VERSION ""

NS_ :

BS_:

BU_: DSAU vHS_M SHVU_RR DPSS AMP ICC RLPSM APSM RWPC RRHV RRPSM CGW_CCU APSS ATS RLHV FPM RDC PSM ASAU

BO_ 1141 Ast_SHVU_01_200ms: 8 APSM
 SG_ Ast_SHVU_SeatOptSta : 0|3@1+ (1,0) [0|0] ""  CGW_CCU
 SG_ Ast_SHVU_HtSwHiIndSta : 12|2@1+ (1,0) [0|0] ""  CGW_CCU
 SG_ Ast_SHVU_HtSwMidIndSta : 14|2@1+ (1,0) [0|0] ""  CGW_CCU
 SG_ Ast_SHVU_HtSwLowIndSta : 16|2@1+ (1,0) [0|0] ""  CGW_CCU
 SG_ Ast_SHVU_VntSwHiIndSta : 18|2@1+ (1,0) [0|0] ""  CGW_CCU
 SG_ Ast_SHVU_VntSwMidIndSta : 20|2@1+ (1,0) [0|0] ""  CGW_CCU
 SG_ Ast_SHVU_VntSwLowIndSta : 22|2@1+ (1,0) [0|0] ""  CGW_CCU
 SG_ Ast_SHVU_HtBlcUSMSta : 26|4@1+ (1,0) [0|0] ""  CGW_CCU
 SG_ Ast_SHVU_SeatHtOperSta : 3|4@1+ (1,0) [0|0] ""  CGW_CCU
 SG_ Ast_SHVU_SeatOptSta_RHD : 32|3@1+ (1,0) [0|0] ""  CGW_CCU
 SG_ Ast_SHVU_SeatHtOperSta_RHD : 35|4@1+ (1,0) [0|0] ""  CGW_CCU
 SG_ Ast_SHVU_HtSwHiIndSta_RHD : 44|2@1+ (1,0) [0|0] ""  CGW_CCU
 SG_ Ast_SHVU_HtSwMidIndSta_RHD : 46|2@1+ (1,0) [0|0] ""  CGW_CCU
 SG_ Ast_SHVU_HtSwLowIndSta_RHD : 48|2@1+ (1,0) [0|0] ""  CGW_CCU
 SG_ Ast_SHVU_VntSwHiIndSta_RHD : 50|2@1+ (1,0) [0|0] ""  CGW_CCU
 SG_ Ast_SHVU_VntSwMidIndSta_RHD : 52|2@1+ (1,0) [0|0] ""  CGW_CCU
 SG_ Ast_SHVU_VntSwLowIndSta_RHD : 54|2@1+ (1,0) [0|0] ""  CGW_CCU

BO_ 543 ATS_02_200ms: 8 ATS
 SG_ ATS_AstStSldFwdBtn : 16|2@1+ (1,0) [0|0] ""  APSM
 SG_ ATS_AstStSldBwdBtn : 18|2@1+ (1,0) [0|0] ""  APSM
 SG_ ATS_AstStRclFwdBtn : 20|2@1+ (1,0) [0|0] ""  APSM
 SG_ ATS_AstStRclBwdBtn : 22|2@1+ (1,0) [0|0] ""  APSM
 SG_ ATS_AstStHgtUpBtn : 28|2@1+ (1,0) [0|0] ""  APSM
 SG_ ATS_AstStHgtDnBtn : 30|2@1+ (1,0) [0|0] ""  APSM
 SG_ ATS_AstStHRestUpBtn : 40|2@1+ (1,0) [0|0] ""  APSM
 SG_ ATS_AstStHRestDnBtn : 42|2@1+ (1,0) [0|0] ""  APSM
 SG_ ATS_AstStHRestFwdBtn : 44|2@1+ (1,0) [0|0] ""  APSM
 SG_ ATS_AstStHRestBwdBtn : 46|2@1+ (1,0) [0|0] ""  APSM
 SG_ ATS_AstStHRestFldBtn : 48|2@1+ (1,0) [0|0] ""  APSM
 SG_ ATS_AstStHRestUnFldBtn : 50|2@1+ (1,0) [0|0] ""  APSM
 SG_ ATS_AstStRseFwdBtn : 52|2@1+ (1,0) [0|0] ""  APSM
 SG_ ATS_AstStRseBwdBtn : 54|2@1+ (1,0) [0|0] ""  APSM
 SG_ ATS_AstStFRestFldBtn : 56|2@1+ (1,0) [0|0] ""  APSM
 SG_ ATS_AstStFRestUnFldBtn : 58|2@1+ (1,0) [0|0] ""  APSM
 SG_ ATS_AstTltUpBtn : 60|2@1+ (1,0) [0|0] ""  APSM
 SG_ ATS_AstTltDnBtn : 62|2@1+ (1,0) [0|0] ""  APSM

BO_ 2315421185 HU_FPM_PE_00_1: 8 CGW_CCU
 SG_ AVN_ReadyToSendData : 0|2@1+ (1,0) [0|0] ""  FPM
 SG_ AVN_ISKLearnState : 2|3@1+ (1,0) [0|0] ""  FPM

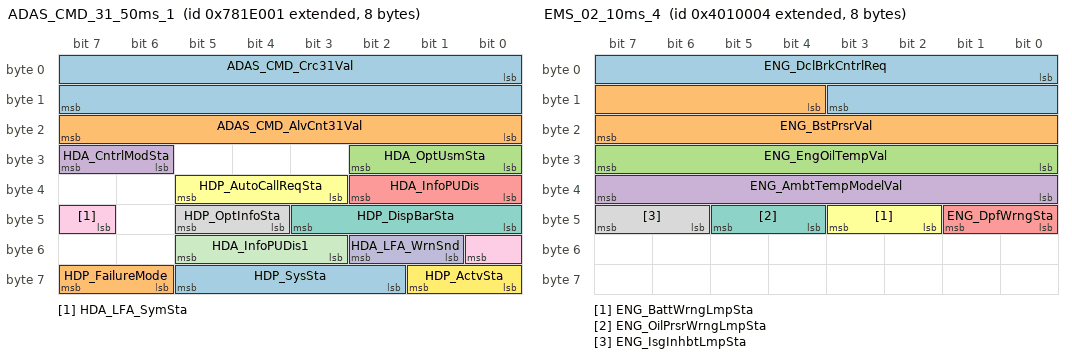
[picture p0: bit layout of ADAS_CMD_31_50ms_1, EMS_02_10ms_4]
BO_ 2273435649 ADAS_CMD_31_50ms_1: 8 CGW_CCU
 SG_ ADAS_CMD_Crc31Val : 0|16@1+ (1,0) [0|0] ""  Vector__XXX
 SG_ ADAS_CMD_AlvCnt31Val : 16|8@1+ (1,0) [0|0] ""  Vector__XXX
 SG_ HDA_OptUsmSta : 24|3@1+ (1,0) [0|0] ""  Vector__XXX
 SG_ HDA_CntrlModSta : 30|2@1+ (1,0) [0|0] ""  Vector__XXX
 SG_ HDA_InfoPUDis : 32|3@1+ (1,0) [0|0] ""  AMP
 SG_ HDP_AutoCallReqSta : 35|3@1+ (1,0) [0|0] ""  Vector__XXX
 SG_ HDP_DispBarSta : 40|4@1+ (1,0) [0|0] ""  Vector__XXX
 SG_ HDP_OptInfoSta : 44|2@1+ (1,0) [0|0] ""  Vector__XXX
 SG_ HDA_LFA_SymSta : 47|2@1+ (1,0) [0|0] ""  Vector__XXX
 SG_ HDA_LFA_WrnSnd : 49|2@1+ (1,0) [0|0] ""  Vector__XXX
 SG_ HDA_InfoPUDis1 : 51|3@1+ (1,0) [0|0] ""  AMP
 SG_ HDP_ActvSta : 56|2@1+ (1,0) [0|0] ""  Vector__XXX
 SG_ HDP_SysSta : 58|4@1+ (1,0) [0|0] ""  Vector__XXX
 SG_ HDP_FailureMode : 62|2@1+ (1,0) [0|0] ""  Vector__XXX

BO_ 2214658052 EMS_02_10ms_4: 8 CGW_CCU
 SG_ ENG_DclBrkCntrlReq : 0|12@1+ (0.001,-4.094) [0|0] "m/s^2"  Vector__XXX
 SG_ ENG_BstPrsrVal : 12|12@1+ (1.322,0) [0|0] "hPa"  Vector__XXX
 SG_ ENG_EngOilTempVal : 24|8@1+ (0.75,-40) [0|0] "℃"  Vector__XXX
 SG_ ENG_AmbtTempModelVal : 32|8@1+ (0.5,-41) [0|0] "℃"  Vector__XXX
 SG_ ENG_DpfWrngSta : 40|2@1+ (1,0) [0|0] ""  Vector__XXX
 SG_ ENG_BattWrngLmpSta : 42|2@1+ (1,0) [0|0] ""  Vector__XXX
 SG_ ENG_OilPrsrWrngLmpSta : 44|2@1+ (1,0) [0|0] ""  Vector__XXX
 SG_ ENG_IsgInhbtLmpSta : 46|2@1+ (1,0) [0|0] ""  Vector__XXX

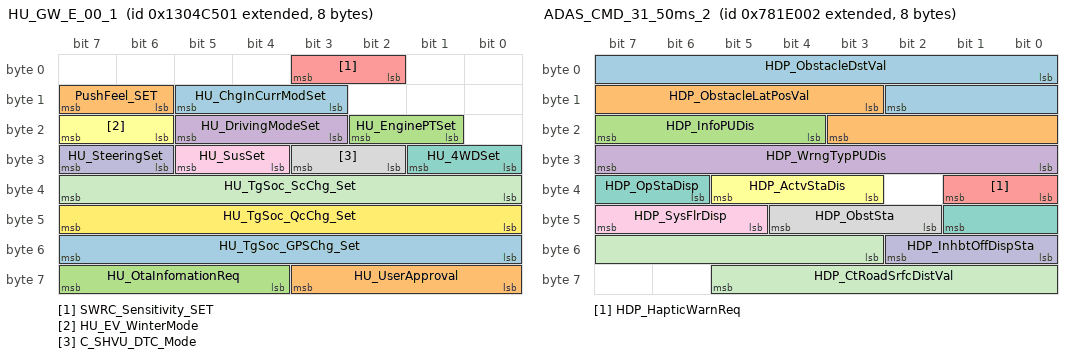
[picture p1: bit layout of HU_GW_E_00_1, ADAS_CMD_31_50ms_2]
BO_ 2466563329 HU_GW_E_00_1: 8 CGW_CCU
 SG_ HU_ChgInCurrModSet : 11|3@1+ (1,0) [0|0] ""  Vector__XXX
 SG_ PushFeel_SET : 14|2@1+ (1,0) [0|0] ""  Vector__XXX
 SG_ HU_EnginePTSet : 17|2@1+ (1,0) [0|0] ""  Vector__XXX
 SG_ HU_DrivingModeSet : 19|3@1+ (1,0) [0|0] ""  Vector__XXX
 SG_ SWRC_Sensitivity_SET : 2|2@1+ (1,0) [0|0] ""  Vector__XXX
 SG_ HU_EV_WinterMode : 22|2@1+ (1,0) [0|0] ""  Vector__XXX
 SG_ HU_4WDSet : 24|2@1+ (1,0) [0|0] ""  Vector__XXX
 SG_ C_SHVU_DTC_Mode : 26|2@1+ (1,0) [0|0] ""  SHVU_RR,ATS
 SG_ HU_SusSet : 28|2@1+ (1,0) [0|0] ""  Vector__XXX
 SG_ HU_SteeringSet : 30|2@1+ (1,0) [0|0] ""  Vector__XXX
 SG_ HU_TgSoc_ScChg_Set : 32|8@1+ (0.5,0) [0|100] "%"  Vector__XXX
 SG_ HU_TgSoc_QcChg_Set : 40|8@1+ (0.5,0) [0|100] "%"  Vector__XXX
 SG_ HU_TgSoc_GPSChg_Set : 48|8@1+ (0.5,0) [0|100] "%"  Vector__XXX
 SG_ HU_UserApproval : 56|4@1+ (1,0) [0|0] ""  Vector__XXX
 SG_ HU_OtaInfomationReq : 60|4@1+ (1,0) [0|0] ""  Vector__XXX

BO_ 2273435650 ADAS_CMD_31_50ms_2: 8 CGW_CCU
 SG_ HDP_ObstacleDstVal : 0|11@1+ (0.1,0) [0|0] "m"  Vector__XXX
 SG_ HDP_ObstacleLatPosVal : 11|9@1+ (0.1,-20) [0|0] "m"  Vector__XXX
 SG_ HDP_InfoPUDis : 20|4@1+ (1,0) [0|0] ""  Vector__XXX
 SG_ HDP_WrngTypPUDis : 24|8@1+ (1,0) [0|0] ""  Vector__XXX
 SG_ HDP_HapticWarnReq : 32|2@1+ (1,0) [0|0] ""  DSAU
 SG_ HDP_ActvStaDis : 35|3@1+ (1,0) [0|0] ""  Vector__XXX
 SG_ HDP_OpStaDisp : 38|4@1+ (1,0) [0|0] ""  Vector__XXX
 SG_ HDP_ObstSta : 42|3@1+ (1,0) [0|0] ""  Vector__XXX
 SG_ HDP_SysFlrDisp : 45|3@1+ (1,0) [0|0] ""  Vector__XXX
 SG_ HDP_InhbtOffDispSta : 48|3@1+ (1,0) [0|0] ""  Vector__XXX
 SG_ HDP_CtRoadSrfcDistVal : 51|11@1+ (1,0) [0|0] ""  Vector__XXX

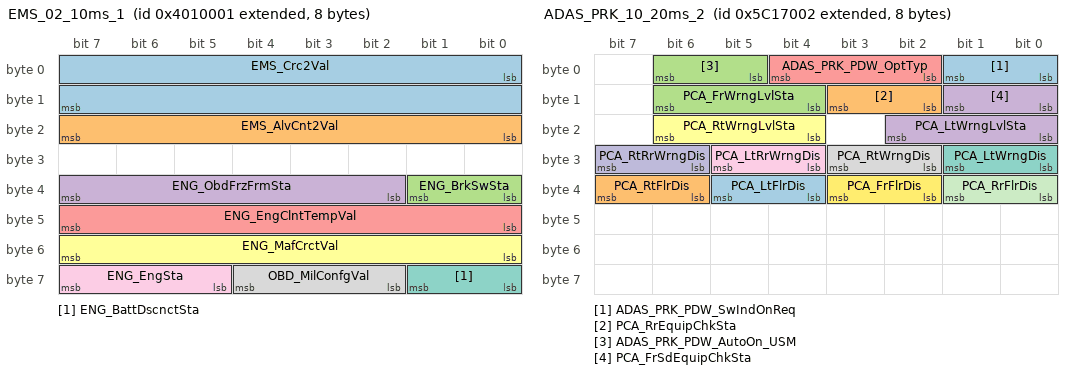
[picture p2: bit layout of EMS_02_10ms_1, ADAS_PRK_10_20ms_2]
BO_ 2214658049 EMS_02_10ms_1: 8 CGW_CCU
 SG_ EMS_Crc2Val : 0|16@1+ (1,0) [0|0] ""  Vector__XXX
 SG_ EMS_AlvCnt2Val : 16|8@1+ (1,0) [0|0] ""  Vector__XXX
 SG_ ENG_BrkSwSta : 32|2@1+ (1,0) [0|0] ""  ICC
 SG_ ENG_ObdFrzFrmSta : 34|6@1+ (1,0) [0|0] ""  Vector__XXX
 SG_ ENG_EngClntTempVal : 40|8@1+ (0.75,-48) [0|0] "℃"  Vector__XXX
 SG_ ENG_MafCrctVal : 48|8@1+ (0.00781,0) [0|0] ""  Vector__XXX
 SG_ ENG_BattDscnctSta : 56|2@1+ (1,0) [0|0] ""  Vector__XXX
 SG_ OBD_MilConfgVal : 58|3@1+ (1,0) [0|0] ""  Vector__XXX
 SG_ ENG_EngSta : 61|3@1+ (1,0) [0|0] ""  RWPC,PSM,APSM,RLPSM,RRPSM,RLHV,RRHV,SHVU_RR,RDC,DPSS

BO_ 2244046850 ADAS_PRK_10_20ms_2: 8 CGW_CCU
 SG_ ADAS_PRK_PDW_SwIndOnReq : 0|2@1+ (1,0) [0|0] ""  Vector__XXX
 SG_ PCA_RrEquipChkSta : 10|2@1+ (1,0) [0|0] ""  Vector__XXX
 SG_ PCA_FrWrngLvlSta : 12|3@1+ (1,0) [0|0] ""  Vector__XXX
 SG_ PCA_LtWrngLvlSta : 16|3@1+ (1,0) [0|0] ""  Vector__XXX
 SG_ ADAS_PRK_PDW_OptTyp : 2|3@1+ (1,0) [0|0] ""  Vector__XXX
 SG_ PCA_RtWrngLvlSta : 20|3@1+ (1,0) [0|0] ""  Vector__XXX
 SG_ PCA_LtWrngDis : 24|2@1+ (1,0) [0|0] ""  Vector__XXX
 SG_ PCA_RtWrngDis : 26|2@1+ (1,0) [0|0] ""  Vector__XXX
 SG_ PCA_LtRrWrngDis : 28|2@1+ (1,0) [0|0] ""  Vector__XXX
 SG_ PCA_RtRrWrngDis : 30|2@1+ (1,0) [0|0] ""  Vector__XXX
 SG_ PCA_RrFlrDis : 32|2@1+ (1,0) [0|0] ""  Vector__XXX
 SG_ PCA_FrFlrDis : 34|2@1+ (1,0) [0|0] ""  Vector__XXX
 SG_ PCA_LtFlrDis : 36|2@1+ (1,0) [0|0] ""  Vector__XXX
 SG_ PCA_RtFlrDis : 38|2@1+ (1,0) [0|0] ""  Vector__XXX
 SG_ ADAS_PRK_PDW_AutoOn_USM : 5|2@1+ (1,0) [0|0] ""  Vector__XXX
 SG_ PCA_FrSdEquipChkSta : 8|2@1+ (1,0) [0|0] ""  Vector__XXX

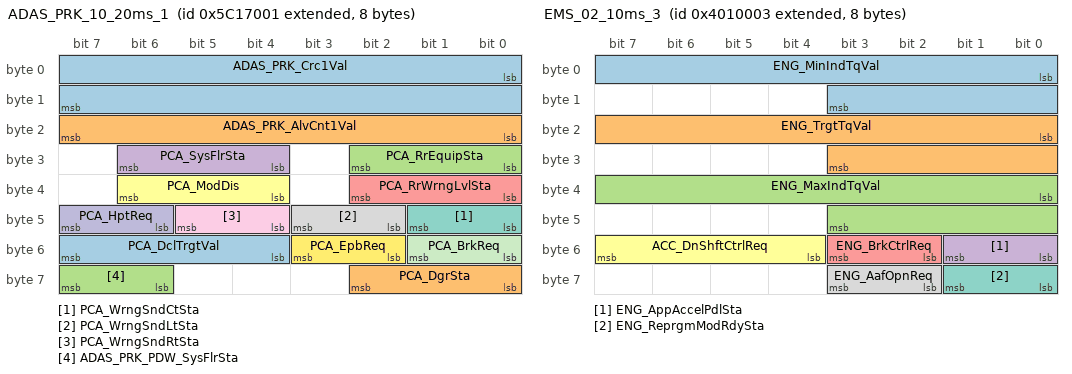
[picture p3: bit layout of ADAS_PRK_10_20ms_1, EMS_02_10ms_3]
BO_ 2244046849 ADAS_PRK_10_20ms_1: 8 CGW_CCU
 SG_ ADAS_PRK_Crc1Val : 0|16@1+ (1,0) [0|0] ""  Vector__XXX
 SG_ ADAS_PRK_AlvCnt1Val : 16|8@1+ (1,0) [0|0] ""  Vector__XXX
 SG_ PCA_RrEquipSta : 24|3@1+ (1,0) [0|0] ""  Vector__XXX
 SG_ PCA_SysFlrSta : 28|3@1+ (1,0) [0|0] ""  Vector__XXX
 SG_ PCA_RrWrngLvlSta : 32|3@1+ (1,0) [0|0] ""  Vector__XXX
 SG_ PCA_ModDis : 36|3@1+ (1,0) [0|0] ""  Vector__XXX
 SG_ PCA_WrngSndCtSta : 40|2@1+ (1,0) [0|0] ""  AMP
 SG_ PCA_WrngSndLtSta : 42|2@1+ (1,0) [0|0] ""  AMP
 SG_ PCA_WrngSndRtSta : 44|2@1+ (1,0) [0|0] ""  AMP
 SG_ PCA_HptReq : 46|2@1+ (1,0) [0|0] ""  Vector__XXX
 SG_ PCA_BrkReq : 48|2@1+ (1,0) [0|0] ""  Vector__XXX
 SG_ PCA_EpbReq : 50|2@1+ (1,0) [0|0] ""  Vector__XXX
 SG_ PCA_DclTrgtVal : 52|4@1+ (0.04,0) [0|0] "g"  Vector__XXX
 SG_ PCA_DgrSta : 56|3@1+ (1,0) [0|0] ""  Vector__XXX
 SG_ ADAS_PRK_PDW_SysFlrSta : 62|2@1+ (1,0) [0|0] ""  Vector__XXX

BO_ 2214658051 EMS_02_10ms_3: 8 CGW_CCU
 SG_ ENG_MinIndTqVal : 0|12@1- (1,0) [0|0] "Nm"  AMP
 SG_ ENG_TrgtTqVal : 16|12@1- (1,0) [0|0] "Nm"  Vector__XXX
 SG_ ENG_MaxIndTqVal : 32|12@1- (1,0) [0|0] "Nm"  AMP
 SG_ ENG_AppAccelPdlSta : 48|2@1+ (1,0) [0|0] ""  Vector__XXX
 SG_ ENG_BrkCtrlReq : 50|2@1+ (1,0) [0|0] ""  Vector__XXX
 SG_ ACC_DnShftCtrlReq : 52|4@1+ (1,0) [0|0] ""  Vector__XXX
 SG_ ENG_ReprgmModRdySta : 56|2@1+ (1,0) [0|0] ""  Vector__XXX
 SG_ ENG_AafOpnReq : 58|2@1+ (1,0) [0|0] ""  Vector__XXX

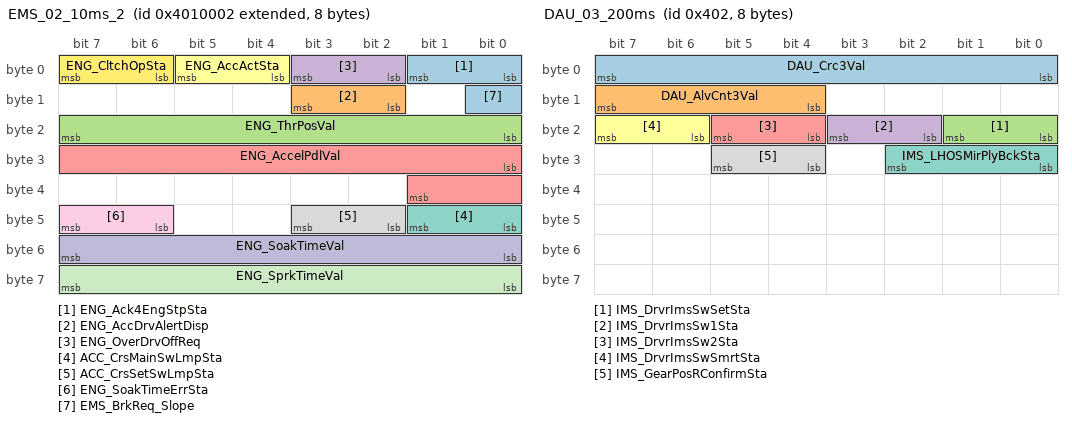
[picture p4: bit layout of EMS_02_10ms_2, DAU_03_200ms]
BO_ 2214658050 EMS_02_10ms_2: 8 CGW_CCU
 SG_ ENG_Ack4EngStpSta : 0|2@1+ (1,0) [0|0] ""  Vector__XXX
 SG_ ENG_AccDrvAlertDisp : 10|2@1+ (1,0) [0|0] ""  Vector__XXX
 SG_ ENG_ThrPosVal : 16|8@1+ (0.4694836,-15.0234742) [0|0] "%"  Vector__XXX
 SG_ ENG_OverDrvOffReq : 2|2@1+ (1,0) [0|0] ""  Vector__XXX
 SG_ ENG_AccelPdlVal : 24|10@1+ (0.09784,0) [0|0] "%"  AMP,ICC
 SG_ ENG_AccActSta : 4|2@1+ (1,0) [0|0] ""  Vector__XXX
 SG_ ACC_CrsMainSwLmpSta : 40|2@1+ (1,0) [0|0] ""  Vector__XXX
 SG_ ACC_CrsSetSwLmpSta : 42|2@1+ (1,0) [0|0] ""  Vector__XXX
 SG_ ENG_SoakTimeErrSta : 46|2@1+ (1,0) [0|0] ""  Vector__XXX
 SG_ ENG_SoakTimeVal : 48|8@1+ (1,0) [0|0] "Min"  Vector__XXX
 SG_ ENG_SprkTimeVal : 56|8@1+ (0.375,-35.625) [0|0] "˚"  Vector__XXX
 SG_ ENG_CltchOpSta : 6|2@1+ (1,0) [0|0] ""  Vector__XXX
 SG_ EMS_BrkReq_Slope : 8|1@1+ (1,0) [0|0] ""  Vector__XXX

BO_ 1026 DAU_03_200ms: 8 CGW_CCU
 SG_ DAU_Crc3Val : 0|8@1+ (1,0) [0|0] ""  PSM
 SG_ DAU_AlvCnt3Val : 12|4@1+ (1,0) [0|0] ""  PSM
 SG_ IMS_DrvrImsSwSetSta : 16|2@1+ (1,0) [0|0] ""  DPSS
 SG_ IMS_DrvrImsSw1Sta : 18|2@1+ (1,0) [0|0] ""  PSM
 SG_ IMS_DrvrImsSw2Sta : 20|2@1+ (1,0) [0|0] ""  PSM
 SG_ IMS_DrvrImsSwSmrtSta : 22|2@1+ (1,0) [0|0] ""  PSM
 SG_ IMS_LHOSMirPlyBckSta : 24|3@1+ (1,0) [0|0] ""  Vector__XXX
 SG_ IMS_GearPosRConfirmSta : 28|2@1+ (1,0) [0|0] ""  Vector__XXX

BO_ 1027 DAU_04_200ms: 8 CGW_CCU
 SG_ DAU_Crc4Val : 0|8@1+ (1,0) [0|0] ""  Vector__XXX
 SG_ DAU_AlvCnt4Val : 12|4@1+ (1,0) [0|0] ""  Vector__XXX
 SG_ Window_AsstPwrWdwAutoSwSta : 16|2@1+ (1,0) [0|0] ""  Vector__XXX
 SG_ Window_AsstPwrWdwUpSwSta : 18|2@1+ (1,0) [0|0] ""  Vector__XXX
 SG_ Window_AsstPwrWdwDnSwSta : 20|2@1+ (1,0) [0|0] ""  Vector__XXX
 SG_ Window_RrCrtSwSta : 22|2@1+ (1,0) [0|0] ""  Vector__XXX
 SG_ Window_RrLftPwrWdwAutoSwSta : 24|2@1+ (1,0) [0|0] ""  RDC
 SG_ Window_RrLftPwrWdwUpSwSta : 26|2@1+ (1,0) [0|0] ""  RDC
 SG_ Window_RrLftPwrWdwDnSwSta : 28|2@1+ (1,0) [0|0] ""  RDC
 SG_ Window_RrRtPwrWdwAutoSwSta : 32|2@1+ (1,0) [0|0] ""  RDC
 SG_ Window_RrRtPwrWdwUpSwSta : 34|2@1+ (1,0) [0|0] ""  RDC
 SG_ Window_RrRtPwrWdwDnSwSta : 36|2@1+ (1,0) [0|0] ""  RDC
 SG_ Window_PwrWdwMaintainSta : 40|2@1+ (1,0) [0|0] ""  RDC
 SG_ Window_PwrWdwMvInhbtSta : 42|2@1+ (1,0) [0|0] ""  RDC,ATS
 SG_ Window_WdwSafetyOpt : 44|3@1+ (1,0) [0|0] ""  Vector__XXX
 SG_ Window_DrvPwrWdwAutoSwSta : 48|2@1+ (1,0) [0|0] ""  Vector__XXX
 SG_ Window_DrvPwrWdwUpSwSta : 50|2@1+ (1,0) [0|0] ""  Vector__XXX
 SG_ Window_DrvPwrWdwDnSwSta : 52|2@1+ (1,0) [0|0] ""  Vector__XXX

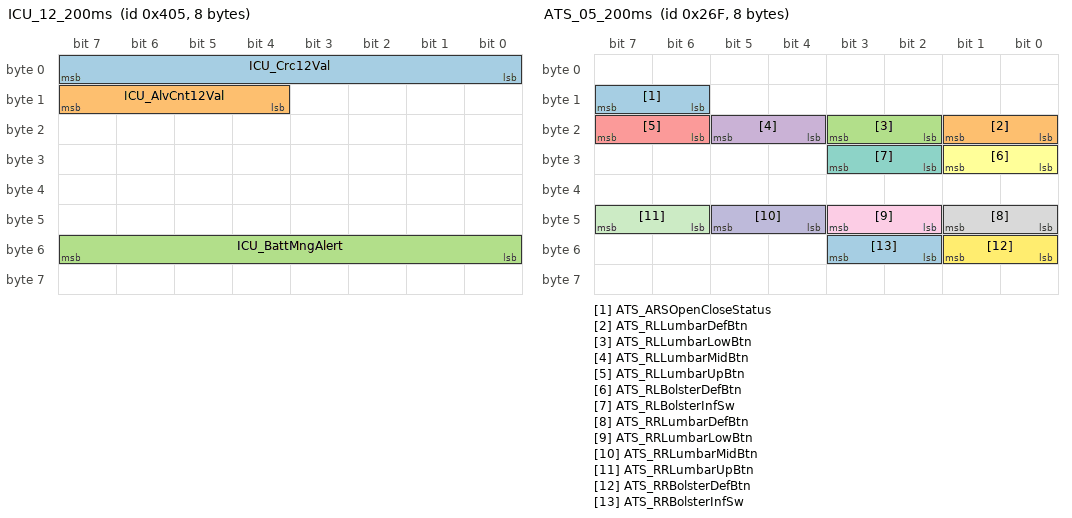
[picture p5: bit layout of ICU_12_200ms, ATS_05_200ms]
BO_ 1029 ICU_12_200ms: 8 CGW_CCU
 SG_ ICU_Crc12Val : 0|8@1+ (1,0) [0|0] ""  vHS_M
 SG_ ICU_AlvCnt12Val : 12|4@1+ (1,0) [0|0] ""  Vector__XXX
 SG_ ICU_BattMngAlert : 48|8@1+ (1,0) [0|0] ""  Vector__XXX

BO_ 623 ATS_05_200ms: 8 ATS
 SG_ ATS_ARSOpenCloseStatus : 14|2@1+ (1,0) [0|0] ""  RLPSM
 SG_ ATS_RLLumbarDefBtn : 16|2@1+ (1,0) [0|0] ""  RLPSM
 SG_ ATS_RLLumbarLowBtn : 18|2@1+ (1,0) [0|0] ""  RLPSM
 SG_ ATS_RLLumbarMidBtn : 20|2@1+ (1,0) [0|0] ""  RLPSM
 SG_ ATS_RLLumbarUpBtn : 22|2@1+ (1,0) [0|0] ""  RLPSM
 SG_ ATS_RLBolsterDefBtn : 24|2@1+ (1,0) [0|0] ""  RLPSM
 SG_ ATS_RLBolsterInfSw : 26|2@1+ (1,0) [0|0] ""  RLPSM
 SG_ ATS_RRLumbarDefBtn : 40|2@1+ (1,0) [0|0] ""  RLPSM
 SG_ ATS_RRLumbarLowBtn : 42|2@1+ (1,0) [0|0] ""  RLPSM
 SG_ ATS_RRLumbarMidBtn : 44|2@1+ (1,0) [0|0] ""  RLPSM
 SG_ ATS_RRLumbarUpBtn : 46|2@1+ (1,0) [0|0] ""  RLPSM
 SG_ ATS_RRBolsterDefBtn : 48|2@1+ (1,0) [0|0] ""  RLPSM
 SG_ ATS_RRBolsterInfSw : 50|2@1+ (1,0) [0|0] ""  RLPSM

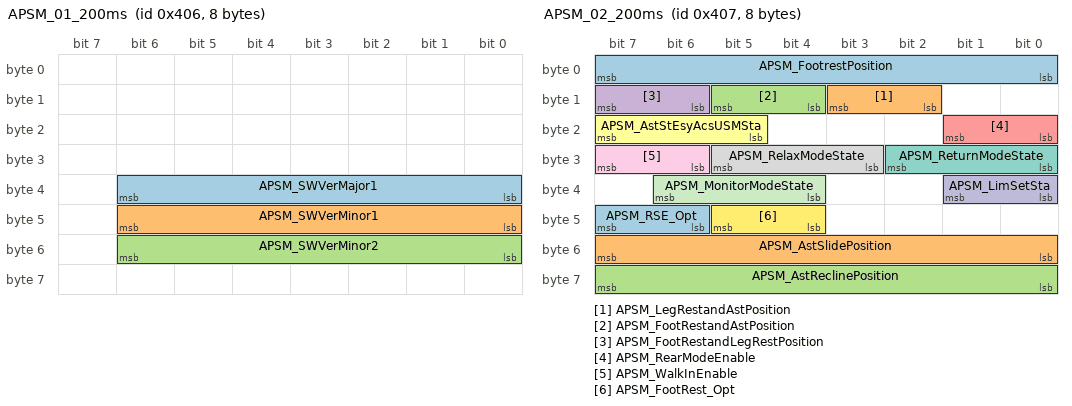
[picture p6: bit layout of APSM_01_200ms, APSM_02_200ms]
BO_ 1030 APSM_01_200ms: 8 APSM
 SG_ APSM_SWVerMajor1 : 32|7@1+ (1,0) [0|0] ""  CGW_CCU
 SG_ APSM_SWVerMinor1 : 40|7@1+ (1,0) [0|0] ""  CGW_CCU
 SG_ APSM_SWVerMinor2 : 48|7@1+ (1,0) [0|0] ""  CGW_CCU

BO_ 1031 APSM_02_200ms: 8 APSM
 SG_ APSM_FootrestPosition : 0|8@1+ (1,0) [0|0] ""  ASAU,ATS,RRPSM,CGW_CCU
 SG_ APSM_LegRestandAstPosition : 10|2@1+ (1,0) [0|0] ""  ATS,RRPSM,CGW_CCU
 SG_ APSM_FootRestandAstPosition : 12|2@1+ (1,0) [0|0] ""  ATS,RRPSM,CGW_CCU
 SG_ APSM_FootRestandLegRestPosition : 14|2@1+ (1,0) [0|0] ""  ATS,RRPSM,CGW_CCU
 SG_ APSM_RearModeEnable : 16|2@1+ (1,0) [0|0] ""  RRPSM
 SG_ APSM_AstStEsyAcsUSMSta : 21|3@1+ (1,0) [0|0] ""  CGW_CCU
 SG_ APSM_ReturnModeState : 24|3@1+ (1,0) [0|0] ""  RRPSM
 SG_ APSM_RelaxModeState : 27|3@1+ (1,0) [0|0] ""  RRPSM
 SG_ APSM_WalkInEnable : 30|2@1+ (1,0) [0|0] ""  RRPSM
 SG_ APSM_LimSetSta : 32|2@1+ (1,0) [0|0] ""  ATS,RRPSM
 SG_ APSM_MonitorModeState : 36|3@1+ (1,0) [0|0] ""  RRPSM
 SG_ APSM_FootRest_Opt : 44|2@1+ (1,0) [0|0] ""  ATS,CGW_CCU
 SG_ APSM_RSE_Opt : 46|2@1+ (1,0) [0|0] ""  ATS,CGW_CCU
 SG_ APSM_AstSlidePosition : 48|8@1+ (1,0) [0|0] ""  RRPSM,CGW_CCU
 SG_ APSM_AstReclinePosition : 56|8@1+ (1,0) [0|0] ""  RRPSM,CGW_CCU

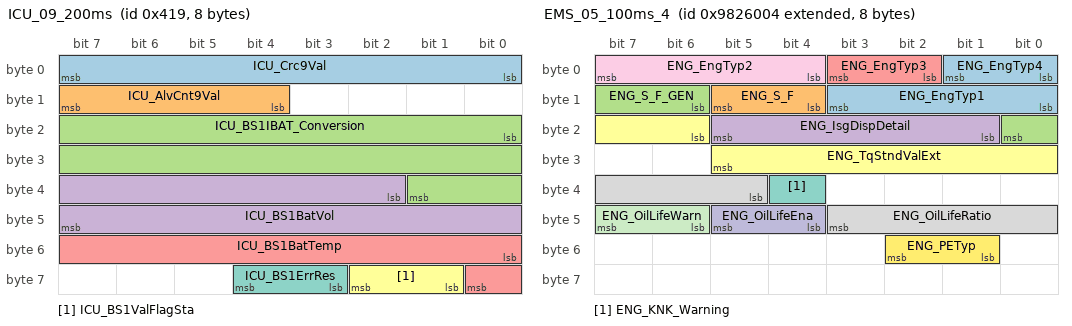
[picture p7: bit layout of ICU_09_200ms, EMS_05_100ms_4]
BO_ 1049 ICU_09_200ms: 8 CGW_CCU
 SG_ ICU_Crc9Val : 0|8@1+ (1,0) [0|0] ""  vHS_M
 SG_ ICU_AlvCnt9Val : 12|4@1+ (1,0) [0|0] ""  Vector__XXX
 SG_ ICU_BS1IBAT_Conversion : 16|18@1+ (10,-1200000) [0|0] "mA"  Vector__XXX
 SG_ ICU_BS1BatVol : 34|14@1+ (0.001,6) [0|0] ""  Vector__XXX
 SG_ ICU_BS1BatTemp : 48|9@1+ (0.5,-40) [0|0] ""  Vector__XXX
 SG_ ICU_BS1ValFlagSta : 57|2@1+ (1,0) [0|0] ""  Vector__XXX
 SG_ ICU_BS1ErrRes : 59|2@1+ (1,0) [0|0] ""  Vector__XXX

BO_ 2315419649 HU_FPM_E_00_1: 8 CGW_CCU
 SG_ AVN_Random : 16|48@1+ (1,0) [0|0] ""  FPM

BO_ 2307022852 EMS_05_100ms_4: 8 CGW_CCU
 SG_ ENG_EngTyp4 : 0|2@1+ (1,0) [0|0] ""  Vector__XXX
 SG_ ENG_S_F : 12|2@1+ (1,0) [0|0] ""  Vector__XXX
 SG_ ENG_S_F_GEN : 14|3@1+ (1,0) [0|0] ""  Vector__XXX
 SG_ ENG_IsgDispDetail : 17|5@1+ (1,0) [0|0] ""  Vector__XXX
 SG_ ENG_EngTyp3 : 2|2@1+ (1,0) [0|0] ""  Vector__XXX
 SG_ ENG_TqStndValExt : 22|8@1+ (10,0) [0|0] ""  AMP
 SG_ ENG_KNK_Warning : 36|1@1+ (1,0) [0|0] ""  Vector__XXX
 SG_ ENG_OilLifeRatio : 37|7@1+ (1,0) [0|0] "%"  Vector__XXX
 SG_ ENG_EngTyp2 : 4|4@1+ (1,0) [0|0] ""  AMP
 SG_ ENG_OilLifeEna : 44|2@1+ (1,0) [0|0] ""  Vector__XXX
 SG_ ENG_OilLifeWarn : 46|2@1+ (1,0) [0|0] ""  Vector__XXX
 SG_ ENG_PETyp : 49|2@1+ (1,0) [0|0] ""  Vector__XXX
 SG_ ENG_EngTyp1 : 8|4@1+ (1,0) [0|0] ""  AMP

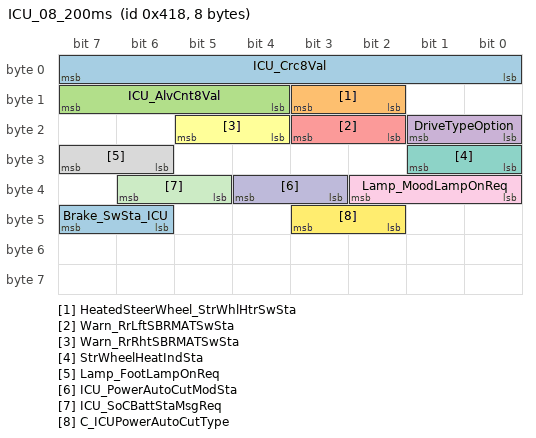
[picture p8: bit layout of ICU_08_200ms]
BO_ 1048 ICU_08_200ms: 8 CGW_CCU
 SG_ ICU_Crc8Val : 0|8@1+ (1,0) [0|0] ""  vHS_M
 SG_ HeatedSteerWheel_StrWhlHtrSwSta : 10|2@1+ (1,0) [0|0] ""  Vector__XXX
 SG_ ICU_AlvCnt8Val : 12|4@1+ (1,0) [0|0] ""  Vector__XXX
 SG_ DriveTypeOption : 16|2@1+ (1,0) [0|0] ""  PSM,RLPSM,RRPSM,SHVU_RR,ATS
 SG_ Warn_RrLftSBRMATSwSta : 18|2@1+ (1,0) [0|0] ""  Vector__XXX
 SG_ Warn_RrRhtSBRMATSwSta : 20|2@1+ (1,0) [0|0] ""  Vector__XXX
 SG_ StrWheelHeatIndSta : 24|2@1+ (1,0) [0|0] ""  Vector__XXX
 SG_ Lamp_FootLampOnReq : 30|2@1+ (1,0) [0|0] ""  Vector__XXX
 SG_ Lamp_MoodLampOnReq : 32|3@1+ (1,0) [0|0] ""  Vector__XXX
 SG_ ICU_PowerAutoCutModSta : 35|2@1+ (1,0) [0|0] ""  Vector__XXX
 SG_ ICU_SoCBattStaMsgReq : 37|2@1+ (1,0) [0|0] ""  Vector__XXX
 SG_ C_ICUPowerAutoCutType : 42|2@1+ (1,0) [0|0] ""  Vector__XXX
 SG_ Brake_SwSta_ICU : 46|2@1+ (1,0) [0|0] ""  Vector__XXX

CM_ BO_ 2273435649 "[P] Periodic";
CM_ SG_ 2273435649 ADAS_CMD_Crc31Val "ADAS_CMD_CyclicRedundancyCheck31Value";
CM_ SG_ 2273435649 ADAS_CMD_AlvCnt31Val "ADAS_CMD_AliveCounter31Value";
CM_ SG_ 2273435649 HDA_OptUsmSta "HDA_OptionUSMStatus ##2G##LDW_LKA - HDA11 - CF_HDA_Opt_USM";
CM_ SG_ 2273435649 HDA_CntrlModSta "HDA_ControlModeStatus ##2G##LDW_LKA - HDA11 - CF_HDA_Mode";
CM_ SG_ 2273435649 HDA_InfoPUDis "HDA_InformationPopUpDisplay ##2G##LDW_LKA - HDA11 - CF_HDA_InfoDisplay";
CM_ SG_ 2273435649 HDP_AutoCallReqSta "HDP Auto Call Request State";
CM_ SG_ 2273435649 HDP_DispBarSta "HDP Display Bar State";
CM_ SG_ 2273435649 HDP_OptInfoSta "HDP Option Infomation State";
CM_ SG_ 2273435649 HDA_LFA_SymSta "HDA_LFA_SymbolStatus ##2G##LDW_LKA - HDA11 - CF_HDA_LFA_SymbolState";
CM_ SG_ 2273435649 HDA_LFA_WrnSnd "HDA/LFA Additional Warning Sound";
CM_ SG_ 2273435649 HDA_InfoPUDis1 "HDA_InfomationPopupDisplay";
CM_ SG_ 2273435649 HDP_ActvSta "HDP_ControlActiveStatus";
CM_ SG_ 2273435649 HDP_SysSta "HDP_SystemStatus";
CM_ BO_ 2273435650 "[P] Periodic";
CM_ SG_ 2273435650 HDP_ObstacleDstVal "HDP_InPathObstacleDistance";
CM_ SG_ 2273435650 HDP_ObstacleLatPosVal "HDP_InPathObstaclePositionValue";
CM_ SG_ 2273435650 HDP_InfoPUDis "HDP_InformationPopupDisplay (main pop-up)";
CM_ SG_ 2273435650 HDP_WrngTypPUDis "HDP_WarningTypePopupDisplay (mini pop-up)";
CM_ SG_ 2273435650 HDP_HapticWarnReq "Request for HDP haptic warning";
CM_ SG_ 2273435650 HDP_ActvStaDis "HDP_Active/Deactive Status Display";
CM_ SG_ 2273435650 HDP_OpStaDisp "HDP Operation State Display";
CM_ SG_ 2273435650 HDP_ObstSta "HDP Obstacle State";
CM_ SG_ 2273435650 HDP_SysFlrDisp "HDP System Failure Display";
CM_ SG_ 2273435650 HDP_InhbtOffDispSta "HDP Inhibit Off Display State";
CM_ SG_ 2273435650 HDP_CtRoadSrfcDistVal "HDP Center Road Surface Distance Value";
CM_ BO_ 2244046849 "[P] Periodic";
CM_ SG_ 2244046849 ADAS_PRK_Crc1Val "ADAS_PRK_CyclicRedundancyCheck1Value";
CM_ SG_ 2244046849 ADAS_PRK_AlvCnt1Val "ADAs_PRK_AliveCounter1Value";
CM_ SG_ 2244046849 PCA_RrEquipSta "PCA_RearEquipmentStatus";
CM_ SG_ 2244046849 PCA_SysFlrSta "PCA_SystemFailureStatus";
CM_ SG_ 2244046849 PCA_RrWrngLvlSta "PCA_RearWarningLevelStatus";
CM_ SG_ 2244046849 PCA_ModDis "PCA_ ModeDisplay";
CM_ SG_ 2244046849 PCA_WrngSndCtSta "PCA_WarningSoundCenterStatus";
CM_ SG_ 2244046849 PCA_WrngSndLtSta "PCA_WarningSoundLeftStatus";
CM_ SG_ 2244046849 PCA_WrngSndRtSta "PCA_WarningSoundRightStatus";
CM_ SG_ 2244046849 PCA_HptReq "PCA_HapticRequest";
CM_ SG_ 2244046849 PCA_BrkReq "PCA_BrakeRequest";
CM_ SG_ 2244046849 PCA_EpbReq "PCA_EPBRequest";
CM_ SG_ 2244046849 PCA_DclTrgtVal "PCA_DecelerationTargetValue";
CM_ SG_ 2244046849 PCA_DgrSta "PCA_DegreeStatus";
CM_ SG_ 2244046849 ADAS_PRK_PDW_SysFlrSta "PDW System Failure State";
CM_ BO_ 2244046850 "[P] Periodic";
CM_ SG_ 2244046850 PCA_RrEquipChkSta "PCA RearEquipmentCheckStatus";
CM_ SG_ 2244046850 PCA_FrWrngLvlSta "PCA_FrontWarningLevelStatus";
CM_ SG_ 2244046850 PCA_LtWrngLvlSta "PCA_LeftWarningLevelStatus";
CM_ SG_ 2244046850 ADAS_PRK_PDW_OptTyp "Option information for None, PDW-R, PDW-FR, PDW-FSR";
CM_ SG_ 2244046850 PCA_RtWrngLvlSta "PCA_RightWarningLevelStatus";
CM_ SG_ 2244046850 PCA_LtWrngDis "PCA_LeftWarningDisplay";
CM_ SG_ 2244046850 PCA_RtWrngDis "PCA_RightWarningDisplay";
CM_ SG_ 2244046850 PCA_LtRrWrngDis "PCA_LeftRearWarningDisplay";
CM_ SG_ 2244046850 PCA_RtRrWrngDis "PCA_RightRearWarningDisplay";
CM_ SG_ 2244046850 PCA_RrFlrDis "PCA_RearFailureDisplay";
CM_ SG_ 2244046850 PCA_FrFlrDis "PCA_FrontFailureDisplay";
CM_ SG_ 2244046850 PCA_LtFlrDis "PCA_LeftFailureDisplay";
CM_ SG_ 2244046850 PCA_RtFlrDis "PCA_RightFailureDisplay";
CM_ SG_ 2244046850 PCA_FrSdEquipChkSta "PCA_FrontSideEquipmentCheckStatus";
CM_ BO_ 1030 "[PE] Periodic and On Event";
CM_ SG_ 1030 APSM_SWVerMajor1 "First Word(ASCII) in APSM S/W Ver";
CM_ SG_ 1030 APSM_SWVerMinor1 "Second Word(ASCII) in APSM S/W Ver";
CM_ SG_ 1030 APSM_SWVerMinor2 "Third Word(ASCII) in APSM S/W Ver";
CM_ BO_ 1031 "[PE] Periodic and On Event";
CM_ SG_ 1031 APSM_AstStEsyAcsUSMSta "USM_MovingValue";
CM_ SG_ 1031 APSM_LimSetSta "APSM limit setting state";
CM_ SG_ 1031 APSM_FootRest_Opt "Foot Rest OPTION";
CM_ SG_ 1031 APSM_RSE_Opt "RSE OPTION";
CM_ BO_ 543 "[PE] Periodic and On Event";
CM_ SG_ 543 ATS_AstStSldFwdBtn "Assist Power Seat Slide Forward Rear Walk In Button";
CM_ SG_ 543 ATS_AstStSldBwdBtn "Assist Power Seat Slide Backward Rear Walk In Button";
CM_ SG_ 543 ATS_AstStRclFwdBtn "Assist Power Seat Recline Forward Rear Walk In Button";
CM_ SG_ 543 ATS_AstStRclBwdBtn "Assist Power Seat Recline Backward Rear Walk In Button";
CM_ SG_ 543 ATS_AstStHgtUpBtn "Assist Power Seat Height Up Walk In Button";
CM_ SG_ 543 ATS_AstStHgtDnBtn "Assist Power Seat Height Dn Walk In Button";
CM_ SG_ 543 ATS_AstStHRestUpBtn "Assist Power Seat Head Rest Up Walk In Button";
CM_ SG_ 543 ATS_AstStHRestDnBtn "Assist Power Seat  Head Rest Dn Walk In Button";
CM_ SG_ 543 ATS_AstStHRestFwdBtn "Assist Power Seat Head Rest Forward  Walk In Button";
CM_ SG_ 543 ATS_AstStHRestBwdBtn "Assist Power Seat Head Rest Backward  Walk In Button";
CM_ SG_ 543 ATS_AstStHRestFldBtn "Assist Power Seat Head Rest Folding  Walk In Button";
CM_ SG_ 543 ATS_AstStHRestUnFldBtn "Assist Power Seat Head Rest Unfolding  Walk In Button";
CM_ SG_ 543 ATS_AstStRseFwdBtn "Assist Power Seat RSE Forward  Walk In Button";
CM_ SG_ 543 ATS_AstStRseBwdBtn "Assist Power Seat RSE Backward Walk In Button";
CM_ SG_ 543 ATS_AstStFRestFldBtn "Assist Power Seat Foot Rest Folding Walk In Button";
CM_ SG_ 543 ATS_AstStFRestUnFldBtn "Assist Power Seat Foot Rest Unfolding Walk In Button";
CM_ SG_ 543 ATS_AstTltUpBtn "Assist Power Seat  Tilt Up Walk In Button";
CM_ SG_ 543 ATS_AstTltDnBtn "Assist Power Seat Tilt Down  Walk In Button";
CM_ BO_ 623 "[PE] Periodic and On Event";
CM_ SG_ 623 ATS_ARSOpenCloseStatus "Armrest Open / Close Status";
CM_ SG_ 623 ATS_RLLumbarDefBtn "Rear Left Lumbar Deflation Touch Button";
CM_ SG_ 623 ATS_RLLumbarLowBtn "Rear Left Lumbar Low Touch Button";
CM_ SG_ 623 ATS_RLLumbarMidBtn "Rear Left Lumbar Middle Touch Button";
CM_ SG_ 623 ATS_RLLumbarUpBtn "Rear Left Lumbar Up Touch Button";
CM_ SG_ 623 ATS_RLBolsterDefBtn "Rear Left Bolster Deflation Touch Button";
CM_ SG_ 623 ATS_RLBolsterInfSw "Rear Left Bolster Inflation Touch Button";
CM_ SG_ 623 ATS_RRLumbarDefBtn "Rear Right Lumbar Deflation Touch Button";
CM_ SG_ 623 ATS_RRLumbarLowBtn "Rear Right Lumbar Low Touch Button";
CM_ SG_ 623 ATS_RRLumbarMidBtn "Rear Right Lumbar Middle Touch Button";
CM_ SG_ 623 ATS_RRLumbarUpBtn "Rear Right Lumbar Up Touch Button";
CM_ SG_ 623 ATS_RRBolsterDefBtn "Rear Right Bolster Deflation Touch Button";
CM_ SG_ 623 ATS_RRBolsterInfSw "Rear Right Bolster Inflation Touch Button";
CM_ BO_ 1141 "[PE] Periodic and On Event";
CM_ SG_ 1141 Ast_SHVU_SeatOptSta "Ast Seat Heater/Vent option info";
CM_ SG_ 1141 Ast_SHVU_HtSwHiIndSta "Ast Seat Heater Switch High Indicator Status";
CM_ SG_ 1141 Ast_SHVU_HtSwMidIndSta "Ast Seat Heater Switch Mid Indicator Status";
CM_ SG_ 1141 Ast_SHVU_HtSwLowIndSta "Ast Seat Heater Switch Low Indicator Status";
CM_ SG_ 1141 Ast_SHVU_VntSwHiIndSta "Ast Seat Vent Switch High Indicator Status";
CM_ SG_ 1141 Ast_SHVU_VntSwMidIndSta "Ast Seat Vent Switch Mid Indicator Status";
CM_ SG_ 1141 Ast_SHVU_VntSwLowIndSta "Ast Seat Vent Switch Low Indicator Status";
CM_ SG_ 1141 Ast_SHVU_HtBlcUSMSta "Hetaer Balance Assistant USM R vaule";
CM_ SG_ 1141 Ast_SHVU_SeatHtOperSta "Ast Seat Heater/Vent current operation state";
CM_ SG_ 1141 Ast_SHVU_SeatOptSta_RHD "Ast Seat Heater/Vent option info (RHD)";
CM_ SG_ 1141 Ast_SHVU_SeatHtOperSta_RHD "Ast Seat Heater/Vent current operation state(RHD)";
CM_ SG_ 1141 Ast_SHVU_HtSwHiIndSta_RHD "Ast Seat Heater Switch High Indicator Status(RHD)";
CM_ SG_ 1141 Ast_SHVU_HtSwMidIndSta_RHD "Ast Seat Heater Switch Mid Indicator Status(RHD)";
CM_ SG_ 1141 Ast_SHVU_HtSwLowIndSta_RHD "Ast Seat Heater Switch Low Indicator Status(RHD)";
CM_ SG_ 1141 Ast_SHVU_VntSwHiIndSta_RHD "Ast Seat Vent Switch High Indicator Status(RHD)";
CM_ SG_ 1141 Ast_SHVU_VntSwMidIndSta_RHD "Ast Seat Vent Switch Mid Indicator Status(RHD)";
CM_ SG_ 1141 Ast_SHVU_VntSwLowIndSta_RHD "Ast Seat Vent Switch Low Indicator Status(RHD)";
CM_ BO_ 1026 "[PE] Periodic and On Event";
CM_ SG_ 1026 DAU_Crc3Val "DAU_CyclicRedundancyCheck3Value";
CM_ SG_ 1026 DAU_AlvCnt3Val "DAU_AliveCounter3Value";
CM_ SG_ 1026 IMS_DrvrImsSwSetSta "IMS_DrvrImsSwSetStatus ##2G##DDM -  - C_DrvIMSSWSet";
CM_ SG_ 1026 IMS_DrvrImsSw1Sta "IMS_DrvrImsSw1Status ##2G##DDM -  - C_DrvIMSSW1";
CM_ SG_ 1026 IMS_DrvrImsSw2Sta "IMS_DrvrImsSw2Status ##2G##DDM -  - C_DrvIMSSW2";
CM_ SG_ 1026 IMS_DrvrImsSwSmrtSta "IMS_DrvrImsSwSmartStatus ##2G##DDM -  - C_HCIMSSW";
CM_ SG_ 1026 IMS_GearPosRConfirmSta "Output_b_GearBoxRPosition_500msConfirmed";
CM_ BO_ 1027 "[PE] Periodic and On Event";
CM_ SG_ 1027 DAU_Crc4Val "DAU_CyclicRedundancyCheck4Value";
CM_ SG_ 1027 DAU_AlvCnt4Val "DAU_AliveCounter4Value";
CM_ SG_ 1027 Window_AsstPwrWdwAutoSwSta "Window_AssistPowerWindowAutoSwitchStatus ##2G##DDM -  - C_AstPwdwAutoSwDDM";
CM_ SG_ 1027 Window_AsstPwrWdwUpSwSta "Window_AssistantPowerWindowUpSwitchStatus ##2G##DDM -  - C_AstPwdwUpSwDDM";
CM_ SG_ 1027 Window_AsstPwrWdwDnSwSta "Window_AssistantPowerWindowDownSwitchStatus ##2G##DDM -  - C_AstPwdwDnSwDDM";
CM_ SG_ 1027 Window_RrCrtSwSta "Window_RearCurtainSwitchStatus";
CM_ SG_ 1027 Window_RrLftPwrWdwAutoSwSta "Window_RearLeftPowerWindowAutoSwitchStatus ##2G##DDM -  - C_RLPwdwAutoSwDDM";
CM_ SG_ 1027 Window_RrLftPwrWdwUpSwSta "Window_RearLeftPowerWindowUpSwitchStatus ##2G##DDM -  - C_RLPwdwUpSwDDM";
CM_ SG_ 1027 Window_RrLftPwrWdwDnSwSta "Window_RearLeftPowerWindowDownSwitchStatus ##2G##DDM -  - C_RLPwdwDnSwDDM";
CM_ SG_ 1027 Window_RrRtPwrWdwAutoSwSta "Window_RearRightPowerWindowAutoSwitchStatus ##2G##DDM -  - C_RRPwdwAutoSwDDM";
CM_ SG_ 1027 Window_RrRtPwrWdwUpSwSta "Window_RearRightPowerWindowUpSwitchStatus ##2G##DDM -  - C_RRPwdwUpSwDDM";
CM_ SG_ 1027 Window_RrRtPwrWdwDnSwSta "Window_RearRightPowerWindowDownSwitchStatus ##2G##DDM -  - C_RRPwdwDnSwDDM";
CM_ SG_ 1027 Window_PwrWdwMaintainSta "Window_DriverPowerWindowMaintainStatus ##2G##DDM -  - C_PwdwMaintain";
CM_ SG_ 1027 Window_PwrWdwMvInhbtSta "Window_PowerWindowMoveInhibitStatus ##2G##DDM -  - C_PwdwInhibit";
CM_ SG_ 1027 Window_DrvPwrWdwAutoSwSta "Window_DriverPowerWindowAutoSwitchStatus";
CM_ SG_ 1027 Window_DrvPwrWdwUpSwSta "Window_DriverPowerWindowUpSwitchStatus";
CM_ SG_ 1027 Window_DrvPwrWdwDnSwSta "Window_DriverPowerWindowDownSwitchStatus";
CM_ BO_ 2214658049 "[P] Periodic";
CM_ SG_ 2214658049 EMS_Crc2Val "EMS_CyclicRedundancyCheck2Value";
CM_ SG_ 2214658049 EMS_AlvCnt2Val "EMS_AliveCounter2Value";
CM_ SG_ 2214658049 ENG_BrkSwSta "ENG_BrakeSwitchStatus ##2G##EMS - EMS12 - BRAKE_ACT";
CM_ SG_ 2214658049 ENG_ObdFrzFrmSta "ENG_ObdFreezeFrameStatus ##2G##EMS - EMS12 - OBD_FRF_ACK";
CM_ SG_ 2214658049 ENG_EngClntTempVal "ENG_EngineCoolantTemperatureValue ##2G##EMS - EMS12 - TEMP_ENG";
CM_ SG_ 2214658049 ENG_MafCrctVal "ENG_MassAirFlowCorrectionValue ##2G##EMS - EMS12 - MAF_FAC_ALTI_MMV";
CM_ SG_ 2214658049 ENG_BattDscnctSta "ENG_BatteryDisconnectStatus ##2G##EMS - EMS12 - VB_OFF_ACT";
CM_ SG_ 2214658049 OBD_MilConfgVal "OBD_MalfunctionIndicationLampConfigurationValue ##2G##EMS - EMS12 - CONF_MIL_FMY";
CM_ SG_ 2214658049 ENG_EngSta "ENG_EngineStatus ##2G##EMS - EMS16 - ENG_STAT";
CM_ BO_ 2214658050 "[P] Periodic";
CM_ SG_ 2214658050 ENG_Ack4EngStpSta "ENG_AcknowledgeForEngineStopStatus ##2G##EMS - EMS12 - ACK_ES";
CM_ SG_ 2214658050 ENG_AccDrvAlertDisp "The status of No Auto cruise Engaged or Auto cruise Disengaged.";
CM_ SG_ 2214658050 ENG_ThrPosVal "ENG_ThrottlePositionValue ##2G##EMS - EMS12 - TPS";
CM_ SG_ 2214658050 ENG_OverDrvOffReq "ENG_OverDriveOffRequest ##2G##EMS - EMS12 - OD_OFF_REQ";
CM_ SG_ 2214658050 ENG_AccelPdlVal "ENG_AcceleratorPedalValue ##2G##EMS - EMS12 - PV_AV_CAN";
CM_ SG_ 2214658050 ENG_AccActSta "ENG_AutoCruiseControlActiveStatus ##2G##EMS - EMS12 - ACC_ACT";
CM_ SG_ 2214658050 ACC_CrsMainSwLmpSta "ACC_CruiseMainSwLampStatus ##2G##EMS - EMS16 - CRUISE_LAMP_M";
CM_ SG_ 2214658050 ACC_CrsSetSwLmpSta "ACC_CruiseSetSwLampStatus ##2G##EMS - EMS16 - CRUISE_LAMP_S";
CM_ SG_ 2214658050 ENG_SoakTimeErrSta "ENG_SoakTimeErrorStatus ##2G##EMS - EMS16 - SOAK_TIME_ERROR";
CM_ SG_ 2214658050 ENG_SoakTimeVal "ENG_SoakTimeValue ##2G##EMS - EMS16 - SOAK_TIME";
CM_ SG_ 2214658050 ENG_SprkTimeVal "ENG_SparkTimeValue ##2G##EMS - EMS16 - SPK_TIME_CUR";
CM_ SG_ 2214658050 ENG_CltchOpSta "ENG_ClutchStatus ##2G##EMS - EMS12 - CLU_ACK";
CM_ SG_ 2214658050 EMS_BrkReq_Slope "Brake request at slope for anti-stall";
CM_ BO_ 2214658051 "[P] Periodic";
CM_ SG_ 2214658051 ENG_MinIndTqVal "ENG_MinimumIndicatedTorqueValue ##2G##EMS - EMS16 - TQI_MIN";
CM_ SG_ 2214658051 ENG_TrgtTqVal "ENG_TargetTorqueValue ##2G##EMS - EMS16 - TQI_TARGET";
CM_ SG_ 2214658051 ENG_MaxIndTqVal "ENG_MaximumIndicatedTorqueValue ##2G##EMS - EMS16 - TQI_MAX";
CM_ SG_ 2214658051 ENG_AppAccelPdlSta "ENG_AppliedAcceleratorPedalStatus ##2G##EMS - EMS16 - CF_Ems_AclAct";
CM_ SG_ 2214658051 ENG_BrkCtrlReq "ENG_BrakeControlRequest ##2G##EMS - EMS19 - CF_Ems_BrkReq";
CM_ SG_ 2214658051 ACC_DnShftCtrlReq "ACC_DownShiftControlRequest ##2G##EMS - EMS19 - CF_Ems_DnShftReq";
CM_ SG_ 2214658051 ENG_ReprgmModRdySta "ENG_ReprogrammingModeReadyStatus ##2G##EMS - EMS19 - CF_Ems_RepModChk";
CM_ SG_ 2214658051 ENG_AafOpnReq "ENG_ActiveAirFlapOpenRequest ##2G##EMS - EMS19 - CF_Ems_AAFOpenReq";
CM_ BO_ 2214658052 "[P] Periodic";
CM_ SG_ 2214658052 ENG_DclBrkCntrlReq "ENG_DecelerationBrakeControlRequest ##2G##EMS - EMS19 - CF_Ems_DecelReq";
CM_ SG_ 2214658052 ENG_BstPrsrVal "ENG_BoostPressureValue ##2G##EMS - EMS19 - CR_Ems_BstPre";
CM_ SG_ 2214658052 ENG_EngOilTempVal "ENG_EngineOilTemperatureValue ##2G##EMS - EMS19 - CR_Ems_EngOilTemp";
CM_ SG_ 2214658052 ENG_AmbtTempModelVal "ENG_AmbientTemperatureModelValue ##2G##EMS - EMS19 - CF_Ems_ModeledAmbTemp";
CM_ SG_ 2214658052 ENG_DpfWrngSta "ENG_DpfWarningStatus ##2G##EMS - EMS19 - DPF_LAMP_STAT";
CM_ SG_ 2214658052 ENG_BattWrngLmpSta "ENG_BatteryWarningLampStatus ##2G##EMS - EMS19 - BAT_LAMP_STAT";
CM_ SG_ 2214658052 ENG_OilPrsrWrngLmpSta "ENG_OilPressureWarningLampStatus ##2G##EMS - EMS19 - CF_Ems_OPSFail";
CM_ SG_ 2214658052 ENG_IsgInhbtLmpSta "ENG_IsgInhibitLampStatus ##2G##EMS - EMS19 - ISG_INHIBIT_LAMP_STAT";
CM_ BO_ 2307022852 "[P] Periodic";
CM_ SG_ 2307022852 ENG_EngTyp4 "ENG_EngineType4";
CM_ SG_ 2307022852 ENG_S_F "AMS/ISG system type indicator";
CM_ SG_ 2307022852 ENG_S_F_GEN "system generation type indicator";
CM_ SG_ 2307022852 ENG_IsgDispDetail "Detailed information of ISG status";
CM_ SG_ 2307022852 ENG_EngTyp3 "ENG_EngineType3";
CM_ SG_ 2307022852 ENG_TqStndValExt "ENG_TorqueStandardValue (Extended signal) ##2G##EMS - EMS12 - TQ_STND";
CM_ SG_ 2307022852 ENG_KNK_Warning "This signal indicates the result of KNK diagnosis. (KSDS)";
CM_ SG_ 2307022852 ENG_OilLifeRatio "Remaining engine oil life with % unit";
CM_ SG_ 2307022852 ENG_EngTyp2 "ENG_EngineType2 ##2G##EMS - EMS23 - ENG_TYPE";
CM_ SG_ 2307022852 ENG_OilLifeEna "Enabling information if engine oil life monitoring from EMS is applied or not";
CM_ SG_ 2307022852 ENG_OilLifeWarn "Request to activate engine oil life warning";
CM_ SG_ 2307022852 ENG_PETyp "PE_Type";
CM_ SG_ 2307022852 ENG_EngTyp1 "ENG_EngineType1 ##2G##EMS - EMS12 - ENG_CHR";
CM_ BO_ 2315419649 "[EC] On Event and On Change";
CM_ BO_ 2315421185 "[PE] Periodic and On Event";
CM_ BO_ 2466563329 "[EC] On Event and On Change";
CM_ SG_ 2466563329 HU_ChgInCurrModSet "Charge current set signal";
CM_ SG_ 2466563329 PushFeel_SET "PushFeel setting";
CM_ SG_ 2466563329 HU_EnginePTSet "Command for Driving mode Engine / PT setting";
CM_ SG_ 2466563329 HU_DrivingModeSet "Command for Driving mode setting to ECS(Electronic Control Suspension)";
CM_ SG_ 2466563329 SWRC_Sensitivity_SET "SWRC_OpticalSwtich_Sensitivity_Setting";
CM_ SG_ 2466563329 HU_EV_WinterMode "<For after OS/DE/SK3 EV/AE PE EV>

EV Battery temp. up setting on/off 
- setting signal : CR_Bms_WinterMode";
CM_ SG_ 2466563329 HU_4WDSet "Command for Driving mode 4WD Setting";
CM_ SG_ 2466563329 C_SHVU_DTC_Mode "HU diagnosis request to seat";
CM_ SG_ 2466563329 HU_SusSet "Command for Driving mode suspension setting";
CM_ SG_ 2466563329 HU_SteeringSet "Command for Driving mode Steering setting";
CM_ SG_ 2466563329 HU_TgSoc_ScChg_Set "<For after OS/DE/SK3 EV>
Target SOC user setting value for slow charger(SC/AC).
- For EV only";
CM_ SG_ 2466563329 HU_TgSoc_QcChg_Set "<For after OS/DE/SK3 EV>
Target SOC user setting value for fast charger(QC/DC).
- For EV only";
CM_ SG_ 2466563329 HU_TgSoc_GPSChg_Set "<For after OS/DE/SK3 EV/ AE EV PE>
Target SOC user setting value for GPS scheduled charger.
- For EV/PHEV";
CM_ BO_ 1048 "[PE] Periodic and On Event";
CM_ SG_ 1048 ICU_Crc8Val "ICU_CyclicRedundancyCheck8Value";
CM_ SG_ 1048 HeatedSteerWheel_StrWhlHtrSwSta "Use for Telematics Remote Heating Control ##2G## -  - C_StrgWhlHeatedState";
CM_ SG_ 1048 ICU_AlvCnt8Val "ICU_AliveCounter8Value";
CM_ SG_ 1048 DriveTypeOption "##2G## -  - C_DriveTypeOption,CF_Gway_DriveTypeOption";
CM_ SG_ 1048 Warn_RrLftSBRMATSwSta "##2G## -  - C_RLSBRMatSw";
CM_ SG_ 1048 Warn_RrRhtSBRMATSwSta "##2G## -  - C_RRSBRMatSw";
CM_ SG_ 1048 StrWheelHeatIndSta "##2G## -  - C_StrgWhlHeatedInd";
CM_ SG_ 1048 Lamp_FootLampOnReq "##2G## -  - C_FootLpOn";
CM_ SG_ 1048 Lamp_MoodLampOnReq "##2G## -  - C_MoodLpOn";
CM_ SG_ 1048 ICU_PowerAutoCutModSta "##2G## -  - CF_Gway_ICUPowerAutoCutMode";
CM_ SG_ 1048 ICU_SoCBattStaMsgReq "##2G## -  - Batt_SoCWarningAlertMsgReq";
CM_ SG_ 1048 Brake_SwSta_ICU "Brake Switch Status ##2G## -  - C_BrakeSw";
CM_ BO_ 1049 "[PE] Periodic and On Event";
CM_ SG_ 1049 ICU_Crc9Val "ICU_CyclicRedundancyCheck9Value";
CM_ SG_ 1049 ICU_AlvCnt9Val "ICU_AliveCounter9Value";
CM_ SG_ 1049 ICU_BS1IBAT_Conversion "Actual battery current (resolution: 10mA)";
CM_ SG_ 1049 ICU_BS1BatVol "This is the actual battery voltage as measured on the battery pole by battery sensor. ##2G## -  - BS1_VBAT";
CM_ SG_ 1049 ICU_BS1BatTemp "This is actual battery electrolyte temperature value by battery sensor. ##2G## -  - BS1_TBAT";
CM_ SG_ 1049 ICU_BS1ValFlagSta "setting condition is depending on battery sensor self diagnosis information ##2G## -  - BS1_BSInvalidFlag";
CM_ SG_ 1049 ICU_BS1ErrRes "Response_Error shall be set whenever a frame received by the node or a frame transmitted by the node contains an error in the response field. ##2G## -  - BS1_ErrorResp";
CM_ BO_ 1029 "[PE] Periodic and On Event";
CM_ SG_ 1029 ICU_Crc12Val "ICU_CyclicRedundancyCheck12Value";
CM_ SG_ 1029 ICU_AlvCnt12Val "ICU_AliveCounter12Value";
CM_ SG_ 1029 ICU_BattMngAlert "This signal is for battery discharge warning.";
BA_DEF_ BO_ "DiagState" ENUM "No","Yes" ;
BA_DEF_ BO_ "DiagResponse" ENUM "No","Yes" ;
BA_DEF_ BO_ "DiagRequest" ENUM "No","Yes" ;
BA_DEF_ BO_ "TpMessage" ENUM "No","Yes" ;
BA_DEF_ BO_ "UsrMsgIDSforwardDeviation" INT 0 100 ;
BA_DEF_ BO_ "UsrMsgIDSbackwardDeviation" INT 50 1000 ;
BA_DEF_ BO_ "GenMsgCycleTime" INT 0 2000 ;
BA_DEF_ BO_ "GenMsgStartDelayTime" INT 0 2000 ;
BA_DEF_ BO_ "GenMsgSendType" ENUM "Cyclic","NoMsgSendType" ;
BA_DEF_ BO_ "GenMsgCycleTimeFast" INT 0 500 ;
BA_DEF_ BO_ "GenMsgDelayTime" INT 0 20 ;
BA_DEF_ BO_ "GenMsgILSupport" ENUM "No","Yes" ;
BA_DEF_ BO_ "GenMsgNrOfRepetition" INT 0 3 ;
BA_DEF_ BO_ "NmMessage" ENUM "No","Yes" ;
BA_DEF_ BO_ "NWM-Botschaft" ENUM "No","Yes" ;
BA_DEF_ BO_ "TpTxIndex" INT 0 255 ;
BA_DEF_ BO_ "VFrameFormat" ENUM "StandardCAN","ExtendedCAN","reserved","reserved","reserved","reserved","reserved","reserved","reserved","reserved","reserved","reserved","reserved","reserved","StandardCAN_FD","ExtendedCAN_FD" ;
BA_DEF_ SG_ "UserSigValidity" ENUM "B+","ACC","IG","IG1","IG2","IG3","IG1 or IG2","IG1 or IG3","Undef" ;
BA_DEF_ SG_ "TimeoutValue" STRING ;
BA_DEF_ SG_ "UsrSigPurpose" ENUM "Undef","FN","DIAG","DIAG(Req)","DIAG(Res)","DIAG(Phy)","DEV","CCP(Req)","CCP(Res)","NM","TP" ;
BA_DEF_ SG_ "GenSigStartValue" INT 0 1215752192 ;
BA_DEF_ SG_ "NetworkRequest" ENUM "Yes","No" ;
BA_DEF_ SG_ "NetworkRequestHoldingTime" INT 0 65535 ;
BA_DEF_ SG_ "Description" STRING ;
BA_DEF_ SG_ "Version" STRING ;
BA_DEF_ SG_ "GenSigEnvVarType" ENUM "Int","Float","Undef" ;
BA_DEF_ SG_ "GenSigSendType" ENUM "Cyclic","OnWrite","OnWriteWithRepetition","OnChange","OnChangeWithRepetition","IfActive","IfActiveWithRepetition","NoSigSendType","OnChangeAndIfActive","OnChangeAndIfActiveWithRepetition" ;
BA_DEF_ SG_ "GwSigLatencyTime" INT 0 65536 ;
BA_DEF_ SG_ "GwSigMissingSourceType" ENUM "Undef","OldValue","DefaultValue","InitialValue" ;
BA_DEF_ SG_ "NWM-WakeupAllowed" ENUM "<n.a.>" ;
BA_DEF_ SG_ "RoutingFactor" INT 1 1215752192 ;
BA_DEF_REL_ BU_SG_REL_ "GenSigTimeoutTime" INT 0 7000 ;
BA_DEF_DEF_ "DiagState" "No" ;
BA_DEF_DEF_ "DiagResponse" "No" ;
BA_DEF_DEF_ "DiagRequest" "No" ;
BA_DEF_DEF_ "TpMessage" "No" ;
BA_DEF_DEF_ "UsrMsgIDSforwardDeviation" 10 ;
BA_DEF_DEF_ "UsrMsgIDSbackwardDeviation" 100 ;
BA_DEF_DEF_ "GenMsgCycleTime" 200 ;
BA_DEF_DEF_ "GenMsgStartDelayTime" 0 ;
BA_DEF_DEF_ "GenMsgSendType" "NoMsgSendType" ;
BA_DEF_DEF_ "GenMsgCycleTimeFast" 40 ;
BA_DEF_DEF_ "GenMsgDelayTime" 20 ;
BA_DEF_DEF_ "GenMsgILSupport" "Yes" ;
BA_DEF_DEF_ "GenMsgNrOfRepetition" 3 ;
BA_DEF_DEF_ "NmMessage" "No" ;
BA_DEF_DEF_ "NWM-Botschaft" "No" ;
BA_DEF_DEF_ "TpTxIndex" 0 ;
BA_DEF_DEF_ "VFrameFormat" "StandardCAN" ;
BA_DEF_DEF_ "UserSigValidity" "IG" ;
BA_DEF_DEF_ "TimeoutValue" "" ;
BA_DEF_DEF_ "UsrSigPurpose" "FN" ;
BA_DEF_DEF_ "GenSigStartValue" 0 ;
BA_DEF_DEF_ "NetworkRequest" "No" ;
BA_DEF_DEF_ "NetworkRequestHoldingTime" 0 ;
BA_DEF_DEF_ "Description" "" ;
BA_DEF_DEF_ "Version" "" ;
BA_DEF_DEF_ "GenSigEnvVarType" "Undef" ;
BA_DEF_DEF_ "GenSigSendType" "NoSigSendType" ;
BA_DEF_DEF_ "GwSigLatencyTime" 40 ;
BA_DEF_DEF_ "GwSigMissingSourceType" "Undef" ;
BA_DEF_DEF_ "NWM-WakeupAllowed" "<n.a.>" ;
BA_DEF_DEF_ "RoutingFactor" 1 ;
BA_DEF_DEF_REL_ "GenSigTimeoutTime" 500 ;
BA_ "GenMsgSendType" BO_ 2273435649 0;
BA_ "GenMsgCycleTime" BO_ 2273435649 150;
BA_ "GenMsgCycleTimeFast" BO_ 2273435649 0;
BA_ "GenMsgNrOfRepetition" BO_ 2273435649 0;
BA_ "VFrameFormat" BO_ 2273435649 1;
BA_ "Description" SG_ 2273435649 ADAS_CMD_Crc31Val "The data area for CRC calculation is based on the data length (DLC) of the message DB.

The CRC shall be calculated over the entire data block (excluding the CRC bytes) including the user data, alive counter and Data ID

 

- CRC Polynomial (0x1021) , Initial Value : 0xFFFF, XOR value : 0x0000, Data ID : Message ID + 0xF800 

- The initial value is for CRC calculation and the message should be sent with the calculated result value. 

- The mathematical expression to 16 bit CRC polynomial is given here. G(x) = x16 + x12 + x5 + 1";
BA_ "UserSigValidity" SG_ 2273435649 ADAS_CMD_Crc31Val 3;
BA_ "RoutingFactor" SG_ 2273435649 ADAS_CMD_Crc31Val 3;
BA_ "Version" SG_ 2273435649 ADAS_CMD_Crc31Val "18.11.08";
BA_ "Description" SG_ 2273435649 ADAS_CMD_AlvCnt31Val "For the first transmission request for a data element the counter shall be initialized with 0 and shall be incremented by 1 for every subsequent send request. 

When the counter reaches the maximum value(0xFF), then it shall restart with 0 for the next send request";
BA_ "UserSigValidity" SG_ 2273435649 ADAS_CMD_AlvCnt31Val 3;
BA_ "RoutingFactor" SG_ 2273435649 ADAS_CMD_AlvCnt31Val 3;
BA_ "Version" SG_ 2273435649 ADAS_CMD_AlvCnt31Val "18.11.08";
BA_ "Description" SG_ 2273435649 HDA_OptUsmSta "This is HDA system status needed for the cluster USM display.";
BA_ "UserSigValidity" SG_ 2273435649 HDA_OptUsmSta 3;
BA_ "RoutingFactor" SG_ 2273435649 HDA_OptUsmSta 3;
BA_ "Version" SG_ 2273435649 HDA_OptUsmSta "17.12.02";
BA_ "Description" SG_ 2273435649 HDA_CntrlModSta "This is HDA Control Mode needed for longitudinal/lateral control and cluster display.";
BA_ "UserSigValidity" SG_ 2273435649 HDA_CntrlModSta 3;
BA_ "RoutingFactor" SG_ 2273435649 HDA_CntrlModSta 3;
BA_ "Version" SG_ 2273435649 HDA_CntrlModSta "21.01.08";
BA_ "Description" SG_ 2273435649 HDA_InfoPUDis "This is HDA information display needed for the cluster pop-up display.";
BA_ "UserSigValidity" SG_ 2273435649 HDA_InfoPUDis 3;
BA_REL_ "GenSigTimeoutTime" BU_SG_REL_ AMP SG_ 2273435649 HDA_InfoPUDis 1500;
BA_ "RoutingFactor" SG_ 2273435649 HDA_InfoPUDis 3;
BA_ "Version" SG_ 2273435649 HDA_InfoPUDis "19.03.06";
BA_ "Description" SG_ 2273435649 HDP_AutoCallReqSta "This signal is needed for HDP Auto Call.";
BA_ "UserSigValidity" SG_ 2273435649 HDP_AutoCallReqSta 3;
BA_ "RoutingFactor" SG_ 2273435649 HDP_AutoCallReqSta 3;
BA_ "Version" SG_ 2273435649 HDP_AutoCallReqSta "21.04.03";
BA_ "Description" SG_ 2273435649 HDP_DispBarSta "This signal indicates HDP operation state (always not covered other display)";
BA_ "UserSigValidity" SG_ 2273435649 HDP_DispBarSta 0;
BA_ "RoutingFactor" SG_ 2273435649 HDP_DispBarSta 3;
BA_ "Version" SG_ 2273435649 HDP_DispBarSta "21.03.11";
BA_ "Description" SG_ 2273435649 HDP_OptInfoSta "This signal indicates whether the HDP system has been applied or not.";
BA_ "UserSigValidity" SG_ 2273435649 HDP_OptInfoSta 0;
BA_ "RoutingFactor" SG_ 2273435649 HDP_OptInfoSta 3;
BA_ "Version" SG_ 2273435649 HDP_OptInfoSta "21.03.11";
BA_ "Description" SG_ 2273435649 HDA_LFA_SymSta "This signal shows the state of steering assist.";
BA_ "UserSigValidity" SG_ 2273435649 HDA_LFA_SymSta 3;
BA_ "RoutingFactor" SG_ 2273435649 HDA_LFA_SymSta 3;
BA_ "Version" SG_ 2273435649 HDA_LFA_SymSta "20.11.02";
BA_ "Description" SG_ 2273435649 HDA_LFA_WrnSnd "HDA/LFA Additional Warning Sound";
BA_ "UserSigValidity" SG_ 2273435649 HDA_LFA_WrnSnd 3;
BA_ "RoutingFactor" SG_ 2273435649 HDA_LFA_WrnSnd 3;
BA_ "Version" SG_ 2273435649 HDA_LFA_WrnSnd "18.02.03";
BA_ "Description" SG_ 2273435649 HDA_InfoPUDis1 "This is HDA/LFA information display needed for the cluster pop-up display.";
BA_ "UserSigValidity" SG_ 2273435649 HDA_InfoPUDis1 3;
BA_REL_ "GenSigTimeoutTime" BU_SG_REL_ AMP SG_ 2273435649 HDA_InfoPUDis1 1500;
BA_ "RoutingFactor" SG_ 2273435649 HDA_InfoPUDis1 3;
BA_ "Version" SG_ 2273435649 HDA_InfoPUDis1 "18.10.00";
BA_ "Description" SG_ 2273435649 HDP_ActvSta "This signal indicates control active status of HDP.";
BA_ "UserSigValidity" SG_ 2273435649 HDP_ActvSta 3;
BA_ "RoutingFactor" SG_ 2273435649 HDP_ActvSta 3;
BA_ "Version" SG_ 2273435649 HDP_ActvSta "19.11.02";
BA_ "Description" SG_ 2273435649 HDP_SysSta "This signal indicates system status of HDP.";
BA_ "UserSigValidity" SG_ 2273435649 HDP_SysSta 3;
BA_ "RoutingFactor" SG_ 2273435649 HDP_SysSta 3;
BA_ "Version" SG_ 2273435649 HDP_SysSta "21.01.08";
BA_ "Description" SG_ 2273435649 HDP_FailureMode "This signal shows HDP failure status";
BA_ "UserSigValidity" SG_ 2273435649 HDP_FailureMode 3;
BA_ "RoutingFactor" SG_ 2273435649 HDP_FailureMode 3;
BA_ "Version" SG_ 2273435649 HDP_FailureMode "20.07.10";
BA_ "GenMsgSendType" BO_ 2273435650 0;
BA_ "GenMsgCycleTime" BO_ 2273435650 150;
BA_ "GenMsgCycleTimeFast" BO_ 2273435650 0;
BA_ "GenMsgNrOfRepetition" BO_ 2273435650 0;
BA_ "VFrameFormat" BO_ 2273435650 1;
BA_ "Description" SG_ 2273435650 HDP_ObstacleDstVal "This signal indicates distance to a obstacle which is on driving path.";
BA_ "GenSigStartValue" SG_ 2273435650 HDP_ObstacleDstVal 2046;
BA_ "UserSigValidity" SG_ 2273435650 HDP_ObstacleDstVal 3;
BA_ "RoutingFactor" SG_ 2273435650 HDP_ObstacleDstVal 3;
BA_ "Version" SG_ 2273435650 HDP_ObstacleDstVal "19.11.02";
BA_ "Description" SG_ 2273435650 HDP_ObstacleLatPosVal "This signal indicates distance to a obstacle which is on driving path.";
BA_ "GenSigStartValue" SG_ 2273435650 HDP_ObstacleLatPosVal 510;
BA_ "UserSigValidity" SG_ 2273435650 HDP_ObstacleLatPosVal 3;
BA_ "RoutingFactor" SG_ 2273435650 HDP_ObstacleLatPosVal 3;
BA_ "Version" SG_ 2273435650 HDP_ObstacleLatPosVal "19.11.02";
BA_ "Description" SG_ 2273435650 HDP_InfoPUDis "This signal needed for the cluster pop-up display to inform HDP system status and warning.";
BA_ "UserSigValidity" SG_ 2273435650 HDP_InfoPUDis 3;
BA_ "RoutingFactor" SG_ 2273435650 HDP_InfoPUDis 3;
BA_ "Version" SG_ 2273435650 HDP_InfoPUDis "21.01.08";
BA_ "Description" SG_ 2273435650 HDP_WrngTypPUDis "This signal is needed for the cluster mini pop-up display to inform a reason of unavailable/TD activation or warning messages.";
BA_ "UserSigValidity" SG_ 2273435650 HDP_WrngTypPUDis 3;
BA_ "RoutingFactor" SG_ 2273435650 HDP_WrngTypPUDis 3;
BA_ "Version" SG_ 2273435650 HDP_WrngTypPUDis "21.03.11";
BA_ "Description" SG_ 2273435650 HDP_HapticWarnReq "This signal is needed for HDP haptic warning";
BA_ "UserSigValidity" SG_ 2273435650 HDP_HapticWarnReq 3;
BA_REL_ "GenSigTimeoutTime" BU_SG_REL_ DSAU SG_ 2273435650 HDP_HapticWarnReq 1500;
BA_ "RoutingFactor" SG_ 2273435650 HDP_HapticWarnReq 3;
BA_ "Version" SG_ 2273435650 HDP_HapticWarnReq "20.03.01";
BA_ "Description" SG_ 2273435650 HDP_ActvStaDis "This signal is needed for the cluster symbol display to inform a activation or deactivation status";
BA_ "UserSigValidity" SG_ 2273435650 HDP_ActvStaDis 3;
BA_ "RoutingFactor" SG_ 2273435650 HDP_ActvStaDis 3;
BA_ "Version" SG_ 2273435650 HDP_ActvStaDis "20.03.01";
BA_ "Description" SG_ 2273435650 HDP_OpStaDisp "This signal is needed for the cluster symbol display to inform highway driving pilot status";
BA_ "UserSigValidity" SG_ 2273435650 HDP_OpStaDisp 3;
BA_ "RoutingFactor" SG_ 2273435650 HDP_OpStaDisp 3;
BA_ "Version" SG_ 2273435650 HDP_OpStaDisp "20.06.01";
BA_ "Description" SG_ 2273435650 HDP_ObstSta "This signal represents the state of in-path obstacle and information of controllable state.

- 자차선상의 전방 일반물체 인식 여부 및 제어 가능 상태 정보";
BA_ "UserSigValidity" SG_ 2273435650 HDP_ObstSta 3;
BA_ "RoutingFactor" SG_ 2273435650 HDP_ObstSta 3;
BA_ "Version" SG_ 2273435650 HDP_ObstSta "20.06.01";
BA_ "Description" SG_ 2273435650 HDP_SysFlrDisp "This signal is for pop-up indication of HDP system failure.

If this signal is set to 1, the display device shall indicate HDP failure information to the driver.";
BA_ "UserSigValidity" SG_ 2273435650 HDP_SysFlrDisp 3;
BA_ "RoutingFactor" SG_ 2273435650 HDP_SysFlrDisp 3;
BA_ "Version" SG_ 2273435650 HDP_SysFlrDisp "21.06.10";
BA_ "Description" SG_ 2273435650 HDP_InhbtOffDispSta "This signal is shows that driving safety functions are inhibited while HDP in operation";
BA_ "UserSigValidity" SG_ 2273435650 HDP_InhbtOffDispSta 3;
BA_ "RoutingFactor" SG_ 2273435650 HDP_InhbtOffDispSta 3;
BA_ "Version" SG_ 2273435650 HDP_InhbtOffDispSta "21.04.00";
BA_ "Description" SG_ 2273435650 HDP_CtRoadSrfcDistVal "This signal is notifying how far to display the road surfaces.";
BA_ "GenSigStartValue" SG_ 2273435650 HDP_CtRoadSrfcDistVal 2046;
BA_ "UserSigValidity" SG_ 2273435650 HDP_CtRoadSrfcDistVal 3;
BA_ "RoutingFactor" SG_ 2273435650 HDP_CtRoadSrfcDistVal 3;
BA_ "Version" SG_ 2273435650 HDP_CtRoadSrfcDistVal "21.03.11";
BA_ "GenMsgSendType" BO_ 2244046849 0;
BA_ "GenMsgCycleTime" BO_ 2244046849 100;
BA_ "GenMsgCycleTimeFast" BO_ 2244046849 0;
BA_ "GenMsgNrOfRepetition" BO_ 2244046849 0;
BA_ "VFrameFormat" BO_ 2244046849 1;
BA_ "Description" SG_ 2244046849 ADAS_PRK_Crc1Val "The data area for CRC calculation is based on the data length (DLC) of the message DB.

The CRC shall be calculated over the entire data block (excluding the CRC bytes) including the user data, alive counter and Data ID

 

- CRC Polynomial (0x1021) , Initial Value : 0xFFFF, XOR value : 0x0000, Data ID : Message ID + 0xF800 

- The initial value is for CRC calculation and the message should be sent with the calculated result value. 

- The mathematical expression to 16 bit CRC polynomial is given here. G(x) = x16 + x12 + x5 + 1";
BA_ "GenSigStartValue" SG_ 2244046849 ADAS_PRK_Crc1Val 65535;
BA_ "UserSigValidity" SG_ 2244046849 ADAS_PRK_Crc1Val 3;
BA_ "RoutingFactor" SG_ 2244046849 ADAS_PRK_Crc1Val 5;
BA_ "Version" SG_ 2244046849 ADAS_PRK_Crc1Val "18.11.08";
BA_ "Description" SG_ 2244046849 ADAS_PRK_AlvCnt1Val "For the first transmission request for a data element the counter shall be initialized with 0 and shall be incremented by 1 for every subsequent send request. 

When the counter reaches the maximum value(0xFF), then it shall restart with 0 for the next send request";
BA_ "UserSigValidity" SG_ 2244046849 ADAS_PRK_AlvCnt1Val 3;
BA_ "RoutingFactor" SG_ 2244046849 ADAS_PRK_AlvCnt1Val 5;
BA_ "Version" SG_ 2244046849 ADAS_PRK_AlvCnt1Val "18.11.08";
BA_ "Description" SG_ 2244046849 PCA_RrEquipSta "PCA Rear Equipment Status";
BA_ "UserSigValidity" SG_ 2244046849 PCA_RrEquipSta 3;
BA_ "RoutingFactor" SG_ 2244046849 PCA_RrEquipSta 5;
BA_ "Version" SG_ 2244046849 PCA_RrEquipSta "19.10.03";
BA_ "Description" SG_ 2244046849 PCA_SysFlrSta "PCA Failure status";
BA_ "UserSigValidity" SG_ 2244046849 PCA_SysFlrSta 3;
BA_ "RoutingFactor" SG_ 2244046849 PCA_SysFlrSta 5;
BA_ "Version" SG_ 2244046849 PCA_SysFlrSta "19.10.03";
BA_ "Description" SG_ 2244046849 PCA_RrWrngLvlSta "PCA Rear Warning level status";
BA_ "UserSigValidity" SG_ 2244046849 PCA_RrWrngLvlSta 3;
BA_ "RoutingFactor" SG_ 2244046849 PCA_RrWrngLvlSta 5;
BA_ "Version" SG_ 2244046849 PCA_RrWrngLvlSta "19.10.03";
BA_ "Description" SG_ 2244046849 PCA_ModDis "PCA Mode Display";
BA_ "UserSigValidity" SG_ 2244046849 PCA_ModDis 3;
BA_ "RoutingFactor" SG_ 2244046849 PCA_ModDis 5;
BA_ "Version" SG_ 2244046849 PCA_ModDis "20.02.01";
BA_ "Description" SG_ 2244046849 PCA_WrngSndCtSta "Warning sound center status";
BA_ "UserSigValidity" SG_ 2244046849 PCA_WrngSndCtSta 3;
BA_REL_ "GenSigTimeoutTime" BU_SG_REL_ AMP SG_ 2244046849 PCA_WrngSndCtSta 1500;
BA_ "RoutingFactor" SG_ 2244046849 PCA_WrngSndCtSta 5;
BA_ "Version" SG_ 2244046849 PCA_WrngSndCtSta "20.01.01";
BA_ "Description" SG_ 2244046849 PCA_WrngSndLtSta "Warning sound left status";
BA_ "UserSigValidity" SG_ 2244046849 PCA_WrngSndLtSta 3;
BA_REL_ "GenSigTimeoutTime" BU_SG_REL_ AMP SG_ 2244046849 PCA_WrngSndLtSta 1500;
BA_ "RoutingFactor" SG_ 2244046849 PCA_WrngSndLtSta 5;
BA_ "Version" SG_ 2244046849 PCA_WrngSndLtSta "20.01.01";
BA_ "Description" SG_ 2244046849 PCA_WrngSndRtSta "Warning sound right status";
BA_ "UserSigValidity" SG_ 2244046849 PCA_WrngSndRtSta 3;
BA_REL_ "GenSigTimeoutTime" BU_SG_REL_ AMP SG_ 2244046849 PCA_WrngSndRtSta 1500;
BA_ "RoutingFactor" SG_ 2244046849 PCA_WrngSndRtSta 5;
BA_ "Version" SG_ 2244046849 PCA_WrngSndRtSta "17.12.00";
BA_ "Description" SG_ 2244046849 PCA_HptReq "PCA Haptic Request";
BA_ "UserSigValidity" SG_ 2244046849 PCA_HptReq 3;
BA_ "RoutingFactor" SG_ 2244046849 PCA_HptReq 5;
BA_ "Version" SG_ 2244046849 PCA_HptReq "20.02.03";
BA_ "Description" SG_ 2244046849 PCA_BrkReq "Brake request

with EPB : 0x2 PCA Brake on (hold)

without EPB : 0x1 PCA Brake on";
BA_ "UserSigValidity" SG_ 2244046849 PCA_BrkReq 3;
BA_ "RoutingFactor" SG_ 2244046849 PCA_BrkReq 5;
BA_ "Version" SG_ 2244046849 PCA_BrkReq "19.07.06";
BA_ "Description" SG_ 2244046849 PCA_EpbReq "request to hold the vehicle, applying EPB";
BA_ "UserSigValidity" SG_ 2244046849 PCA_EpbReq 3;
BA_ "RoutingFactor" SG_ 2244046849 PCA_EpbReq 5;
BA_ "Version" SG_ 2244046849 PCA_EpbReq "19.07.06";
BA_ "Description" SG_ 2244046849 PCA_DclTrgtVal "Deceleration target value";
BA_ "UserSigValidity" SG_ 2244046849 PCA_DclTrgtVal 3;
BA_ "RoutingFactor" SG_ 2244046849 PCA_DclTrgtVal 5;
BA_ "Version" SG_ 2244046849 PCA_DclTrgtVal "18.07.01";
BA_ "Description" SG_ 2244046849 PCA_DgrSta "Warning timing status";
BA_ "UserSigValidity" SG_ 2244046849 PCA_DgrSta 3;
BA_ "RoutingFactor" SG_ 2244046849 PCA_DgrSta 5;
BA_ "Version" SG_ 2244046849 PCA_DgrSta "17.12.03";
BA_ "Description" SG_ 2244046849 ADAS_PRK_PDW_SysFlrSta "PDW Failure Status";
BA_ "UserSigValidity" SG_ 2244046849 ADAS_PRK_PDW_SysFlrSta 3;
BA_ "RoutingFactor" SG_ 2244046849 ADAS_PRK_PDW_SysFlrSta 5;
BA_ "Version" SG_ 2244046849 ADAS_PRK_PDW_SysFlrSta "20.11.02";
BA_ "GenMsgSendType" BO_ 2244046850 0;
BA_ "GenMsgCycleTime" BO_ 2244046850 100;
BA_ "GenMsgCycleTimeFast" BO_ 2244046850 0;
BA_ "GenMsgNrOfRepetition" BO_ 2244046850 0;
BA_ "VFrameFormat" BO_ 2244046850 1;
BA_ "Description" SG_ 2244046850 ADAS_PRK_PDW_SwIndOnReq "-PDW Switch Indicator On/Off Request

This signal is used for PDW-R and PDW-F/R";
BA_ "UserSigValidity" SG_ 2244046850 ADAS_PRK_PDW_SwIndOnReq 3;
BA_ "RoutingFactor" SG_ 2244046850 ADAS_PRK_PDW_SwIndOnReq 5;
BA_ "Version" SG_ 2244046850 ADAS_PRK_PDW_SwIndOnReq "18.05.02";
BA_ "Description" SG_ 2244046850 PCA_RrEquipChkSta "PCA Rear Equipment Check Status";
BA_ "UserSigValidity" SG_ 2244046850 PCA_RrEquipChkSta 3;
BA_ "RoutingFactor" SG_ 2244046850 PCA_RrEquipChkSta 5;
BA_ "Version" SG_ 2244046850 PCA_RrEquipChkSta "20.05.02";
BA_ "Description" SG_ 2244046850 PCA_FrWrngLvlSta "PCA Front warning level status";
BA_ "UserSigValidity" SG_ 2244046850 PCA_FrWrngLvlSta 3;
BA_ "RoutingFactor" SG_ 2244046850 PCA_FrWrngLvlSta 5;
BA_ "Version" SG_ 2244046850 PCA_FrWrngLvlSta "19.10.03";
BA_ "Description" SG_ 2244046850 PCA_LtWrngLvlSta "PCA Left warning level status";
BA_ "UserSigValidity" SG_ 2244046850 PCA_LtWrngLvlSta 3;
BA_ "RoutingFactor" SG_ 2244046850 PCA_LtWrngLvlSta 5;
BA_ "Version" SG_ 2244046850 PCA_LtWrngLvlSta "20.01.01";
BA_ "Description" SG_ 2244046850 ADAS_PRK_PDW_OptTyp "this signal means PDW Option (Non, PDW-R, PDW-FR, PDW-FSR)";
BA_ "UserSigValidity" SG_ 2244046850 ADAS_PRK_PDW_OptTyp 3;
BA_ "RoutingFactor" SG_ 2244046850 ADAS_PRK_PDW_OptTyp 5;
BA_ "Version" SG_ 2244046850 ADAS_PRK_PDW_OptTyp "20.11.02";
BA_ "Description" SG_ 2244046850 PCA_RtWrngLvlSta "PCA Right warning level status";
BA_ "UserSigValidity" SG_ 2244046850 PCA_RtWrngLvlSta 3;
BA_ "RoutingFactor" SG_ 2244046850 PCA_RtWrngLvlSta 5;
BA_ "Version" SG_ 2244046850 PCA_RtWrngLvlSta "19.08.08";
BA_ "Description" SG_ 2244046850 PCA_LtWrngDis "PCA Left warning display";
BA_ "UserSigValidity" SG_ 2244046850 PCA_LtWrngDis 3;
BA_ "RoutingFactor" SG_ 2244046850 PCA_LtWrngDis 5;
BA_ "Version" SG_ 2244046850 PCA_LtWrngDis "20.09.00";
BA_ "Description" SG_ 2244046850 PCA_RtWrngDis "PCA Right warning display";
BA_ "UserSigValidity" SG_ 2244046850 PCA_RtWrngDis 3;
BA_ "RoutingFactor" SG_ 2244046850 PCA_RtWrngDis 5;
BA_ "Version" SG_ 2244046850 PCA_RtWrngDis "20.09.00";
BA_ "Description" SG_ 2244046850 PCA_LtRrWrngDis "PCA Left-Rear warning display";
BA_ "UserSigValidity" SG_ 2244046850 PCA_LtRrWrngDis 3;
BA_ "RoutingFactor" SG_ 2244046850 PCA_LtRrWrngDis 5;
BA_ "Version" SG_ 2244046850 PCA_LtRrWrngDis "20.09.00";
BA_ "Description" SG_ 2244046850 PCA_RtRrWrngDis "PCA Right-Rear warning display";
BA_ "UserSigValidity" SG_ 2244046850 PCA_RtRrWrngDis 3;
BA_ "RoutingFactor" SG_ 2244046850 PCA_RtRrWrngDis 5;
BA_ "Version" SG_ 2244046850 PCA_RtRrWrngDis "20.09.00";
BA_ "Description" SG_ 2244046850 PCA_RrFlrDis "PCA Rear Failure Display";
BA_ "UserSigValidity" SG_ 2244046850 PCA_RrFlrDis 3;
BA_ "RoutingFactor" SG_ 2244046850 PCA_RrFlrDis 5;
BA_ "Version" SG_ 2244046850 PCA_RrFlrDis "19.10.04";
BA_ "Description" SG_ 2244046850 PCA_FrFlrDis "PCA Front Failure Display";
BA_ "UserSigValidity" SG_ 2244046850 PCA_FrFlrDis 3;
BA_ "RoutingFactor" SG_ 2244046850 PCA_FrFlrDis 5;
BA_ "Version" SG_ 2244046850 PCA_FrFlrDis "19.10.04";
BA_ "Description" SG_ 2244046850 PCA_LtFlrDis "PCA Left Failure Display";
BA_ "UserSigValidity" SG_ 2244046850 PCA_LtFlrDis 3;
BA_ "RoutingFactor" SG_ 2244046850 PCA_LtFlrDis 5;
BA_ "Version" SG_ 2244046850 PCA_LtFlrDis "20.01.01";
BA_ "Description" SG_ 2244046850 PCA_RtFlrDis "PCA Right Failure Display";
BA_ "UserSigValidity" SG_ 2244046850 PCA_RtFlrDis 3;
BA_ "RoutingFactor" SG_ 2244046850 PCA_RtFlrDis 5;
BA_ "Version" SG_ 2244046850 PCA_RtFlrDis "19.10.04";
BA_ "Description" SG_ 2244046850 ADAS_PRK_PDW_AutoOn_USM "PDW system automatically on/off setting status";
BA_ "UserSigValidity" SG_ 2244046850 ADAS_PRK_PDW_AutoOn_USM 3;
BA_ "RoutingFactor" SG_ 2244046850 ADAS_PRK_PDW_AutoOn_USM 5;
BA_ "Version" SG_ 2244046850 ADAS_PRK_PDW_AutoOn_USM "18.05.02";
BA_ "Description" SG_ 2244046850 PCA_FrSdEquipChkSta "PCA Front Side Equipment Check Status";
BA_ "UserSigValidity" SG_ 2244046850 PCA_FrSdEquipChkSta 3;
BA_ "RoutingFactor" SG_ 2244046850 PCA_FrSdEquipChkSta 5;
BA_ "Version" SG_ 2244046850 PCA_FrSdEquipChkSta "20.05.02";
BA_ "GenMsgSendType" BO_ 1030 0;
BA_ "Description" SG_ 1030 APSM_SWVerMajor1 "Indicate the SCM software version as follows:

- The software version is displayed in three digits.

- The Major and Minor digits are separated by '.'

- Signal values are transmitted to ASCII codes.



※ Example

APSM_SWVerMajor1 : 0x41 (HEX) -> ASCII CODE : 'A' 

APSM_SWVerMinor1 : 0x30 (HEX) -> ASCII CODE : '0'

APSM_SWVerMinor2 : 0x33 (HEX) -> ASCII CODE : '3'

=> APSM S/W Ver is displayed 'A.03'";
BA_ "GenSigSendType" SG_ 1030 APSM_SWVerMajor1 4;
BA_ "UserSigValidity" SG_ 1030 APSM_SWVerMajor1 0;
BA_REL_ "GenSigTimeoutTime" BU_SG_REL_ CGW_CCU SG_ 1030 APSM_SWVerMajor1 1500;
BA_ "Version" SG_ 1030 APSM_SWVerMajor1 "21.07.00";
BA_ "Description" SG_ 1030 APSM_SWVerMinor1 "Indicate the APSM software version as follows:

- The software version is displayed in three digits.

- The Major and Minor digits are separated by '.'

- Signal values are transmitted to ASCII codes.



※ Example

APSM_SWVerMajor1 : 0x41 (HEX) -> ASCII CODE : 'A' 

APSM_SWVerMinor1 : 0x30 (HEX) -> ASCII CODE : '0'

APSM_SWVerMinor2 : 0x33 (HEX) -> ASCII CODE : '3'

=> APSM S/W Ver is displayed 'A.03'";
BA_ "GenSigSendType" SG_ 1030 APSM_SWVerMinor1 4;
BA_ "UserSigValidity" SG_ 1030 APSM_SWVerMinor1 0;
BA_REL_ "GenSigTimeoutTime" BU_SG_REL_ CGW_CCU SG_ 1030 APSM_SWVerMinor1 1500;
BA_ "Version" SG_ 1030 APSM_SWVerMinor1 "18.10.06";
BA_ "Description" SG_ 1030 APSM_SWVerMinor2 "Indicate the APSM software version as follows:

- The software version is displayed in three digits.

- The Major and Minor digits are separated by '.'

- Signal values are transmitted to ASCII codes.



※ Example

APSM_SWVerMajor1 : 0x41 (HEX) -> ASCII CODE : 'A' 

APSM_SWVerMinor1 : 0x30 (HEX) -> ASCII CODE : '0'

APSM_SWVerMinor2 : 0x33 (HEX) -> ASCII CODE : '3'

=> APSM S/W Ver is displayed 'A.03'";
BA_ "GenSigSendType" SG_ 1030 APSM_SWVerMinor2 4;
BA_ "UserSigValidity" SG_ 1030 APSM_SWVerMinor2 0;
BA_REL_ "GenSigTimeoutTime" BU_SG_REL_ CGW_CCU SG_ 1030 APSM_SWVerMinor2 1500;
BA_ "Version" SG_ 1030 APSM_SWVerMinor2 "18.10.06";
BA_ "GenMsgSendType" BO_ 1031 0;
BA_ "Description" SG_ 1031 APSM_FootrestPosition "Footrest POSITION (UNIT: ˚)";
BA_ "GenSigSendType" SG_ 1031 APSM_FootrestPosition 4;
BA_ "UserSigValidity" SG_ 1031 APSM_FootrestPosition 0;
BA_REL_ "GenSigTimeoutTime" BU_SG_REL_ ASAU SG_ 1031 APSM_FootrestPosition 1500;
BA_REL_ "GenSigTimeoutTime" BU_SG_REL_ ATS SG_ 1031 APSM_FootrestPosition 1500;
BA_REL_ "GenSigTimeoutTime" BU_SG_REL_ RRPSM SG_ 1031 APSM_FootrestPosition 1500;
BA_REL_ "GenSigTimeoutTime" BU_SG_REL_ CGW_CCU SG_ 1031 APSM_FootrestPosition 1500;
BA_ "NetworkRequest" SG_ 1031 APSM_FootrestPosition 0;
BA_ "NetworkRequestHoldingTime" SG_ 1031 APSM_FootrestPosition 5000;
BA_ "Version" SG_ 1031 APSM_FootrestPosition "20.05.03";
BA_ "Description" SG_ 1031 APSM_LegRestandAstPosition "Rear Leg Rest OPEN/CLOSE and Ast Seat Position";
BA_ "GenSigSendType" SG_ 1031 APSM_LegRestandAstPosition 4;
BA_ "UserSigValidity" SG_ 1031 APSM_LegRestandAstPosition 0;
BA_REL_ "GenSigTimeoutTime" BU_SG_REL_ ATS SG_ 1031 APSM_LegRestandAstPosition 1500;
BA_REL_ "GenSigTimeoutTime" BU_SG_REL_ RRPSM SG_ 1031 APSM_LegRestandAstPosition 1500;
BA_REL_ "GenSigTimeoutTime" BU_SG_REL_ CGW_CCU SG_ 1031 APSM_LegRestandAstPosition 1500;
BA_ "NetworkRequest" SG_ 1031 APSM_LegRestandAstPosition 0;
BA_ "NetworkRequestHoldingTime" SG_ 1031 APSM_LegRestandAstPosition 5000;
BA_ "Version" SG_ 1031 APSM_LegRestandAstPosition "20.07.11";
BA_ "Description" SG_ 1031 APSM_FootRestandAstPosition "Rear Foot Rest OPEN/CLOSE and Ast Position";
BA_ "GenSigSendType" SG_ 1031 APSM_FootRestandAstPosition 4;
BA_ "UserSigValidity" SG_ 1031 APSM_FootRestandAstPosition 0;
BA_REL_ "GenSigTimeoutTime" BU_SG_REL_ ATS SG_ 1031 APSM_FootRestandAstPosition 1500;
BA_REL_ "GenSigTimeoutTime" BU_SG_REL_ RRPSM SG_ 1031 APSM_FootRestandAstPosition 1500;
BA_REL_ "GenSigTimeoutTime" BU_SG_REL_ CGW_CCU SG_ 1031 APSM_FootRestandAstPosition 1500;
BA_ "NetworkRequest" SG_ 1031 APSM_FootRestandAstPosition 0;
BA_ "NetworkRequestHoldingTime" SG_ 1031 APSM_FootRestandAstPosition 5000;
BA_ "Version" SG_ 1031 APSM_FootRestandAstPosition "20.07.11";
BA_ "Description" SG_ 1031 APSM_FootRestandLegRestPosition "Foot Rest OPEN/CLOSE and Leg Rest OPEN/CLOSE";
BA_ "GenSigSendType" SG_ 1031 APSM_FootRestandLegRestPosition 4;
BA_ "UserSigValidity" SG_ 1031 APSM_FootRestandLegRestPosition 0;
BA_REL_ "GenSigTimeoutTime" BU_SG_REL_ ATS SG_ 1031 APSM_FootRestandLegRestPosition 1500;
BA_REL_ "GenSigTimeoutTime" BU_SG_REL_ RRPSM SG_ 1031 APSM_FootRestandLegRestPosition 1500;
BA_REL_ "GenSigTimeoutTime" BU_SG_REL_ CGW_CCU SG_ 1031 APSM_FootRestandLegRestPosition 1500;
BA_ "NetworkRequest" SG_ 1031 APSM_FootRestandLegRestPosition 0;
BA_ "NetworkRequestHoldingTime" SG_ 1031 APSM_FootRestandLegRestPosition 5000;
BA_ "Version" SG_ 1031 APSM_FootRestandLegRestPosition "20.07.11";
BA_ "Description" SG_ 1031 APSM_RearModeEnable "Rear One Touch Mode Enable/Disable";
BA_ "GenSigSendType" SG_ 1031 APSM_RearModeEnable 4;
BA_ "UserSigValidity" SG_ 1031 APSM_RearModeEnable 0;
BA_REL_ "GenSigTimeoutTime" BU_SG_REL_ RRPSM SG_ 1031 APSM_RearModeEnable 1500;
BA_ "NetworkRequest" SG_ 1031 APSM_RearModeEnable 0;
BA_ "NetworkRequestHoldingTime" SG_ 1031 APSM_RearModeEnable 5000;
BA_ "Version" SG_ 1031 APSM_RearModeEnable "19.07.06";
BA_ "GenSigSendType" SG_ 1031 APSM_AstStEsyAcsUSMSta 4;
BA_ "UserSigValidity" SG_ 1031 APSM_AstStEsyAcsUSMSta 0;
BA_REL_ "GenSigTimeoutTime" BU_SG_REL_ CGW_CCU SG_ 1031 APSM_AstStEsyAcsUSMSta 1500;
BA_ "NetworkRequest" SG_ 1031 APSM_AstStEsyAcsUSMSta 0;
BA_ "NetworkRequestHoldingTime" SG_ 1031 APSM_AstStEsyAcsUSMSta 5000;
BA_ "Version" SG_ 1031 APSM_AstStEsyAcsUSMSta "19.08.08";
BA_ "Description" SG_ 1031 APSM_ReturnModeState "APSM move state for Return Mode";
BA_ "GenSigSendType" SG_ 1031 APSM_ReturnModeState 4;
BA_ "UserSigValidity" SG_ 1031 APSM_ReturnModeState 0;
BA_REL_ "GenSigTimeoutTime" BU_SG_REL_ RRPSM SG_ 1031 APSM_ReturnModeState 1500;
BA_ "NetworkRequest" SG_ 1031 APSM_ReturnModeState 0;
BA_ "NetworkRequestHoldingTime" SG_ 1031 APSM_ReturnModeState 5000;
BA_ "Version" SG_ 1031 APSM_ReturnModeState "20.07.05";
BA_ "Description" SG_ 1031 APSM_RelaxModeState "APSM move state for Relax Mode";
BA_ "GenSigSendType" SG_ 1031 APSM_RelaxModeState 4;
BA_ "UserSigValidity" SG_ 1031 APSM_RelaxModeState 0;
BA_REL_ "GenSigTimeoutTime" BU_SG_REL_ RRPSM SG_ 1031 APSM_RelaxModeState 1500;
BA_ "NetworkRequest" SG_ 1031 APSM_RelaxModeState 0;
BA_ "NetworkRequestHoldingTime" SG_ 1031 APSM_RelaxModeState 5000;
BA_ "Version" SG_ 1031 APSM_RelaxModeState "20.07.05";
BA_ "Description" SG_ 1031 APSM_WalkInEnable "Apsm Walk In Mode Enable/Disable";
BA_ "GenSigSendType" SG_ 1031 APSM_WalkInEnable 4;
BA_ "UserSigValidity" SG_ 1031 APSM_WalkInEnable 0;
BA_REL_ "GenSigTimeoutTime" BU_SG_REL_ RRPSM SG_ 1031 APSM_WalkInEnable 1500;
BA_ "NetworkRequest" SG_ 1031 APSM_WalkInEnable 0;
BA_ "NetworkRequestHoldingTime" SG_ 1031 APSM_WalkInEnable 5000;
BA_ "Version" SG_ 1031 APSM_WalkInEnable "19.07.06";
BA_ "GenSigSendType" SG_ 1031 APSM_LimSetSta 4;
BA_ "UserSigValidity" SG_ 1031 APSM_LimSetSta 0;
BA_REL_ "GenSigTimeoutTime" BU_SG_REL_ ATS SG_ 1031 APSM_LimSetSta 1500;
BA_REL_ "GenSigTimeoutTime" BU_SG_REL_ RRPSM SG_ 1031 APSM_LimSetSta 1500;
BA_ "NetworkRequest" SG_ 1031 APSM_LimSetSta 0;
BA_ "NetworkRequestHoldingTime" SG_ 1031 APSM_LimSetSta 5000;
BA_ "Version" SG_ 1031 APSM_LimSetSta "21.04.01";
BA_ "Description" SG_ 1031 APSM_MonitorModeState "APSM move state for Monitor Mode";
BA_ "GenSigSendType" SG_ 1031 APSM_MonitorModeState 4;
BA_ "UserSigValidity" SG_ 1031 APSM_MonitorModeState 0;
BA_REL_ "GenSigTimeoutTime" BU_SG_REL_ RRPSM SG_ 1031 APSM_MonitorModeState 1500;
BA_ "NetworkRequest" SG_ 1031 APSM_MonitorModeState 0;
BA_ "NetworkRequestHoldingTime" SG_ 1031 APSM_MonitorModeState 5000;
BA_ "Version" SG_ 1031 APSM_MonitorModeState "21.08.04";
BA_ "Description" SG_ 1031 APSM_FootRest_Opt "Foot Rest OPTION";
BA_ "GenSigSendType" SG_ 1031 APSM_FootRest_Opt 4;
BA_ "UserSigValidity" SG_ 1031 APSM_FootRest_Opt 0;
BA_REL_ "GenSigTimeoutTime" BU_SG_REL_ ATS SG_ 1031 APSM_FootRest_Opt 1500;
BA_REL_ "GenSigTimeoutTime" BU_SG_REL_ CGW_CCU SG_ 1031 APSM_FootRest_Opt 1500;
BA_ "NetworkRequest" SG_ 1031 APSM_FootRest_Opt 0;
BA_ "NetworkRequestHoldingTime" SG_ 1031 APSM_FootRest_Opt 5000;
BA_ "Version" SG_ 1031 APSM_FootRest_Opt "19.11.05";
BA_ "Description" SG_ 1031 APSM_RSE_Opt "RSE OPTION";
BA_ "GenSigSendType" SG_ 1031 APSM_RSE_Opt 4;
BA_ "UserSigValidity" SG_ 1031 APSM_RSE_Opt 0;
BA_REL_ "GenSigTimeoutTime" BU_SG_REL_ ATS SG_ 1031 APSM_RSE_Opt 1500;
BA_REL_ "GenSigTimeoutTime" BU_SG_REL_ CGW_CCU SG_ 1031 APSM_RSE_Opt 1500;
BA_ "NetworkRequest" SG_ 1031 APSM_RSE_Opt 0;
BA_ "NetworkRequestHoldingTime" SG_ 1031 APSM_RSE_Opt 5000;
BA_ "Version" SG_ 1031 APSM_RSE_Opt "20.07.11";
BA_ "Description" SG_ 1031 APSM_AstSlidePosition "ASSIST SEAT SLIDE POSITION (UNIT: mm)";
BA_ "GenSigSendType" SG_ 1031 APSM_AstSlidePosition 4;
BA_ "UserSigValidity" SG_ 1031 APSM_AstSlidePosition 0;
BA_REL_ "GenSigTimeoutTime" BU_SG_REL_ RRPSM SG_ 1031 APSM_AstSlidePosition 1500;
BA_REL_ "GenSigTimeoutTime" BU_SG_REL_ CGW_CCU SG_ 1031 APSM_AstSlidePosition 1500;
BA_ "NetworkRequest" SG_ 1031 APSM_AstSlidePosition 0;
BA_ "NetworkRequestHoldingTime" SG_ 1031 APSM_AstSlidePosition 5000;
BA_ "Version" SG_ 1031 APSM_AstSlidePosition "19.07.06";
BA_ "Description" SG_ 1031 APSM_AstReclinePosition "ASSIST SEAT RECLINE POSITION (UNIT: ˚)";
BA_ "GenSigSendType" SG_ 1031 APSM_AstReclinePosition 4;
BA_ "UserSigValidity" SG_ 1031 APSM_AstReclinePosition 0;
BA_REL_ "GenSigTimeoutTime" BU_SG_REL_ RRPSM SG_ 1031 APSM_AstReclinePosition 1500;
BA_REL_ "GenSigTimeoutTime" BU_SG_REL_ CGW_CCU SG_ 1031 APSM_AstReclinePosition 1500;
BA_ "NetworkRequest" SG_ 1031 APSM_AstReclinePosition 0;
BA_ "NetworkRequestHoldingTime" SG_ 1031 APSM_AstReclinePosition 5000;
BA_ "Version" SG_ 1031 APSM_AstReclinePosition "19.07.06";
BA_ "GenMsgSendType" BO_ 543 0;
BA_ "Description" SG_ 543 ATS_AstStSldFwdBtn "동승석 슬라이딩 전방 이동 (워크인 작동)";
BA_ "GenSigSendType" SG_ 543 ATS_AstStSldFwdBtn 4;
BA_ "UserSigValidity" SG_ 543 ATS_AstStSldFwdBtn 3;
BA_REL_ "GenSigTimeoutTime" BU_SG_REL_ APSM SG_ 543 ATS_AstStSldFwdBtn 1500;
BA_ "NetworkRequest" SG_ 543 ATS_AstStSldFwdBtn 0;
BA_ "NetworkRequestHoldingTime" SG_ 543 ATS_AstStSldFwdBtn 5000;
BA_ "Version" SG_ 543 ATS_AstStSldFwdBtn "19.09.02";
BA_ "Description" SG_ 543 ATS_AstStSldBwdBtn "동승석 슬라이딩 후방 이동 (워크인 작동)";
BA_ "GenSigSendType" SG_ 543 ATS_AstStSldBwdBtn 4;
BA_ "UserSigValidity" SG_ 543 ATS_AstStSldBwdBtn 3;
BA_REL_ "GenSigTimeoutTime" BU_SG_REL_ APSM SG_ 543 ATS_AstStSldBwdBtn 1500;
BA_ "NetworkRequest" SG_ 543 ATS_AstStSldBwdBtn 0;
BA_ "NetworkRequestHoldingTime" SG_ 543 ATS_AstStSldBwdBtn 5000;
BA_ "Version" SG_ 543 ATS_AstStSldBwdBtn "19.09.02";
BA_ "Description" SG_ 543 ATS_AstStRclFwdBtn "동승석 리클라이닝 전방 이동 (워크인 작동)";
BA_ "GenSigSendType" SG_ 543 ATS_AstStRclFwdBtn 4;
BA_ "UserSigValidity" SG_ 543 ATS_AstStRclFwdBtn 3;
BA_REL_ "GenSigTimeoutTime" BU_SG_REL_ APSM SG_ 543 ATS_AstStRclFwdBtn 1500;
BA_ "NetworkRequest" SG_ 543 ATS_AstStRclFwdBtn 0;
BA_ "NetworkRequestHoldingTime" SG_ 543 ATS_AstStRclFwdBtn 5000;
BA_ "Version" SG_ 543 ATS_AstStRclFwdBtn "19.09.02";
BA_ "Description" SG_ 543 ATS_AstStRclBwdBtn "동승석 리클라이닝 후방 이동 (워크인 작동)";
BA_ "GenSigSendType" SG_ 543 ATS_AstStRclBwdBtn 4;
BA_ "UserSigValidity" SG_ 543 ATS_AstStRclBwdBtn 3;
BA_REL_ "GenSigTimeoutTime" BU_SG_REL_ APSM SG_ 543 ATS_AstStRclBwdBtn 1500;
BA_ "NetworkRequest" SG_ 543 ATS_AstStRclBwdBtn 0;
BA_ "NetworkRequestHoldingTime" SG_ 543 ATS_AstStRclBwdBtn 5000;
BA_ "Version" SG_ 543 ATS_AstStRclBwdBtn "19.09.02";
BA_ "Description" SG_ 543 ATS_AstStHgtUpBtn "동승석 하이트 업 이동 (워크인 작동)";
BA_ "GenSigSendType" SG_ 543 ATS_AstStHgtUpBtn 4;
BA_ "UserSigValidity" SG_ 543 ATS_AstStHgtUpBtn 3;
BA_REL_ "GenSigTimeoutTime" BU_SG_REL_ APSM SG_ 543 ATS_AstStHgtUpBtn 1500;
BA_ "NetworkRequest" SG_ 543 ATS_AstStHgtUpBtn 0;
BA_ "NetworkRequestHoldingTime" SG_ 543 ATS_AstStHgtUpBtn 5000;
BA_ "Version" SG_ 543 ATS_AstStHgtUpBtn "19.09.02";
BA_ "Description" SG_ 543 ATS_AstStHgtDnBtn "동승석 하이트 다운 이동 (워크인 작동)";
BA_ "GenSigSendType" SG_ 543 ATS_AstStHgtDnBtn 4;
BA_ "UserSigValidity" SG_ 543 ATS_AstStHgtDnBtn 3;
BA_REL_ "GenSigTimeoutTime" BU_SG_REL_ APSM SG_ 543 ATS_AstStHgtDnBtn 1500;
BA_ "NetworkRequest" SG_ 543 ATS_AstStHgtDnBtn 0;
BA_ "NetworkRequestHoldingTime" SG_ 543 ATS_AstStHgtDnBtn 5000;
BA_ "Version" SG_ 543 ATS_AstStHgtDnBtn "19.09.02";
BA_ "Description" SG_ 543 ATS_AstStHRestUpBtn "동승석 헤드레스트 업 이동 (워크인 작동)";
BA_ "GenSigSendType" SG_ 543 ATS_AstStHRestUpBtn 4;
BA_ "UserSigValidity" SG_ 543 ATS_AstStHRestUpBtn 3;
BA_REL_ "GenSigTimeoutTime" BU_SG_REL_ APSM SG_ 543 ATS_AstStHRestUpBtn 1500;
BA_ "NetworkRequest" SG_ 543 ATS_AstStHRestUpBtn 0;
BA_ "NetworkRequestHoldingTime" SG_ 543 ATS_AstStHRestUpBtn 5000;
BA_ "Version" SG_ 543 ATS_AstStHRestUpBtn "19.09.02";
BA_ "Description" SG_ 543 ATS_AstStHRestDnBtn "동승석 헤드레스트 다운 이동 (워크인 작동)";
BA_ "GenSigSendType" SG_ 543 ATS_AstStHRestDnBtn 4;
BA_ "UserSigValidity" SG_ 543 ATS_AstStHRestDnBtn 3;
BA_REL_ "GenSigTimeoutTime" BU_SG_REL_ APSM SG_ 543 ATS_AstStHRestDnBtn 1500;
BA_ "NetworkRequest" SG_ 543 ATS_AstStHRestDnBtn 0;
BA_ "NetworkRequestHoldingTime" SG_ 543 ATS_AstStHRestDnBtn 5000;
BA_ "Version" SG_ 543 ATS_AstStHRestDnBtn "19.09.02";
BA_ "Description" SG_ 543 ATS_AstStHRestFwdBtn "동승석 헤드레스트 전방 이동 (워크인 작동)";
BA_ "GenSigSendType" SG_ 543 ATS_AstStHRestFwdBtn 4;
BA_ "UserSigValidity" SG_ 543 ATS_AstStHRestFwdBtn 3;
BA_REL_ "GenSigTimeoutTime" BU_SG_REL_ APSM SG_ 543 ATS_AstStHRestFwdBtn 1500;
BA_ "NetworkRequest" SG_ 543 ATS_AstStHRestFwdBtn 0;
BA_ "NetworkRequestHoldingTime" SG_ 543 ATS_AstStHRestFwdBtn 5000;
BA_ "Version" SG_ 543 ATS_AstStHRestFwdBtn "19.09.02";
BA_ "Description" SG_ 543 ATS_AstStHRestBwdBtn "동승석 헤드레스트 후방 이동 (워크인 작동)";
BA_ "GenSigSendType" SG_ 543 ATS_AstStHRestBwdBtn 4;
BA_ "UserSigValidity" SG_ 543 ATS_AstStHRestBwdBtn 3;
BA_REL_ "GenSigTimeoutTime" BU_SG_REL_ APSM SG_ 543 ATS_AstStHRestBwdBtn 1500;
BA_ "NetworkRequest" SG_ 543 ATS_AstStHRestBwdBtn 0;
BA_ "NetworkRequestHoldingTime" SG_ 543 ATS_AstStHRestBwdBtn 5000;
BA_ "Version" SG_ 543 ATS_AstStHRestBwdBtn "19.09.02";
BA_ "Description" SG_ 543 ATS_AstStHRestFldBtn "동승석 헤드레스트 폴딩 이동 (워크인 작동)";
BA_ "GenSigSendType" SG_ 543 ATS_AstStHRestFldBtn 4;
BA_ "UserSigValidity" SG_ 543 ATS_AstStHRestFldBtn 3;
BA_REL_ "GenSigTimeoutTime" BU_SG_REL_ APSM SG_ 543 ATS_AstStHRestFldBtn 1500;
BA_ "NetworkRequest" SG_ 543 ATS_AstStHRestFldBtn 0;
BA_ "NetworkRequestHoldingTime" SG_ 543 ATS_AstStHRestFldBtn 5000;
BA_ "Version" SG_ 543 ATS_AstStHRestFldBtn "19.09.02";
BA_ "Description" SG_ 543 ATS_AstStHRestUnFldBtn "동승석 헤드레스트 언폴딩 이동 (워크인 작동)";
BA_ "GenSigSendType" SG_ 543 ATS_AstStHRestUnFldBtn 4;
BA_ "UserSigValidity" SG_ 543 ATS_AstStHRestUnFldBtn 3;
BA_REL_ "GenSigTimeoutTime" BU_SG_REL_ APSM SG_ 543 ATS_AstStHRestUnFldBtn 1500;
BA_ "NetworkRequest" SG_ 543 ATS_AstStHRestUnFldBtn 0;
BA_ "NetworkRequestHoldingTime" SG_ 543 ATS_AstStHRestUnFldBtn 5000;
BA_ "Version" SG_ 543 ATS_AstStHRestUnFldBtn "19.09.02";
BA_ "Description" SG_ 543 ATS_AstStRseFwdBtn "동승석 모니터 각도 조절 전방 이동";
BA_ "GenSigSendType" SG_ 543 ATS_AstStRseFwdBtn 4;
BA_ "UserSigValidity" SG_ 543 ATS_AstStRseFwdBtn 3;
BA_REL_ "GenSigTimeoutTime" BU_SG_REL_ APSM SG_ 543 ATS_AstStRseFwdBtn 1500;
BA_ "NetworkRequest" SG_ 543 ATS_AstStRseFwdBtn 0;
BA_ "NetworkRequestHoldingTime" SG_ 543 ATS_AstStRseFwdBtn 5000;
BA_ "Version" SG_ 543 ATS_AstStRseFwdBtn "19.09.02";
BA_ "Description" SG_ 543 ATS_AstStRseBwdBtn "동승석 모니터 각도 조절 후방 이동";
BA_ "GenSigSendType" SG_ 543 ATS_AstStRseBwdBtn 4;
BA_ "UserSigValidity" SG_ 543 ATS_AstStRseBwdBtn 3;
BA_REL_ "GenSigTimeoutTime" BU_SG_REL_ APSM SG_ 543 ATS_AstStRseBwdBtn 1500;
BA_ "NetworkRequest" SG_ 543 ATS_AstStRseBwdBtn 0;
BA_ "NetworkRequestHoldingTime" SG_ 543 ATS_AstStRseBwdBtn 5000;
BA_ "Version" SG_ 543 ATS_AstStRseBwdBtn "19.09.02";
BA_ "Description" SG_ 543 ATS_AstStFRestFldBtn "동승석 풋레스트 폴딩 이동 (워크인 작동)";
BA_ "GenSigSendType" SG_ 543 ATS_AstStFRestFldBtn 4;
BA_ "UserSigValidity" SG_ 543 ATS_AstStFRestFldBtn 3;
BA_REL_ "GenSigTimeoutTime" BU_SG_REL_ APSM SG_ 543 ATS_AstStFRestFldBtn 1500;
BA_ "NetworkRequest" SG_ 543 ATS_AstStFRestFldBtn 0;
BA_ "NetworkRequestHoldingTime" SG_ 543 ATS_AstStFRestFldBtn 5000;
BA_ "Version" SG_ 543 ATS_AstStFRestFldBtn "19.09.02";
BA_ "Description" SG_ 543 ATS_AstStFRestUnFldBtn "동승석 풋레스트 언폴딩 이동 (워크인 작동)";
BA_ "GenSigSendType" SG_ 543 ATS_AstStFRestUnFldBtn 4;
BA_ "UserSigValidity" SG_ 543 ATS_AstStFRestUnFldBtn 3;
BA_REL_ "GenSigTimeoutTime" BU_SG_REL_ APSM SG_ 543 ATS_AstStFRestUnFldBtn 1500;
BA_ "NetworkRequest" SG_ 543 ATS_AstStFRestUnFldBtn 0;
BA_ "NetworkRequestHoldingTime" SG_ 543 ATS_AstStFRestUnFldBtn 5000;
BA_ "Version" SG_ 543 ATS_AstStFRestUnFldBtn "19.09.02";
BA_ "Description" SG_ 543 ATS_AstTltUpBtn "동승석 틸트 UP 이동 (워크인 작동)";
BA_ "GenSigSendType" SG_ 543 ATS_AstTltUpBtn 4;
BA_ "UserSigValidity" SG_ 543 ATS_AstTltUpBtn 3;
BA_REL_ "GenSigTimeoutTime" BU_SG_REL_ APSM SG_ 543 ATS_AstTltUpBtn 1500;
BA_ "NetworkRequest" SG_ 543 ATS_AstTltUpBtn 0;
BA_ "NetworkRequestHoldingTime" SG_ 543 ATS_AstTltUpBtn 5000;
BA_ "Version" SG_ 543 ATS_AstTltUpBtn "19.12.00";
BA_ "Description" SG_ 543 ATS_AstTltDnBtn "동승석 틸트 DOWN 이동 (워크인 작동)";
BA_ "GenSigSendType" SG_ 543 ATS_AstTltDnBtn 4;
BA_ "UserSigValidity" SG_ 543 ATS_AstTltDnBtn 3;
BA_REL_ "GenSigTimeoutTime" BU_SG_REL_ APSM SG_ 543 ATS_AstTltDnBtn 1500;
BA_ "NetworkRequest" SG_ 543 ATS_AstTltDnBtn 0;
BA_ "NetworkRequestHoldingTime" SG_ 543 ATS_AstTltDnBtn 5000;
BA_ "Version" SG_ 543 ATS_AstTltDnBtn "19.12.00";
BA_ "GenMsgSendType" BO_ 623 0;
BA_ "Description" SG_ 623 ATS_ARSOpenCloseStatus "후석 암레스트 열림/닫힘 상태 신호";
BA_ "GenSigSendType" SG_ 623 ATS_ARSOpenCloseStatus 4;
BA_ "UserSigValidity" SG_ 623 ATS_ARSOpenCloseStatus 3;
BA_REL_ "GenSigTimeoutTime" BU_SG_REL_ RLPSM SG_ 623 ATS_ARSOpenCloseStatus 1500;
BA_ "NetworkRequest" SG_ 623 ATS_ARSOpenCloseStatus 0;
BA_ "NetworkRequestHoldingTime" SG_ 623 ATS_ARSOpenCloseStatus 5000;
BA_ "Version" SG_ 623 ATS_ARSOpenCloseStatus "20.12.05";
BA_ "Description" SG_ 623 ATS_RLLumbarDefBtn "후석 LH 럼버 배기 작동";
BA_ "GenSigSendType" SG_ 623 ATS_RLLumbarDefBtn 4;
BA_ "UserSigValidity" SG_ 623 ATS_RLLumbarDefBtn 3;
BA_REL_ "GenSigTimeoutTime" BU_SG_REL_ RLPSM SG_ 623 ATS_RLLumbarDefBtn 1500;
BA_ "NetworkRequest" SG_ 623 ATS_RLLumbarDefBtn 0;
BA_ "NetworkRequestHoldingTime" SG_ 623 ATS_RLLumbarDefBtn 5000;
BA_ "Version" SG_ 623 ATS_RLLumbarDefBtn "19.09.02";
BA_ "Description" SG_ 623 ATS_RLLumbarLowBtn "후석 LH 럼버 LOW 작동";
BA_ "GenSigSendType" SG_ 623 ATS_RLLumbarLowBtn 4;
BA_ "UserSigValidity" SG_ 623 ATS_RLLumbarLowBtn 3;
BA_REL_ "GenSigTimeoutTime" BU_SG_REL_ RLPSM SG_ 623 ATS_RLLumbarLowBtn 1500;
BA_ "NetworkRequest" SG_ 623 ATS_RLLumbarLowBtn 0;
BA_ "NetworkRequestHoldingTime" SG_ 623 ATS_RLLumbarLowBtn 5000;
BA_ "Version" SG_ 623 ATS_RLLumbarLowBtn "19.09.02";
BA_ "Description" SG_ 623 ATS_RLLumbarMidBtn "후석 LH 럼버 MID 작동";
BA_ "GenSigSendType" SG_ 623 ATS_RLLumbarMidBtn 4;
BA_ "UserSigValidity" SG_ 623 ATS_RLLumbarMidBtn 3;
BA_REL_ "GenSigTimeoutTime" BU_SG_REL_ RLPSM SG_ 623 ATS_RLLumbarMidBtn 1500;
BA_ "NetworkRequest" SG_ 623 ATS_RLLumbarMidBtn 0;
BA_ "NetworkRequestHoldingTime" SG_ 623 ATS_RLLumbarMidBtn 5000;
BA_ "Version" SG_ 623 ATS_RLLumbarMidBtn "19.09.02";
BA_ "Description" SG_ 623 ATS_RLLumbarUpBtn "후석 LH 럼버 UP 작동";
BA_ "GenSigSendType" SG_ 623 ATS_RLLumbarUpBtn 4;
BA_ "UserSigValidity" SG_ 623 ATS_RLLumbarUpBtn 3;
BA_REL_ "GenSigTimeoutTime" BU_SG_REL_ RLPSM SG_ 623 ATS_RLLumbarUpBtn 1500;
BA_ "NetworkRequest" SG_ 623 ATS_RLLumbarUpBtn 0;
BA_ "NetworkRequestHoldingTime" SG_ 623 ATS_RLLumbarUpBtn 5000;
BA_ "Version" SG_ 623 ATS_RLLumbarUpBtn "19.09.02";
BA_ "Description" SG_ 623 ATS_RLBolsterDefBtn "후석 LH 볼스터 배기 작동";
BA_ "GenSigSendType" SG_ 623 ATS_RLBolsterDefBtn 4;
BA_ "UserSigValidity" SG_ 623 ATS_RLBolsterDefBtn 3;
BA_REL_ "GenSigTimeoutTime" BU_SG_REL_ RLPSM SG_ 623 ATS_RLBolsterDefBtn 1500;
BA_ "NetworkRequest" SG_ 623 ATS_RLBolsterDefBtn 0;
BA_ "NetworkRequestHoldingTime" SG_ 623 ATS_RLBolsterDefBtn 5000;
BA_ "Version" SG_ 623 ATS_RLBolsterDefBtn "19.09.02";
BA_ "Description" SG_ 623 ATS_RLBolsterInfSw "후석 LH 볼스터 흡기 작동";
BA_ "GenSigSendType" SG_ 623 ATS_RLBolsterInfSw 4;
BA_ "UserSigValidity" SG_ 623 ATS_RLBolsterInfSw 3;
BA_REL_ "GenSigTimeoutTime" BU_SG_REL_ RLPSM SG_ 623 ATS_RLBolsterInfSw 1500;
BA_ "NetworkRequest" SG_ 623 ATS_RLBolsterInfSw 0;
BA_ "NetworkRequestHoldingTime" SG_ 623 ATS_RLBolsterInfSw 5000;
BA_ "Version" SG_ 623 ATS_RLBolsterInfSw "19.09.02";
BA_ "Description" SG_ 623 ATS_RRLumbarDefBtn "후석 LH 럼버 배기 작동";
BA_ "GenSigSendType" SG_ 623 ATS_RRLumbarDefBtn 4;
BA_ "UserSigValidity" SG_ 623 ATS_RRLumbarDefBtn 3;
BA_REL_ "GenSigTimeoutTime" BU_SG_REL_ RLPSM SG_ 623 ATS_RRLumbarDefBtn 1500;
BA_ "NetworkRequest" SG_ 623 ATS_RRLumbarDefBtn 0;
BA_ "NetworkRequestHoldingTime" SG_ 623 ATS_RRLumbarDefBtn 5000;
BA_ "Version" SG_ 623 ATS_RRLumbarDefBtn "19.09.02";
BA_ "Description" SG_ 623 ATS_RRLumbarLowBtn "후석 RH 럼버 LOW 작동";
BA_ "GenSigSendType" SG_ 623 ATS_RRLumbarLowBtn 4;
BA_ "UserSigValidity" SG_ 623 ATS_RRLumbarLowBtn 3;
BA_REL_ "GenSigTimeoutTime" BU_SG_REL_ RLPSM SG_ 623 ATS_RRLumbarLowBtn 1500;
BA_ "NetworkRequest" SG_ 623 ATS_RRLumbarLowBtn 0;
BA_ "NetworkRequestHoldingTime" SG_ 623 ATS_RRLumbarLowBtn 5000;
BA_ "Version" SG_ 623 ATS_RRLumbarLowBtn "19.09.02";
BA_ "Description" SG_ 623 ATS_RRLumbarMidBtn "후석 RH 럼버 MID 작동";
BA_ "GenSigSendType" SG_ 623 ATS_RRLumbarMidBtn 4;
BA_ "UserSigValidity" SG_ 623 ATS_RRLumbarMidBtn 3;
BA_REL_ "GenSigTimeoutTime" BU_SG_REL_ RLPSM SG_ 623 ATS_RRLumbarMidBtn 1500;
BA_ "NetworkRequest" SG_ 623 ATS_RRLumbarMidBtn 0;
BA_ "NetworkRequestHoldingTime" SG_ 623 ATS_RRLumbarMidBtn 5000;
BA_ "Version" SG_ 623 ATS_RRLumbarMidBtn "19.09.02";
BA_ "Description" SG_ 623 ATS_RRLumbarUpBtn "후석 RH 럼버 UP 작동";
BA_ "GenSigSendType" SG_ 623 ATS_RRLumbarUpBtn 4;
BA_ "UserSigValidity" SG_ 623 ATS_RRLumbarUpBtn 3;
BA_REL_ "GenSigTimeoutTime" BU_SG_REL_ RLPSM SG_ 623 ATS_RRLumbarUpBtn 1500;
BA_ "NetworkRequest" SG_ 623 ATS_RRLumbarUpBtn 0;
BA_ "NetworkRequestHoldingTime" SG_ 623 ATS_RRLumbarUpBtn 5000;
BA_ "Version" SG_ 623 ATS_RRLumbarUpBtn "19.09.02";
BA_ "Description" SG_ 623 ATS_RRBolsterDefBtn "후석 RH 볼스터 배기 작동";
BA_ "GenSigSendType" SG_ 623 ATS_RRBolsterDefBtn 4;
BA_ "UserSigValidity" SG_ 623 ATS_RRBolsterDefBtn 3;
BA_REL_ "GenSigTimeoutTime" BU_SG_REL_ RLPSM SG_ 623 ATS_RRBolsterDefBtn 1500;
BA_ "NetworkRequest" SG_ 623 ATS_RRBolsterDefBtn 0;
BA_ "NetworkRequestHoldingTime" SG_ 623 ATS_RRBolsterDefBtn 5000;
BA_ "Version" SG_ 623 ATS_RRBolsterDefBtn "19.09.02";
BA_ "Description" SG_ 623 ATS_RRBolsterInfSw "후석 RH 볼스터 흡기 작동";
BA_ "GenSigSendType" SG_ 623 ATS_RRBolsterInfSw 4;
BA_ "UserSigValidity" SG_ 623 ATS_RRBolsterInfSw 3;
BA_REL_ "GenSigTimeoutTime" BU_SG_REL_ RLPSM SG_ 623 ATS_RRBolsterInfSw 1500;
BA_ "NetworkRequest" SG_ 623 ATS_RRBolsterInfSw 0;
BA_ "NetworkRequestHoldingTime" SG_ 623 ATS_RRBolsterInfSw 5000;
BA_ "Version" SG_ 623 ATS_RRBolsterInfSw "19.09.02";
BA_ "GenMsgSendType" BO_ 1141 0;
BA_ "Description" SG_ 1141 Ast_SHVU_SeatOptSta "동승석 시트에 적용된 히터/통풍 옵션 사양";
BA_ "GenSigSendType" SG_ 1141 Ast_SHVU_SeatOptSta 4;
BA_ "UserSigValidity" SG_ 1141 Ast_SHVU_SeatOptSta 3;
BA_REL_ "GenSigTimeoutTime" BU_SG_REL_ CGW_CCU SG_ 1141 Ast_SHVU_SeatOptSta 1500;
BA_ "NetworkRequest" SG_ 1141 Ast_SHVU_SeatOptSta 0;
BA_ "NetworkRequestHoldingTime" SG_ 1141 Ast_SHVU_SeatOptSta 5000;
BA_ "Version" SG_ 1141 Ast_SHVU_SeatOptSta "19.01.04";
BA_ "Description" SG_ 1141 Ast_SHVU_HtSwHiIndSta "동승석 시트 열선 스위치 High Indicator 정보";
BA_ "GenSigSendType" SG_ 1141 Ast_SHVU_HtSwHiIndSta 4;
BA_ "UserSigValidity" SG_ 1141 Ast_SHVU_HtSwHiIndSta 3;
BA_REL_ "GenSigTimeoutTime" BU_SG_REL_ CGW_CCU SG_ 1141 Ast_SHVU_HtSwHiIndSta 1500;
BA_ "NetworkRequest" SG_ 1141 Ast_SHVU_HtSwHiIndSta 0;
BA_ "NetworkRequestHoldingTime" SG_ 1141 Ast_SHVU_HtSwHiIndSta 5000;
BA_ "Version" SG_ 1141 Ast_SHVU_HtSwHiIndSta "19.01.04";
BA_ "Description" SG_ 1141 Ast_SHVU_HtSwMidIndSta "동승석 시트 열선 스위치 Mid Indicator 정보";
BA_ "GenSigSendType" SG_ 1141 Ast_SHVU_HtSwMidIndSta 4;
BA_ "UserSigValidity" SG_ 1141 Ast_SHVU_HtSwMidIndSta 3;
BA_REL_ "GenSigTimeoutTime" BU_SG_REL_ CGW_CCU SG_ 1141 Ast_SHVU_HtSwMidIndSta 1500;
BA_ "NetworkRequest" SG_ 1141 Ast_SHVU_HtSwMidIndSta 0;
BA_ "NetworkRequestHoldingTime" SG_ 1141 Ast_SHVU_HtSwMidIndSta 5000;
BA_ "Version" SG_ 1141 Ast_SHVU_HtSwMidIndSta "19.01.04";
BA_ "Description" SG_ 1141 Ast_SHVU_HtSwLowIndSta "동승석 시트 열선 스위치 Low Indicator 정보";
BA_ "GenSigSendType" SG_ 1141 Ast_SHVU_HtSwLowIndSta 4;
BA_ "UserSigValidity" SG_ 1141 Ast_SHVU_HtSwLowIndSta 3;
BA_REL_ "GenSigTimeoutTime" BU_SG_REL_ CGW_CCU SG_ 1141 Ast_SHVU_HtSwLowIndSta 1500;
BA_ "NetworkRequest" SG_ 1141 Ast_SHVU_HtSwLowIndSta 0;
BA_ "NetworkRequestHoldingTime" SG_ 1141 Ast_SHVU_HtSwLowIndSta 5000;
BA_ "Version" SG_ 1141 Ast_SHVU_HtSwLowIndSta "19.01.04";
BA_ "Description" SG_ 1141 Ast_SHVU_VntSwHiIndSta "동승석 시트 통풍 스위치 High Indicator 정보";
BA_ "GenSigSendType" SG_ 1141 Ast_SHVU_VntSwHiIndSta 4;
BA_ "UserSigValidity" SG_ 1141 Ast_SHVU_VntSwHiIndSta 3;
BA_REL_ "GenSigTimeoutTime" BU_SG_REL_ CGW_CCU SG_ 1141 Ast_SHVU_VntSwHiIndSta 1500;
BA_ "NetworkRequest" SG_ 1141 Ast_SHVU_VntSwHiIndSta 0;
BA_ "NetworkRequestHoldingTime" SG_ 1141 Ast_SHVU_VntSwHiIndSta 5000;
BA_ "Version" SG_ 1141 Ast_SHVU_VntSwHiIndSta "19.01.04";
BA_ "Description" SG_ 1141 Ast_SHVU_VntSwMidIndSta "동승석 시트 통풍 스위치 Mid Indicator 정보";
BA_ "GenSigSendType" SG_ 1141 Ast_SHVU_VntSwMidIndSta 4;
BA_ "UserSigValidity" SG_ 1141 Ast_SHVU_VntSwMidIndSta 3;
BA_REL_ "GenSigTimeoutTime" BU_SG_REL_ CGW_CCU SG_ 1141 Ast_SHVU_VntSwMidIndSta 1500;
BA_ "NetworkRequest" SG_ 1141 Ast_SHVU_VntSwMidIndSta 0;
BA_ "NetworkRequestHoldingTime" SG_ 1141 Ast_SHVU_VntSwMidIndSta 5000;
BA_ "Version" SG_ 1141 Ast_SHVU_VntSwMidIndSta "19.01.04";
BA_ "Description" SG_ 1141 Ast_SHVU_VntSwLowIndSta "동승석 시트 통풍 스위치 Low Indicator 정보";
BA_ "GenSigSendType" SG_ 1141 Ast_SHVU_VntSwLowIndSta 4;
BA_ "UserSigValidity" SG_ 1141 Ast_SHVU_VntSwLowIndSta 3;
BA_REL_ "GenSigTimeoutTime" BU_SG_REL_ CGW_CCU SG_ 1141 Ast_SHVU_VntSwLowIndSta 1500;
BA_ "NetworkRequest" SG_ 1141 Ast_SHVU_VntSwLowIndSta 0;
BA_ "NetworkRequestHoldingTime" SG_ 1141 Ast_SHVU_VntSwLowIndSta 5000;
BA_ "Version" SG_ 1141 Ast_SHVU_VntSwLowIndSta "19.01.04";
BA_ "Description" SG_ 1141 Ast_SHVU_HtBlcUSMSta "Hetaer Balance Assistant USM R vaule";
BA_ "GenSigSendType" SG_ 1141 Ast_SHVU_HtBlcUSMSta 4;
BA_ "UserSigValidity" SG_ 1141 Ast_SHVU_HtBlcUSMSta 0;
BA_REL_ "GenSigTimeoutTime" BU_SG_REL_ CGW_CCU SG_ 1141 Ast_SHVU_HtBlcUSMSta 1500;
BA_ "Version" SG_ 1141 Ast_SHVU_HtBlcUSMSta "19.01.04";
BA_ "Description" SG_ 1141 Ast_SHVU_SeatHtOperSta "동승석 시트 현재 작동 중인 히터/통풍 단수 상태";
BA_ "GenSigSendType" SG_ 1141 Ast_SHVU_SeatHtOperSta 4;
BA_ "UserSigValidity" SG_ 1141 Ast_SHVU_SeatHtOperSta 3;
BA_REL_ "GenSigTimeoutTime" BU_SG_REL_ CGW_CCU SG_ 1141 Ast_SHVU_SeatHtOperSta 1500;
BA_ "NetworkRequest" SG_ 1141 Ast_SHVU_SeatHtOperSta 0;
BA_ "NetworkRequestHoldingTime" SG_ 1141 Ast_SHVU_SeatHtOperSta 5000;
BA_ "Version" SG_ 1141 Ast_SHVU_SeatHtOperSta "19.01.04";
BA_ "Description" SG_ 1141 Ast_SHVU_SeatOptSta_RHD "동승석 시트에 적용된 히터/통풍 옵션 사양(RHD)";
BA_ "GenSigSendType" SG_ 1141 Ast_SHVU_SeatOptSta_RHD 4;
BA_ "UserSigValidity" SG_ 1141 Ast_SHVU_SeatOptSta_RHD 3;
BA_REL_ "GenSigTimeoutTime" BU_SG_REL_ CGW_CCU SG_ 1141 Ast_SHVU_SeatOptSta_RHD 1500;
BA_ "NetworkRequest" SG_ 1141 Ast_SHVU_SeatOptSta_RHD 0;
BA_ "NetworkRequestHoldingTime" SG_ 1141 Ast_SHVU_SeatOptSta_RHD 5000;
BA_ "Version" SG_ 1141 Ast_SHVU_SeatOptSta_RHD "19.01.04";
BA_ "Description" SG_ 1141 Ast_SHVU_SeatHtOperSta_RHD "동승석 시트 현재 작동 중인 히터/통풍 단수 상태(RHD)";
BA_ "GenSigSendType" SG_ 1141 Ast_SHVU_SeatHtOperSta_RHD 4;
BA_ "UserSigValidity" SG_ 1141 Ast_SHVU_SeatHtOperSta_RHD 3;
BA_REL_ "GenSigTimeoutTime" BU_SG_REL_ CGW_CCU SG_ 1141 Ast_SHVU_SeatHtOperSta_RHD 1500;
BA_ "NetworkRequest" SG_ 1141 Ast_SHVU_SeatHtOperSta_RHD 0;
BA_ "NetworkRequestHoldingTime" SG_ 1141 Ast_SHVU_SeatHtOperSta_RHD 5000;
BA_ "Version" SG_ 1141 Ast_SHVU_SeatHtOperSta_RHD "19.01.04";
BA_ "Description" SG_ 1141 Ast_SHVU_HtSwHiIndSta_RHD "동승석 시트 열선 스위치 High Indicator 정보(RHD)";
BA_ "GenSigSendType" SG_ 1141 Ast_SHVU_HtSwHiIndSta_RHD 4;
BA_ "UserSigValidity" SG_ 1141 Ast_SHVU_HtSwHiIndSta_RHD 3;
BA_REL_ "GenSigTimeoutTime" BU_SG_REL_ CGW_CCU SG_ 1141 Ast_SHVU_HtSwHiIndSta_RHD 1500;
BA_ "NetworkRequest" SG_ 1141 Ast_SHVU_HtSwHiIndSta_RHD 0;
BA_ "NetworkRequestHoldingTime" SG_ 1141 Ast_SHVU_HtSwHiIndSta_RHD 5000;
BA_ "Version" SG_ 1141 Ast_SHVU_HtSwHiIndSta_RHD "19.01.04";
BA_ "Description" SG_ 1141 Ast_SHVU_HtSwMidIndSta_RHD "동승석 시트 열선 스위치 Mid Indicator 정보(RHD)";
BA_ "GenSigSendType" SG_ 1141 Ast_SHVU_HtSwMidIndSta_RHD 4;
BA_ "UserSigValidity" SG_ 1141 Ast_SHVU_HtSwMidIndSta_RHD 3;
BA_REL_ "GenSigTimeoutTime" BU_SG_REL_ CGW_CCU SG_ 1141 Ast_SHVU_HtSwMidIndSta_RHD 1500;
BA_ "NetworkRequest" SG_ 1141 Ast_SHVU_HtSwMidIndSta_RHD 0;
BA_ "NetworkRequestHoldingTime" SG_ 1141 Ast_SHVU_HtSwMidIndSta_RHD 5000;
BA_ "Version" SG_ 1141 Ast_SHVU_HtSwMidIndSta_RHD "19.01.04";
BA_ "Description" SG_ 1141 Ast_SHVU_HtSwLowIndSta_RHD "동승석 시트 열선 스위치 Low Indicator 정보(RHD)";
BA_ "GenSigSendType" SG_ 1141 Ast_SHVU_HtSwLowIndSta_RHD 4;
BA_ "UserSigValidity" SG_ 1141 Ast_SHVU_HtSwLowIndSta_RHD 3;
BA_REL_ "GenSigTimeoutTime" BU_SG_REL_ CGW_CCU SG_ 1141 Ast_SHVU_HtSwLowIndSta_RHD 1500;
BA_ "NetworkRequest" SG_ 1141 Ast_SHVU_HtSwLowIndSta_RHD 0;
BA_ "NetworkRequestHoldingTime" SG_ 1141 Ast_SHVU_HtSwLowIndSta_RHD 5000;
BA_ "Version" SG_ 1141 Ast_SHVU_HtSwLowIndSta_RHD "19.01.04";
BA_ "Description" SG_ 1141 Ast_SHVU_VntSwHiIndSta_RHD "동승석 시트 통풍 스위치 High Indicator 정보(RHD)";
BA_ "GenSigSendType" SG_ 1141 Ast_SHVU_VntSwHiIndSta_RHD 4;
BA_ "UserSigValidity" SG_ 1141 Ast_SHVU_VntSwHiIndSta_RHD 3;
BA_REL_ "GenSigTimeoutTime" BU_SG_REL_ CGW_CCU SG_ 1141 Ast_SHVU_VntSwHiIndSta_RHD 1500;
BA_ "NetworkRequest" SG_ 1141 Ast_SHVU_VntSwHiIndSta_RHD 0;
BA_ "NetworkRequestHoldingTime" SG_ 1141 Ast_SHVU_VntSwHiIndSta_RHD 5000;
BA_ "Version" SG_ 1141 Ast_SHVU_VntSwHiIndSta_RHD "19.01.04";
BA_ "Description" SG_ 1141 Ast_SHVU_VntSwMidIndSta_RHD "동승석 시트 통풍 스위치 Mid Indicator 정보(RHD)";
BA_ "GenSigSendType" SG_ 1141 Ast_SHVU_VntSwMidIndSta_RHD 4;
BA_ "UserSigValidity" SG_ 1141 Ast_SHVU_VntSwMidIndSta_RHD 3;
BA_REL_ "GenSigTimeoutTime" BU_SG_REL_ CGW_CCU SG_ 1141 Ast_SHVU_VntSwMidIndSta_RHD 1500;
BA_ "NetworkRequest" SG_ 1141 Ast_SHVU_VntSwMidIndSta_RHD 0;
BA_ "NetworkRequestHoldingTime" SG_ 1141 Ast_SHVU_VntSwMidIndSta_RHD 5000;
BA_ "Version" SG_ 1141 Ast_SHVU_VntSwMidIndSta_RHD "19.01.04";
BA_ "Description" SG_ 1141 Ast_SHVU_VntSwLowIndSta_RHD "동승석 시트 통풍 스위치 Low Indicator 정보(RHD)";
BA_ "GenSigSendType" SG_ 1141 Ast_SHVU_VntSwLowIndSta_RHD 4;
BA_ "UserSigValidity" SG_ 1141 Ast_SHVU_VntSwLowIndSta_RHD 3;
BA_REL_ "GenSigTimeoutTime" BU_SG_REL_ CGW_CCU SG_ 1141 Ast_SHVU_VntSwLowIndSta_RHD 1500;
BA_ "NetworkRequest" SG_ 1141 Ast_SHVU_VntSwLowIndSta_RHD 0;
BA_ "NetworkRequestHoldingTime" SG_ 1141 Ast_SHVU_VntSwLowIndSta_RHD 5000;
BA_ "Version" SG_ 1141 Ast_SHVU_VntSwLowIndSta_RHD "19.01.04";
BA_ "GenMsgSendType" BO_ 1026 0;
BA_ "Description" SG_ 1026 DAU_Crc3Val "The data area for CRC calculation is based on the data length (DLC) of the message DB.

The CRC shall be calculated over the entire data block (excluding the CRC bytes) including the user data, alive counter and Data ID 

 

- CRC Polynomial (0x1D) , Initial Value : 0x00, XOR value : 0xFF, Data ID Mode : Both, Data ID : Message ID + 0xF800 

- The initial value is for CRC calculation and the message should be sent with the calculated result value. 

The mathematical expression to 8 bit CRC polynomial is given here. G(x) = x8 + x4 + x3 + x2 + 1";
BA_ "GenSigSendType" SG_ 1026 DAU_Crc3Val 4;
BA_ "GenSigStartValue" SG_ 1026 DAU_Crc3Val 255;
BA_ "UserSigValidity" SG_ 1026 DAU_Crc3Val 0;
BA_REL_ "GenSigTimeoutTime" BU_SG_REL_ PSM SG_ 1026 DAU_Crc3Val 1500;
BA_ "NetworkRequest" SG_ 1026 DAU_Crc3Val 0;
BA_ "NetworkRequestHoldingTime" SG_ 1026 DAU_Crc3Val 5000;
BA_ "Version" SG_ 1026 DAU_Crc3Val "18.11.08";
BA_ "Description" SG_ 1026 DAU_AlvCnt3Val "For the first transmission request for a data element the counter shall be initialized with 0 and shall be incremented by 1

for every subsequent send request. When the counter reaches the maximum value(0xE), then it shall restart with 0 for the next send request";
BA_ "GenSigSendType" SG_ 1026 DAU_AlvCnt3Val 4;
BA_ "UserSigValidity" SG_ 1026 DAU_AlvCnt3Val 0;
BA_REL_ "GenSigTimeoutTime" BU_SG_REL_ PSM SG_ 1026 DAU_AlvCnt3Val 1500;
BA_ "NetworkRequest" SG_ 1026 DAU_AlvCnt3Val 0;
BA_ "NetworkRequestHoldingTime" SG_ 1026 DAU_AlvCnt3Val 5000;
BA_ "Version" SG_ 1026 DAU_AlvCnt3Val "18.11.08";
BA_ "Description" SG_ 1026 IMS_DrvrImsSwSetSta "IMS Set (or IMS Pass) switch on the driver side";
BA_ "GenSigSendType" SG_ 1026 IMS_DrvrImsSwSetSta 4;
BA_ "UserSigValidity" SG_ 1026 IMS_DrvrImsSwSetSta 0;
BA_REL_ "GenSigTimeoutTime" BU_SG_REL_ DPSS SG_ 1026 IMS_DrvrImsSwSetSta 1500;
BA_ "NetworkRequest" SG_ 1026 IMS_DrvrImsSwSetSta 0;
BA_ "NetworkRequestHoldingTime" SG_ 1026 IMS_DrvrImsSwSetSta 5000;
BA_ "Version" SG_ 1026 IMS_DrvrImsSwSetSta "19.08.05";
BA_ "Description" SG_ 1026 IMS_DrvrImsSw1Sta "IMS 1 switch on the driver side";
BA_ "GenSigSendType" SG_ 1026 IMS_DrvrImsSw1Sta 4;
BA_ "UserSigValidity" SG_ 1026 IMS_DrvrImsSw1Sta 0;
BA_REL_ "GenSigTimeoutTime" BU_SG_REL_ PSM SG_ 1026 IMS_DrvrImsSw1Sta 1500;
BA_ "NetworkRequest" SG_ 1026 IMS_DrvrImsSw1Sta 0;
BA_ "NetworkRequestHoldingTime" SG_ 1026 IMS_DrvrImsSw1Sta 5000;
BA_ "Version" SG_ 1026 IMS_DrvrImsSw1Sta "17.12.00";
BA_ "Description" SG_ 1026 IMS_DrvrImsSw2Sta "IMS 2 switch on the driver side";
BA_ "GenSigSendType" SG_ 1026 IMS_DrvrImsSw2Sta 4;
BA_ "UserSigValidity" SG_ 1026 IMS_DrvrImsSw2Sta 0;
BA_REL_ "GenSigTimeoutTime" BU_SG_REL_ PSM SG_ 1026 IMS_DrvrImsSw2Sta 1500;
BA_ "NetworkRequest" SG_ 1026 IMS_DrvrImsSw2Sta 0;
BA_ "NetworkRequestHoldingTime" SG_ 1026 IMS_DrvrImsSw2Sta 5000;
BA_ "Version" SG_ 1026 IMS_DrvrImsSw2Sta "17.12.00";
BA_ "Description" SG_ 1026 IMS_DrvrImsSwSmrtSta "IMS Smart (or IMS 3) switch on the driver side";
BA_ "GenSigSendType" SG_ 1026 IMS_DrvrImsSwSmrtSta 4;
BA_ "UserSigValidity" SG_ 1026 IMS_DrvrImsSwSmrtSta 0;
BA_REL_ "GenSigTimeoutTime" BU_SG_REL_ PSM SG_ 1026 IMS_DrvrImsSwSmrtSta 1500;
BA_ "NetworkRequest" SG_ 1026 IMS_DrvrImsSwSmrtSta 0;
BA_ "NetworkRequestHoldingTime" SG_ 1026 IMS_DrvrImsSwSmrtSta 5000;
BA_ "Version" SG_ 1026 IMS_DrvrImsSwSmrtSta "17.12.00";
BA_ "Description" SG_ 1026 IMS_LHOSMirPlyBckSta "This siganl indicates O/S Mirror moving state for IMS.";
BA_ "GenSigSendType" SG_ 1026 IMS_LHOSMirPlyBckSta 4;
BA_ "UserSigValidity" SG_ 1026 IMS_LHOSMirPlyBckSta 0;
BA_ "NetworkRequest" SG_ 1026 IMS_LHOSMirPlyBckSta 0;
BA_ "NetworkRequestHoldingTime" SG_ 1026 IMS_LHOSMirPlyBckSta 5000;
BA_ "Version" SG_ 1026 IMS_LHOSMirPlyBckSta "20.03.02";
BA_ "Description" SG_ 1026 IMS_GearPosRConfirmSta "Output_b_GearBoxRPosition_500msConfirmed";
BA_ "GenSigSendType" SG_ 1026 IMS_GearPosRConfirmSta 4;
BA_ "UserSigValidity" SG_ 1026 IMS_GearPosRConfirmSta 0;
BA_ "Version" SG_ 1026 IMS_GearPosRConfirmSta "19.10.07";
BA_ "GenMsgSendType" BO_ 1027 0;
BA_ "Description" SG_ 1027 DAU_Crc4Val "The data area for CRC calculation is based on the data length (DLC) of the message DB.

The CRC shall be calculated over the entire data block (excluding the CRC bytes) including the user data, alive counter and Data ID 

 

- CRC Polynomial (0x1D) , Initial Value : 0x00, XOR value : 0xFF, Data ID Mode : Both, Data ID : Message ID + 0xF800 

- The initial value is for CRC calculation and the message should be sent with the calculated result value. 

The mathematical expression to 8 bit CRC polynomial is given here. G(x) = x8 + x4 + x3 + x2 + 1";
BA_ "GenSigSendType" SG_ 1027 DAU_Crc4Val 4;
BA_ "GenSigStartValue" SG_ 1027 DAU_Crc4Val 255;
BA_ "UserSigValidity" SG_ 1027 DAU_Crc4Val 0;
BA_ "NetworkRequest" SG_ 1027 DAU_Crc4Val 0;
BA_ "NetworkRequestHoldingTime" SG_ 1027 DAU_Crc4Val 5000;
BA_ "Version" SG_ 1027 DAU_Crc4Val "18.11.08";
BA_ "Description" SG_ 1027 DAU_AlvCnt4Val "For the first transmission request for a data element the counter shall be initialized with 0 and shall be incremented by 1

for every subsequent send request. When the counter reaches the maximum value(0xE), then it shall restart with 0 for the next send request";
BA_ "GenSigSendType" SG_ 1027 DAU_AlvCnt4Val 4;
BA_ "UserSigValidity" SG_ 1027 DAU_AlvCnt4Val 0;
BA_ "NetworkRequest" SG_ 1027 DAU_AlvCnt4Val 0;
BA_ "NetworkRequestHoldingTime" SG_ 1027 DAU_AlvCnt4Val 5000;
BA_ "Version" SG_ 1027 DAU_AlvCnt4Val "18.11.08";
BA_ "GenSigSendType" SG_ 1027 Window_AsstPwrWdwAutoSwSta 4;
BA_ "UserSigValidity" SG_ 1027 Window_AsstPwrWdwAutoSwSta 0;
BA_ "NetworkRequest" SG_ 1027 Window_AsstPwrWdwAutoSwSta 0;
BA_ "NetworkRequestHoldingTime" SG_ 1027 Window_AsstPwrWdwAutoSwSta 5000;
BA_ "Version" SG_ 1027 Window_AsstPwrWdwAutoSwSta "17.12.00";
BA_ "Description" SG_ 1027 Window_AsstPwrWdwUpSwSta "-(Old)C_ASTPwdwMUpSWDAU";
BA_ "GenSigSendType" SG_ 1027 Window_AsstPwrWdwUpSwSta 4;
BA_ "UserSigValidity" SG_ 1027 Window_AsstPwrWdwUpSwSta 0;
BA_ "NetworkRequest" SG_ 1027 Window_AsstPwrWdwUpSwSta 0;
BA_ "NetworkRequestHoldingTime" SG_ 1027 Window_AsstPwrWdwUpSwSta 5000;
BA_ "Version" SG_ 1027 Window_AsstPwrWdwUpSwSta "17.12.00";
BA_ "Description" SG_ 1027 Window_AsstPwrWdwDnSwSta "-(Old)C_ASTPwdwAutoDownSWDAU";
BA_ "GenSigSendType" SG_ 1027 Window_AsstPwrWdwDnSwSta 4;
BA_ "UserSigValidity" SG_ 1027 Window_AsstPwrWdwDnSwSta 0;
BA_ "NetworkRequest" SG_ 1027 Window_AsstPwrWdwDnSwSta 0;
BA_ "NetworkRequestHoldingTime" SG_ 1027 Window_AsstPwrWdwDnSwSta 5000;
BA_ "Version" SG_ 1027 Window_AsstPwrWdwDnSwSta "17.12.00";
BA_ "GenSigSendType" SG_ 1027 Window_RrCrtSwSta 4;
BA_ "UserSigValidity" SG_ 1027 Window_RrCrtSwSta 0;
BA_ "NetworkRequest" SG_ 1027 Window_RrCrtSwSta 0;
BA_ "NetworkRequestHoldingTime" SG_ 1027 Window_RrCrtSwSta 5000;
BA_ "Version" SG_ 1027 Window_RrCrtSwSta "20.10.01";
BA_ "GenSigSendType" SG_ 1027 Window_RrLftPwrWdwAutoSwSta 4;
BA_ "UserSigValidity" SG_ 1027 Window_RrLftPwrWdwAutoSwSta 0;
BA_REL_ "GenSigTimeoutTime" BU_SG_REL_ RDC SG_ 1027 Window_RrLftPwrWdwAutoSwSta 1500;
BA_ "NetworkRequest" SG_ 1027 Window_RrLftPwrWdwAutoSwSta 0;
BA_ "NetworkRequestHoldingTime" SG_ 1027 Window_RrLftPwrWdwAutoSwSta 5000;
BA_ "Version" SG_ 1027 Window_RrLftPwrWdwAutoSwSta "17.12.00";
BA_ "Description" SG_ 1027 Window_RrLftPwrWdwUpSwSta "-(Old)C_RLPwdwMUpSWDAU";
BA_ "GenSigSendType" SG_ 1027 Window_RrLftPwrWdwUpSwSta 4;
BA_ "UserSigValidity" SG_ 1027 Window_RrLftPwrWdwUpSwSta 0;
BA_REL_ "GenSigTimeoutTime" BU_SG_REL_ RDC SG_ 1027 Window_RrLftPwrWdwUpSwSta 1500;
BA_ "NetworkRequest" SG_ 1027 Window_RrLftPwrWdwUpSwSta 0;
BA_ "NetworkRequestHoldingTime" SG_ 1027 Window_RrLftPwrWdwUpSwSta 5000;
BA_ "Version" SG_ 1027 Window_RrLftPwrWdwUpSwSta "17.12.00";
BA_ "Description" SG_ 1027 Window_RrLftPwrWdwDnSwSta "-(Old)C_RLPwdwMDnSWDAU";
BA_ "GenSigSendType" SG_ 1027 Window_RrLftPwrWdwDnSwSta 4;
BA_ "UserSigValidity" SG_ 1027 Window_RrLftPwrWdwDnSwSta 0;
BA_REL_ "GenSigTimeoutTime" BU_SG_REL_ RDC SG_ 1027 Window_RrLftPwrWdwDnSwSta 1500;
BA_ "Version" SG_ 1027 Window_RrLftPwrWdwDnSwSta "17.12.00";
BA_ "GenSigSendType" SG_ 1027 Window_RrRtPwrWdwAutoSwSta 4;
BA_ "UserSigValidity" SG_ 1027 Window_RrRtPwrWdwAutoSwSta 0;
BA_REL_ "GenSigTimeoutTime" BU_SG_REL_ RDC SG_ 1027 Window_RrRtPwrWdwAutoSwSta 1500;
BA_ "Version" SG_ 1027 Window_RrRtPwrWdwAutoSwSta "17.12.00";
BA_ "Description" SG_ 1027 Window_RrRtPwrWdwUpSwSta "-(Old)C_RRPwdwMUpSWDAU";
BA_ "GenSigSendType" SG_ 1027 Window_RrRtPwrWdwUpSwSta 4;
BA_ "UserSigValidity" SG_ 1027 Window_RrRtPwrWdwUpSwSta 0;
BA_REL_ "GenSigTimeoutTime" BU_SG_REL_ RDC SG_ 1027 Window_RrRtPwrWdwUpSwSta 1500;
BA_ "NetworkRequest" SG_ 1027 Window_RrRtPwrWdwUpSwSta 0;
BA_ "NetworkRequestHoldingTime" SG_ 1027 Window_RrRtPwrWdwUpSwSta 5000;
BA_ "Version" SG_ 1027 Window_RrRtPwrWdwUpSwSta "17.12.00";
BA_ "Description" SG_ 1027 Window_RrRtPwrWdwDnSwSta "-(Old)C_RRPwdwMDownSWDAU";
BA_ "GenSigSendType" SG_ 1027 Window_RrRtPwrWdwDnSwSta 4;
BA_ "UserSigValidity" SG_ 1027 Window_RrRtPwrWdwDnSwSta 0;
BA_REL_ "GenSigTimeoutTime" BU_SG_REL_ RDC SG_ 1027 Window_RrRtPwrWdwDnSwSta 1500;
BA_ "NetworkRequest" SG_ 1027 Window_RrRtPwrWdwDnSwSta 0;
BA_ "NetworkRequestHoldingTime" SG_ 1027 Window_RrRtPwrWdwDnSwSta 5000;
BA_ "Version" SG_ 1027 Window_RrRtPwrWdwDnSwSta "17.12.00";
BA_ "Description" SG_ 1027 Window_PwrWdwMaintainSta "-C_PwdwMain";
BA_ "GenSigSendType" SG_ 1027 Window_PwrWdwMaintainSta 4;
BA_ "UserSigValidity" SG_ 1027 Window_PwrWdwMaintainSta 0;
BA_REL_ "GenSigTimeoutTime" BU_SG_REL_ RDC SG_ 1027 Window_PwrWdwMaintainSta 1500;
BA_ "NetworkRequest" SG_ 1027 Window_PwrWdwMaintainSta 0;
BA_ "NetworkRequestHoldingTime" SG_ 1027 Window_PwrWdwMaintainSta 5000;
BA_ "Version" SG_ 1027 Window_PwrWdwMaintainSta "17.12.00";
BA_ "GenSigSendType" SG_ 1027 Window_PwrWdwMvInhbtSta 4;
BA_ "UserSigValidity" SG_ 1027 Window_PwrWdwMvInhbtSta 0;
BA_REL_ "GenSigTimeoutTime" BU_SG_REL_ RDC SG_ 1027 Window_PwrWdwMvInhbtSta 1500;
BA_REL_ "GenSigTimeoutTime" BU_SG_REL_ ATS SG_ 1027 Window_PwrWdwMvInhbtSta 1500;
BA_ "NetworkRequest" SG_ 1027 Window_PwrWdwMvInhbtSta 0;
BA_ "NetworkRequestHoldingTime" SG_ 1027 Window_PwrWdwMvInhbtSta 5000;
BA_ "Version" SG_ 1027 Window_PwrWdwMvInhbtSta "17.12.00";
BA_ "GenSigSendType" SG_ 1027 Window_WdwSafetyOpt 4;
BA_ "UserSigValidity" SG_ 1027 Window_WdwSafetyOpt 0;
BA_ "NetworkRequest" SG_ 1027 Window_WdwSafetyOpt 0;
BA_ "NetworkRequestHoldingTime" SG_ 1027 Window_WdwSafetyOpt 5000;
BA_ "Version" SG_ 1027 Window_WdwSafetyOpt "19.12.07";
BA_ "GenSigSendType" SG_ 1027 Window_DrvPwrWdwAutoSwSta 4;
BA_ "UserSigValidity" SG_ 1027 Window_DrvPwrWdwAutoSwSta 0;
BA_ "NetworkRequest" SG_ 1027 Window_DrvPwrWdwAutoSwSta 0;
BA_ "NetworkRequestHoldingTime" SG_ 1027 Window_DrvPwrWdwAutoSwSta 5000;
BA_ "Version" SG_ 1027 Window_DrvPwrWdwAutoSwSta "19.12.07";
BA_ "GenSigSendType" SG_ 1027 Window_DrvPwrWdwUpSwSta 4;
BA_ "UserSigValidity" SG_ 1027 Window_DrvPwrWdwUpSwSta 0;
BA_ "NetworkRequest" SG_ 1027 Window_DrvPwrWdwUpSwSta 0;
BA_ "NetworkRequestHoldingTime" SG_ 1027 Window_DrvPwrWdwUpSwSta 5000;
BA_ "Version" SG_ 1027 Window_DrvPwrWdwUpSwSta "19.12.07";
BA_ "GenSigSendType" SG_ 1027 Window_DrvPwrWdwDnSwSta 4;
BA_ "UserSigValidity" SG_ 1027 Window_DrvPwrWdwDnSwSta 0;
BA_ "NetworkRequest" SG_ 1027 Window_DrvPwrWdwDnSwSta 0;
BA_ "NetworkRequestHoldingTime" SG_ 1027 Window_DrvPwrWdwDnSwSta 5000;
BA_ "Version" SG_ 1027 Window_DrvPwrWdwDnSwSta "19.12.07";
BA_ "GenMsgSendType" BO_ 2214658049 0;
BA_ "GenMsgCycleTime" BO_ 2214658049 20;
BA_ "GenMsgCycleTimeFast" BO_ 2214658049 0;
BA_ "GenMsgNrOfRepetition" BO_ 2214658049 0;
BA_ "GenMsgDelayTime" BO_ 2214658049 0;
BA_ "VFrameFormat" BO_ 2214658049 1;
BA_ "Description" SG_ 2214658049 EMS_Crc2Val "The data area for CRC calculation is based on the data length (DLC) of the message DB.

The CRC shall be calculated over the entire data block (excluding the CRC bytes) including the user data, alive counter and Data ID

 

- CRC Polynomial (0x1021) , Initial Value : 0xFFFF, XOR value : 0x0000, Data ID : Message ID + 0xF800 

- The initial value is for CRC calculation and the message should be sent with the calculated result value. 

- The mathematical expression to 16 bit CRC polynomial is given here. G(x) = x16 + x12 + x5 + 1";
BA_ "GenSigStartValue" SG_ 2214658049 EMS_Crc2Val 65535;
BA_ "UserSigValidity" SG_ 2214658049 EMS_Crc2Val 3;
BA_ "RoutingFactor" SG_ 2214658049 EMS_Crc2Val 5;
BA_ "Version" SG_ 2214658049 EMS_Crc2Val "18.11.08";
BA_ "Description" SG_ 2214658049 EMS_AlvCnt2Val "For the first transmission request for a data element the counter shall be initialized with 0 and shall be incremented by 1 for every subsequent send request. 

When the counter reaches the maximum value(0xFF), then it shall restart with 0 for the next send request";
BA_ "UserSigValidity" SG_ 2214658049 EMS_AlvCnt2Val 3;
BA_ "RoutingFactor" SG_ 2214658049 EMS_AlvCnt2Val 5;
BA_ "Version" SG_ 2214658049 EMS_AlvCnt2Val "18.11.08";
BA_ "Description" SG_ 2214658049 ENG_BrkSwSta "This signal indicates that a brake switch is activated or not. When the brake switch is activated(pressed) its value is 01H otherwise its value is 00H.

If the EMS does not support this signal the value is 02H.



Physical range : 0 ... 100

Conversion : (PH) = (Unsigned)0.002 * (HEX)[%]";
BA_ "GenSigStartValue" SG_ 2214658049 ENG_BrkSwSta 1;
BA_ "UserSigValidity" SG_ 2214658049 ENG_BrkSwSta 3;
BA_ "RoutingFactor" SG_ 2214658049 ENG_BrkSwSta 5;
BA_ "Version" SG_ 2214658049 ENG_BrkSwSta "18.11.00";
BA_ "Description" SG_ 2214658049 ENG_ObdFrzFrmSta "An ECU which detects an OBD fault, requires the EMS to store a set of environmental conditions

(freeze frame). If the EMS follows this requirement it is acknowledged in OBD_FRF_ACK. Also the synchronization of OBD relevant ECUs is made by this signal:



Bit 3-5 is used for freeze frame acknowledgement.

Bit 2 is set, in case a driving cycle has started.

Bit 1 is set, in case a trip is finished.

Bit 0 is set, in case a warm up cycle is finished.



Bit 5, 4, 3 freeze frame status :

0 - No freeze frame stored

1 - Freeze frame requested by EMS

2 - Freeze frame requested by TCU

3 - Freeze frame requested by TCS

4~7 - Reserved";
BA_ "UserSigValidity" SG_ 2214658049 ENG_ObdFrzFrmSta 3;
BA_ "RoutingFactor" SG_ 2214658049 ENG_ObdFrzFrmSta 5;
BA_ "Version" SG_ 2214658049 ENG_ObdFrzFrmSta "17.12.00";
BA_ "Description" SG_ 2214658049 ENG_EngClntTempVal "Engine coolant temperature in EMS sensed via an A/D converter; converted into degrees centigrade (°C).";
BA_ "GenSigStartValue" SG_ 2214658049 ENG_EngClntTempVal 255;
BA_ "UserSigValidity" SG_ 2214658049 ENG_EngClntTempVal 3;
BA_ "RoutingFactor" SG_ 2214658049 ENG_EngClntTempVal 5;
BA_ "Version" SG_ 2214658049 ENG_EngClntTempVal "17.12.00";
BA_ "Description" SG_ 2214658049 ENG_MafCrctVal "The altitude correction factor MAF_FAC_ALTI_MMV is calculated from division of MAF by MAF_SUB_DIAG (=limp home-value for MAF) or from AMP_AD by 1013 mbar in order to take into account different atmospheric pressures at different altitudes.



The Initial-value of 1.0 indicates sea-level, whereas lower values indicate altitude. MAF_FAC_ALTI_MMV is limited to C_MAF_FAC_ALTI_MMV_MIN (=0.6) and C_MAF_FAC_ALTI_MMV_MAX (=1.1) by calibration.";
BA_ "GenSigStartValue" SG_ 2214658049 ENG_MafCrctVal 128;
BA_ "UserSigValidity" SG_ 2214658049 ENG_MafCrctVal 3;
BA_ "RoutingFactor" SG_ 2214658049 ENG_MafCrctVal 5;
BA_ "Version" SG_ 2214658049 ENG_MafCrctVal "17.12.00";
BA_ "Description" SG_ 2214658049 ENG_BattDscnctSta "The signal specifies that ECU has detected a disconnection of the battery since last driving cycle, and therefore has reset the adaptive values and failure memory.

If the EMS does not support this signal the value is 00H



The failure memory erasure is activated only if the calibration C_CONF_NVMY_RST is set to 1 inside the EMS.";
BA_ "UserSigValidity" SG_ 2214658049 ENG_BattDscnctSta 3;
BA_ "RoutingFactor" SG_ 2214658049 ENG_BattDscnctSta 5;
BA_ "Version" SG_ 2214658049 ENG_BattDscnctSta "17.12.00";
BA_ "Description" SG_ 2214658049 OBD_MilConfgVal "The signal specifies the Configuration of the MIL Handling and Failure Memory Management by ECU.";
BA_ "GenSigStartValue" SG_ 2214658049 OBD_MilConfgVal 3;
BA_ "UserSigValidity" SG_ 2214658049 OBD_MilConfgVal 3;
BA_ "RoutingFactor" SG_ 2214658049 OBD_MilConfgVal 5;
BA_ "Version" SG_ 2214658049 OBD_MilConfgVal "17.12.00";
BA_ "Description" SG_ 2214658049 ENG_EngSta "This signal indicates that a status of engine.";
BA_ "UserSigValidity" SG_ 2214658049 ENG_EngSta 3;
BA_ "RoutingFactor" SG_ 2214658049 ENG_EngSta 5;
BA_ "Version" SG_ 2214658049 ENG_EngSta "17.12.00";
BA_ "GenMsgSendType" BO_ 2214658050 0;
BA_ "GenMsgCycleTime" BO_ 2214658050 20;
BA_ "GenMsgCycleTimeFast" BO_ 2214658050 0;
BA_ "GenMsgNrOfRepetition" BO_ 2214658050 0;
BA_ "GenMsgDelayTime" BO_ 2214658050 0;
BA_ "VFrameFormat" BO_ 2214658050 1;
BA_ "Description" SG_ 2214658050 ENG_Ack4EngStpSta "The signal specifies the acknowledgement of the request for the operating state 'engine stopped'.";
BA_ "UserSigValidity" SG_ 2214658050 ENG_Ack4EngStpSta 3;
BA_ "RoutingFactor" SG_ 2214658050 ENG_Ack4EngStpSta 5;
BA_ "Version" SG_ 2214658050 ENG_Ack4EngStpSta "17.12.00";
BA_ "Description" SG_ 2214658050 ENG_AccDrvAlertDisp "If EMS sends the No Auto cruise engaged status or Auto cruise Disengaged status, 

Cluster shall display the status of Auto cruise.";
BA_ "TimeoutValue" SG_ 2214658050 ENG_AccDrvAlertDisp "0x0";
BA_ "UserSigValidity" SG_ 2214658050 ENG_AccDrvAlertDisp 3;
BA_ "RoutingFactor" SG_ 2214658050 ENG_AccDrvAlertDisp 5;
BA_ "Version" SG_ 2214658050 ENG_AccDrvAlertDisp "19.12.08";
BA_ "Description" SG_ 2214658050 ENG_ThrPosVal "The signal TPS is a measure of the throttle position.

The throttle position is determined via a potentiometer, which is connected mechanically to the throttle shaft. The voltage value, which is adjusted in the port via the voltage divider, is sensed in the EMS by an A/D converter. The lower mechanical stop (idle) is sensed by a learning algorithm (offset). If the EMS-ECU recognizes closed throttle then the value 20 H is carried over on the CAN. If the EMS-ECU detects full load, that means nearly perpendicular throttle position, then F5 H is carried over on the CAN bus. Even if the throttle position exceeds the full load detection throttle angle the transmitted HEX-value is limited to F5 H.



If an error is detected in sensing of the position, this is identified by the value FFH.";
BA_ "GenSigStartValue" SG_ 2214658050 ENG_ThrPosVal 32;
BA_ "UserSigValidity" SG_ 2214658050 ENG_ThrPosVal 3;
BA_ "RoutingFactor" SG_ 2214658050 ENG_ThrPosVal 5;
BA_ "Version" SG_ 2214658050 ENG_ThrPosVal "17.12.00";
BA_ "Description" SG_ 2214658050 ENG_OverDrvOffReq "This signal indicates that auto cruise control function requests over drive off of TCU. 

In general, the over drive off request is done by hardware. (i.e. line-to-line signal between an EMS and a TCU). However, some systems may not have external over drive off requetst signal line and for these systems OD_OFF_REQ signal can be used as the same function.";
BA_ "UserSigValidity" SG_ 2214658050 ENG_OverDrvOffReq 3;
BA_ "RoutingFactor" SG_ 2214658050 ENG_OverDrvOffReq 5;
BA_ "Version" SG_ 2214658050 ENG_OverDrvOffReq "17.12.00";
BA_ "Description" SG_ 2214658050 ENG_AccelPdlVal "The signal PV_AV_CAN is a measure of the Accelerator Pedal value.

The accelerator pedal value is determined via 2 pedal sensors, which are connected mechanically to the

accelerator pedal. If the EMS-ECU recognizes that the accelerator pedal is not activated, then the value

00 H is carried over on the CAN. If the EMS-ECU detects that the accelerator pedal is fully activated, then 3FEH is carried over on the CAN bus.

If an error is detected on both pedal sensor channels, this is identified by the value 3FFH.



Signal relationship between ACC_ACT and PV_AV_CAN :

The phase relationship between auto cruise control and PV_AV_CAN is as following figure. If an auto cruise control system is not installed or if cruise control is not activated in auto cruise control system installed vehicle then PV_AV_CAN has actual pedal position value. But if the auto cruise control is activated (actually speed control is performed by EMS), PV_AV_CAN should have modeling value even if a driver does not press the acceleration pedal.

If ACC_ACT is value(0), then PV_AV_CAN is APS Value.

If ACC_ACT is value(1), then PV_AV_CAN is Modeling Value.

* APS Value : Acceleration Pedal Sensor value.

* Modeling Value : Estimated APS value which is calculated by ECU logic considering engine control during the auto-cruise control is activated period. (e.g. estimated throttle value of

gasoline engine system or TPS model value of diesel engine system)

And also this value can be used as a driver intension for the shift control of an A/T during auto-cruise control.



Signal relationship between PV_AV_CAN and TPS in DIESEL system :

In a diesel engine vehicle which has an ETC system, basically TPS has APS value. And if auto cruise control is activated then both TPS and PV_AV_CAN should have modeling value which is estimated according to the actual fuel injection and other factors that affect engine torque.";
BA_ "UserSigValidity" SG_ 2214658050 ENG_AccelPdlVal 3;
BA_ "RoutingFactor" SG_ 2214658050 ENG_AccelPdlVal 5;
BA_ "Version" SG_ 2214658050 ENG_AccelPdlVal "18.01.01";
BA_ "Description" SG_ 2214658050 ENG_AccActSta "EMS sends the state of the cruise control via the signal ACC_ACT. 

If the EMS does not support this signal the value is 00H



If the cruise control is activated then ACC_ACT = 1. In this period, vehicle speed control (cruise control) is performed by the auto-cruise control function of ECU only (including acceleration control, deceleration control, etc.). 

Although “SCC set” switch is on (Cruise control is enabled), if the cruise control function is deactivated (e.g. when a driver presses an accel. pedal or a brake pedal to increase or to decarese vcehicle speed more or less than set speed) then ACC_ACT should be set to ‘0’.";
BA_ "UserSigValidity" SG_ 2214658050 ENG_AccActSta 3;
BA_ "RoutingFactor" SG_ 2214658050 ENG_AccActSta 5;
BA_ "Version" SG_ 2214658050 ENG_AccActSta "17.12.00";
BA_ "Description" SG_ 2214658050 ACC_CrsMainSwLmpSta "This signal indicates that an ECU requests cluster to turn on/off auto-cruise control “MAIN” switch indication lamp.



This signal is for the CAN-type cluster installed vehicled only.";
BA_ "UserSigValidity" SG_ 2214658050 ACC_CrsMainSwLmpSta 3;
BA_ "RoutingFactor" SG_ 2214658050 ACC_CrsMainSwLmpSta 5;
BA_ "Version" SG_ 2214658050 ACC_CrsMainSwLmpSta "17.12.00";
BA_ "Description" SG_ 2214658050 ACC_CrsSetSwLmpSta "This signal indicates that an ECU requests cluster to turn on/off auto-cruise control “SET” switch indication lamp.



This signal is for the CAN-type cluster installed vehicled only.";
BA_ "UserSigValidity" SG_ 2214658050 ACC_CrsSetSwLmpSta 3;
BA_ "RoutingFactor" SG_ 2214658050 ACC_CrsSetSwLmpSta 5;
BA_ "Version" SG_ 2214658050 ACC_CrsSetSwLmpSta "17.12.00";
BA_ "Description" SG_ 2214658050 ENG_SoakTimeErrSta "This signal indicates that information on soak time error.";
BA_ "UserSigValidity" SG_ 2214658050 ENG_SoakTimeErrSta 3;
BA_ "RoutingFactor" SG_ 2214658050 ENG_SoakTimeErrSta 5;
BA_ "Version" SG_ 2214658050 ENG_SoakTimeErrSta "17.12.00";
BA_ "Description" SG_ 2214658050 ENG_SoakTimeVal "The Signal SOAK_TIME means the duration from Engine Ignition Off to Ignition On.";
BA_ "UserSigValidity" SG_ 2214658050 ENG_SoakTimeVal 3;
BA_ "RoutingFactor" SG_ 2214658050 ENG_SoakTimeVal 5;
BA_ "Version" SG_ 2214658050 ENG_SoakTimeVal "17.12.00";
BA_ "Description" SG_ 2214658050 ENG_SprkTimeVal "This signal indicates output value of final spark timing from ECU which reflects torque intervention requests by ESC(TCS), SCC and TCU.



Physical range:

-35.625˚ … 0˚  =  00H .. 5FH (Retard)

0.375˚ … 60˚  =  60H .. FFH (Advance) 



Conversion:  (PH)=((HEX)-5FH) * 0.375 [˚ ] (Advance)

(PH)=(5FH-(HEX)) *(- 0.375) [˚ ] (Retard)";
BA_ "UserSigValidity" SG_ 2214658050 ENG_SprkTimeVal 3;
BA_ "RoutingFactor" SG_ 2214658050 ENG_SprkTimeVal 5;
BA_ "Version" SG_ 2214658050 ENG_SprkTimeVal "17.12.00";
BA_ "Description" SG_ 2214658050 ENG_CltchOpSta "This signal indicates that ECU has detected an operation of a clutch. Using this signal an ISG (Idle Stop & Go) system acts as an alternator or a starter.



If the EMS does not support this signal the value is 00H";
BA_ "UserSigValidity" SG_ 2214658050 ENG_CltchOpSta 3;
BA_ "RoutingFactor" SG_ 2214658050 ENG_CltchOpSta 5;
BA_ "Version" SG_ 2214658050 ENG_CltchOpSta "17.12.00";
BA_ "Description" SG_ 2214658050 EMS_BrkReq_Slope "Brake request at slope for anti-stall";
BA_ "UserSigValidity" SG_ 2214658050 EMS_BrkReq_Slope 3;
BA_ "RoutingFactor" SG_ 2214658050 EMS_BrkReq_Slope 5;
BA_ "Version" SG_ 2214658050 EMS_BrkReq_Slope "20.04.06";
BA_ "GenMsgSendType" BO_ 2214658051 0;
BA_ "GenMsgCycleTime" BO_ 2214658051 20;
BA_ "GenMsgCycleTimeFast" BO_ 2214658051 0;
BA_ "GenMsgNrOfRepetition" BO_ 2214658051 0;
BA_ "GenMsgDelayTime" BO_ 2214658051 0;
BA_ "VFrameFormat" BO_ 2214658051 1;
BA_ "Description" SG_ 2214658051 ENG_MinIndTqVal "The signal TQI_MIN is the minimum engine torque (minimum air charging rate) which can be fired without misfire including compensation factors such as atmospheric pressure and temperature.

It is not enough to keep the engine running without external power such as inertia.

Firing is impossible below TQI_MIN even if engine is turning by inertia. The friction torque is

always greater than TQI_MIN which is almost constant value across engine RPM.

This signal is used to determine when activation of automatic braking is required to achieve a certain deceleration or if the engine deceleration is sufficient under current conditions.



Under normal driving conditions the physical value of this signal is negative:

TQ_MIN[Nm] = TQI_MIN[Nm] - TQFR[Nm]



If MSB is 1, this signal is - value.

else, this signal is +value.

0~10bit is used for absolute value.";
BA_ "UserSigValidity" SG_ 2214658051 ENG_MinIndTqVal 3;
BA_ "RoutingFactor" SG_ 2214658051 ENG_MinIndTqVal 5;
BA_ "Version" SG_ 2214658051 ENG_MinIndTqVal "18.01.01";
BA_ "Description" SG_ 2214658051 ENG_TrgtTqVal "The signal TQI_TARGET is determined by an engine torque map with input which consists of  acceleration pedal value, MAF sensor, current RPM and etc. This signal reflects driver’s demand directly. 

But it does not depend on torque interventions realised due to reduction of airflow into the engine cylinders and due to ignition angle adjustment or injection/cylinder shut off.



In case of failures of the load signal (either MAF error or other errors depending on the system congiguration), a backup value is generated from specific index tables. The backup value mode is identified by the signal F_SUB_TQI. 



There is a specific phase relationship between the signals TQI_TARGET and F_SUB_TQI.



If MSB is 1, this signal is - value.

else, this signal is +value.

0~10bit is used for absolute value.";
BA_ "UserSigValidity" SG_ 2214658051 ENG_TrgtTqVal 3;
BA_ "RoutingFactor" SG_ 2214658051 ENG_TrgtTqVal 5;
BA_ "Version" SG_ 2214658051 ENG_TrgtTqVal "18.01.01";
BA_ "Description" SG_ 2214658051 ENG_MaxIndTqVal "The signal TQI_MAX is the current maximum indicated engine torque. This signal reflects the maximum engine torque under current conditions (engine speed, etc…).



Note : TQI_MAX must be transmitted actual engine torque including COT, thermal/spark efficiency etc..

 This means that the TQI_ACOR can reach to the TQI_MAX.

 If not possible, thTQI_MAX should be “ FFH” (99.6%) to reduce TCS/ESC variant.



TQ_MAX[Nm] = TQI_MAX[Nm] - TQFR[Nm]



If MSB is 1, this signal is - value.

else, this signal is +value.

0~10bit is used for absolute value.";
BA_ "UserSigValidity" SG_ 2214658051 ENG_MaxIndTqVal 3;
BA_ "RoutingFactor" SG_ 2214658051 ENG_MaxIndTqVal 5;
BA_ "Version" SG_ 2214658051 ENG_MaxIndTqVal "18.01.01";
BA_ "Description" SG_ 2214658051 ENG_AppAccelPdlSta "This signal indicates if the driver applies the accelerator pedal. 

The signal always indicates the actual operation of the accelerator pedal, independent from SCC mode.";
BA_ "UserSigValidity" SG_ 2214658051 ENG_AppAccelPdlSta 3;
BA_ "RoutingFactor" SG_ 2214658051 ENG_AppAccelPdlSta 5;
BA_ "Version" SG_ 2214658051 ENG_AppAccelPdlSta "17.12.00";
BA_ "Description" SG_ 2214658051 ENG_BrkCtrlReq "This signal indicates that if brake control request during cruise control or speed limiter is active or not. This signal is for prevention of unwanted vehicle speed increase during cruise control or speed limiter control mode.";
BA_ "UserSigValidity" SG_ 2214658051 ENG_BrkCtrlReq 3;
BA_ "RoutingFactor" SG_ 2214658051 ENG_BrkCtrlReq 5;
BA_ "Version" SG_ 2214658051 ENG_BrkCtrlReq "17.12.00";
BA_ "Description" SG_ 2214658051 ACC_DnShftCtrlReq "This signal indicates target gear for downshift control request during cruise control or speed limiter is active or not. This signal is for prevention of unwanted vehicle speed increase during cruise control or speed limiter control mode.";
BA_ "UserSigValidity" SG_ 2214658051 ACC_DnShftCtrlReq 3;
BA_ "RoutingFactor" SG_ 2214658051 ACC_DnShftCtrlReq 5;
BA_ "Version" SG_ 2214658051 ACC_DnShftCtrlReq "17.12.00";
BA_ "Description" SG_ 2214658051 ENG_ReprgmModRdySta "RepEMS_CHK indicates that the EMS system is ready to enter the reprogramming mode.

When battery voltage and SOC are too low, EMS doesn’t enter the reprogramming ready mode";
BA_ "UserSigValidity" SG_ 2214658051 ENG_ReprgmModRdySta 3;
BA_ "RoutingFactor" SG_ 2214658051 ENG_ReprgmModRdySta 5;
BA_ "Version" SG_ 2214658051 ENG_ReprgmModRdySta "17.12.00";
BA_ "Description" SG_ 2214658051 ENG_AafOpnReq "Active Air Flap open request for Thermostat diagnosis";
BA_ "UserSigValidity" SG_ 2214658051 ENG_AafOpnReq 3;
BA_ "RoutingFactor" SG_ 2214658051 ENG_AafOpnReq 5;
BA_ "Version" SG_ 2214658051 ENG_AafOpnReq "17.12.00";
BA_ "GenMsgSendType" BO_ 2214658052 0;
BA_ "GenMsgCycleTime" BO_ 2214658052 20;
BA_ "GenMsgCycleTimeFast" BO_ 2214658052 0;
BA_ "GenMsgNrOfRepetition" BO_ 2214658052 0;
BA_ "GenMsgDelayTime" BO_ 2214658052 0;
BA_ "VFrameFormat" BO_ 2214658052 1;
BA_ "Description" SG_ 2214658052 ENG_DclBrkCntrlReq "When current vehicle speed goes over set vehicle speed in the downhill during cruise control or speed limiter, ECU requests brake control to TCS with target deceleration. This is function of (Current vehicle speed - Set vehicle speed).";
BA_ "GenSigStartValue" SG_ 2214658052 ENG_DclBrkCntrlReq 4094;
BA_ "UserSigValidity" SG_ 2214658052 ENG_DclBrkCntrlReq 3;
BA_ "RoutingFactor" SG_ 2214658052 ENG_DclBrkCntrlReq 5;
BA_ "Version" SG_ 2214658052 ENG_DclBrkCntrlReq "17.12.00";
BA_ "Description" SG_ 2214658052 ENG_BstPrsrVal "Boost pressure for Turbo engine";
BA_ "UserSigValidity" SG_ 2214658052 ENG_BstPrsrVal 3;
BA_ "RoutingFactor" SG_ 2214658052 ENG_BstPrsrVal 5;
BA_ "Version" SG_ 2214658052 ENG_BstPrsrVal "17.12.00";
BA_ "Description" SG_ 2214658052 ENG_EngOilTempVal "engine oil temperature";
BA_ "GenSigStartValue" SG_ 2214658052 ENG_EngOilTempVal 53;
BA_ "UserSigValidity" SG_ 2214658052 ENG_EngOilTempVal 3;
BA_ "RoutingFactor" SG_ 2214658052 ENG_EngOilTempVal 5;
BA_ "Version" SG_ 2214658052 ENG_EngOilTempVal "17.12.00";
BA_ "Description" SG_ 2214658052 ENG_AmbtTempModelVal "Modeled Ambient temperature";
BA_ "GenSigStartValue" SG_ 2214658052 ENG_AmbtTempModelVal 164;
BA_ "UserSigValidity" SG_ 2214658052 ENG_AmbtTempModelVal 3;
BA_ "RoutingFactor" SG_ 2214658052 ENG_AmbtTempModelVal 5;
BA_ "Version" SG_ 2214658052 ENG_AmbtTempModelVal "17.12.00";
BA_ "Description" SG_ 2214658052 ENG_DpfWrngSta "The signal indicates the status of the 'DPF Warning Level'";
BA_ "UserSigValidity" SG_ 2214658052 ENG_DpfWrngSta 3;
BA_ "RoutingFactor" SG_ 2214658052 ENG_DpfWrngSta 5;
BA_ "Version" SG_ 2214658052 ENG_DpfWrngSta "17.12.00";
BA_ "Description" SG_ 2214658052 ENG_BattWrngLmpSta "The signal indicates the status of the 'Battery Warning Lamp'";
BA_ "UserSigValidity" SG_ 2214658052 ENG_BattWrngLmpSta 3;
BA_ "RoutingFactor" SG_ 2214658052 ENG_BattWrngLmpSta 5;
BA_ "Version" SG_ 2214658052 ENG_BattWrngLmpSta "17.12.00";
BA_ "Description" SG_ 2214658052 ENG_OilPrsrWrngLmpSta "The signal indicates the status of the 'Oil Pressure Warning Lamp'";
BA_ "UserSigValidity" SG_ 2214658052 ENG_OilPrsrWrngLmpSta 3;
BA_ "RoutingFactor" SG_ 2214658052 ENG_OilPrsrWrngLmpSta 5;
BA_ "Version" SG_ 2214658052 ENG_OilPrsrWrngLmpSta "17.12.00";
BA_ "Description" SG_ 2214658052 ENG_IsgInhbtLmpSta "The signal indicates the status of the 'ISG Inhibit Lamp'";
BA_ "UserSigValidity" SG_ 2214658052 ENG_IsgInhbtLmpSta 3;
BA_ "RoutingFactor" SG_ 2214658052 ENG_IsgInhbtLmpSta 5;
BA_ "Version" SG_ 2214658052 ENG_IsgInhbtLmpSta "17.12.00";
BA_ "GenMsgSendType" BO_ 2307022852 0;
BA_ "GenMsgCycleTimeFast" BO_ 2307022852 0;
BA_ "GenMsgNrOfRepetition" BO_ 2307022852 0;
BA_ "VFrameFormat" BO_ 2307022852 1;
BA_ "UserSigValidity" SG_ 2307022852 ENG_EngTyp4 3;
BA_ "RoutingFactor" SG_ 2307022852 ENG_EngTyp4 2;
BA_ "Version" SG_ 2307022852 ENG_EngTyp4 "17.11.00";
BA_ "Description" SG_ 2307022852 ENG_S_F "AMS/ISG system type indicator";
BA_ "UserSigValidity" SG_ 2307022852 ENG_S_F 3;
BA_ "RoutingFactor" SG_ 2307022852 ENG_S_F 2;
BA_ "Version" SG_ 2307022852 ENG_S_F "18.03.05";
BA_ "Description" SG_ 2307022852 ENG_S_F_GEN "system generation type indicator";
BA_ "UserSigValidity" SG_ 2307022852 ENG_S_F_GEN 3;
BA_ "RoutingFactor" SG_ 2307022852 ENG_S_F_GEN 2;
BA_ "Version" SG_ 2307022852 ENG_S_F_GEN "18.03.05";
BA_ "Description" SG_ 2307022852 ENG_IsgDispDetail "1. Detailed information display when Auto Stop conditions are not met.

2. ADAS based Auto Start information display.";
BA_ "UserSigValidity" SG_ 2307022852 ENG_IsgDispDetail 3;
BA_ "RoutingFactor" SG_ 2307022852 ENG_IsgDispDetail 2;
BA_ "Version" SG_ 2307022852 ENG_IsgDispDetail "19.05.02";
BA_ "UserSigValidity" SG_ 2307022852 ENG_EngTyp3 3;
BA_ "RoutingFactor" SG_ 2307022852 ENG_EngTyp3 2;
BA_ "Version" SG_ 2307022852 ENG_EngTyp3 "17.11.00";
BA_ "Description" SG_ 2307022852 ENG_TqStndValExt "The value TQ_STND specifies the torque to which the other torque quantities are referred. The conversion into a physical quantity provides a displayable range of 0...99.6094% of TQ_STND for the appropriate

signals.



※ Start Value : Appropriate value";
BA_ "UserSigValidity" SG_ 2307022852 ENG_TqStndValExt 3;
BA_REL_ "GenSigTimeoutTime" BU_SG_REL_ AMP SG_ 2307022852 ENG_TqStndValExt 1500;
BA_ "RoutingFactor" SG_ 2307022852 ENG_TqStndValExt 2;
BA_ "Version" SG_ 2307022852 ENG_TqStndValExt "18.01.03";
BA_ "Description" SG_ 2307022852 ENG_KNK_Warning "This signal indicates the result of KNK diagnosis. (KSDS)";
BA_ "UserSigValidity" SG_ 2307022852 ENG_KNK_Warning 4;
BA_ "RoutingFactor" SG_ 2307022852 ENG_KNK_Warning 2;
BA_ "Version" SG_ 2307022852 ENG_KNK_Warning "18.11.04";
BA_ "Description" SG_ 2307022852 ENG_OilLifeRatio "EMS calculates remaining engine oil life, and Cluster displays this information with % unit, in order to guide driver to change engine oil.";
BA_ "UserSigValidity" SG_ 2307022852 ENG_OilLifeRatio 3;
BA_ "RoutingFactor" SG_ 2307022852 ENG_OilLifeRatio 2;
BA_ "Version" SG_ 2307022852 ENG_OilLifeRatio "19.07.01";
BA_ "UserSigValidity" SG_ 2307022852 ENG_EngTyp2 3;
BA_REL_ "GenSigTimeoutTime" BU_SG_REL_ AMP SG_ 2307022852 ENG_EngTyp2 1500;
BA_ "RoutingFactor" SG_ 2307022852 ENG_EngTyp2 2;
BA_ "Version" SG_ 2307022852 ENG_EngTyp2 "20.10.00";
BA_ "Description" SG_ 2307022852 ENG_OilLifeEna "Cluster displays engine oil life warning and life ratio signal if this enabling bit is true.";
BA_ "UserSigValidity" SG_ 2307022852 ENG_OilLifeEna 3;
BA_ "RoutingFactor" SG_ 2307022852 ENG_OilLifeEna 2;
BA_ "Version" SG_ 2307022852 ENG_OilLifeEna "19.07.01";
BA_ "Description" SG_ 2307022852 ENG_OilLifeWarn "This signal indicates status of engine oil life warning.";
BA_ "UserSigValidity" SG_ 2307022852 ENG_OilLifeWarn 3;
BA_ "RoutingFactor" SG_ 2307022852 ENG_OilLifeWarn 2;
BA_ "Version" SG_ 2307022852 ENG_OilLifeWarn "19.07.01";
BA_ "UserSigValidity" SG_ 2307022852 ENG_PETyp 3;
BA_ "RoutingFactor" SG_ 2307022852 ENG_PETyp 2;
BA_ "Version" SG_ 2307022852 ENG_PETyp "20.10.00";
BA_ "UserSigValidity" SG_ 2307022852 ENG_EngTyp1 3;
BA_REL_ "GenSigTimeoutTime" BU_SG_REL_ AMP SG_ 2307022852 ENG_EngTyp1 1500;
BA_ "RoutingFactor" SG_ 2307022852 ENG_EngTyp1 2;
BA_ "Version" SG_ 2307022852 ENG_EngTyp1 "17.12.00";
BA_ "GenMsgCycleTime" BO_ 2315419649 0;
BA_ "VFrameFormat" BO_ 2315419649 1;
BA_ "Description" SG_ 2315419649 AVN_Random "Random number";
BA_ "GenSigSendType" SG_ 2315419649 AVN_Random 4;
BA_ "UserSigValidity" SG_ 2315419649 AVN_Random 0;
BA_REL_ "GenSigTimeoutTime" BU_SG_REL_ FPM SG_ 2315419649 AVN_Random 0;
BA_ "Version" SG_ 2315419649 AVN_Random "21.07.05";
BA_ "GenMsgSendType" BO_ 2315421185 0;
BA_ "VFrameFormat" BO_ 2315421185 1;
BA_ "Description" SG_ 2315421185 AVN_ReadyToSendData "This signal is sent when AVN is ready to send encryption data";
BA_ "GenSigSendType" SG_ 2315421185 AVN_ReadyToSendData 4;
BA_ "UserSigValidity" SG_ 2315421185 AVN_ReadyToSendData 0;
BA_REL_ "GenSigTimeoutTime" BU_SG_REL_ FPM SG_ 2315421185 AVN_ReadyToSendData 1500;
BA_ "Version" SG_ 2315421185 AVN_ReadyToSendData "19.09.06";
BA_ "Description" SG_ 2315421185 AVN_ISKLearnState "AVN State for encryption key learning";
BA_ "GenSigSendType" SG_ 2315421185 AVN_ISKLearnState 4;
BA_ "UserSigValidity" SG_ 2315421185 AVN_ISKLearnState 0;
BA_REL_ "GenSigTimeoutTime" BU_SG_REL_ FPM SG_ 2315421185 AVN_ISKLearnState 1500;
BA_ "Version" SG_ 2315421185 AVN_ISKLearnState "19.09.06";
BA_ "GenMsgCycleTime" BO_ 2466563329 0;
BA_ "VFrameFormat" BO_ 2466563329 1;
BA_ "Description" SG_ 2466563329 HU_ChgInCurrModSet "Charge current set signal";
BA_ "GenSigSendType" SG_ 2466563329 HU_ChgInCurrModSet 4;
BA_ "UserSigValidity" SG_ 2466563329 HU_ChgInCurrModSet 7;
BA_ "Version" SG_ 2466563329 HU_ChgInCurrModSet "19.08.06";
BA_ "Description" SG_ 2466563329 PushFeel_SET "on/off setting of push feel";
BA_ "GenSigSendType" SG_ 2466563329 PushFeel_SET 4;
BA_ "GenSigStartValue" SG_ 2466563329 PushFeel_SET 3;
BA_ "UserSigValidity" SG_ 2466563329 PushFeel_SET 3;
BA_ "Version" SG_ 2466563329 PushFeel_SET "19.07.02";
BA_ "GenSigSendType" SG_ 2466563329 HU_EnginePTSet 4;
BA_ "GenSigStartValue" SG_ 2466563329 HU_EnginePTSet 3;
BA_ "UserSigValidity" SG_ 2466563329 HU_EnginePTSet 3;
BA_ "NetworkRequest" SG_ 2466563329 HU_EnginePTSet 0;
BA_ "Version" SG_ 2466563329 HU_EnginePTSet "18.09.04";
BA_ "GenSigSendType" SG_ 2466563329 HU_DrivingModeSet 4;
BA_ "GenSigStartValue" SG_ 2466563329 HU_DrivingModeSet 7;
BA_ "UserSigValidity" SG_ 2466563329 HU_DrivingModeSet 3;
BA_ "NetworkRequest" SG_ 2466563329 HU_DrivingModeSet 0;
BA_ "Version" SG_ 2466563329 HU_DrivingModeSet "18.09.04";
BA_ "Description" SG_ 2466563329 SWRC_Sensitivity_SET "This signal is for the SWRC Optical Switch Sensitivity Setting";
BA_ "GenSigSendType" SG_ 2466563329 SWRC_Sensitivity_SET 4;
BA_ "GenSigStartValue" SG_ 2466563329 SWRC_Sensitivity_SET 3;
BA_ "UserSigValidity" SG_ 2466563329 SWRC_Sensitivity_SET 3;
BA_ "Version" SG_ 2466563329 SWRC_Sensitivity_SET "19.12.00";
BA_ "GenSigSendType" SG_ 2466563329 HU_EV_WinterMode 4;
BA_ "GenSigStartValue" SG_ 2466563329 HU_EV_WinterMode 3;
BA_ "UserSigValidity" SG_ 2466563329 HU_EV_WinterMode 7;
BA_ "Version" SG_ 2466563329 HU_EV_WinterMode "18.09.04";
BA_ "GenSigSendType" SG_ 2466563329 HU_4WDSet 4;
BA_ "GenSigStartValue" SG_ 2466563329 HU_4WDSet 3;
BA_ "UserSigValidity" SG_ 2466563329 HU_4WDSet 3;
BA_ "NetworkRequest" SG_ 2466563329 HU_4WDSet 0;
BA_ "Version" SG_ 2466563329 HU_4WDSet "18.09.04";
BA_ "GenSigSendType" SG_ 2466563329 C_SHVU_DTC_Mode 4;
BA_ "GenSigStartValue" SG_ 2466563329 C_SHVU_DTC_Mode 2;
BA_ "UserSigValidity" SG_ 2466563329 C_SHVU_DTC_Mode 3;
BA_REL_ "GenSigTimeoutTime" BU_SG_REL_ SHVU_RR SG_ 2466563329 C_SHVU_DTC_Mode 0;
BA_REL_ "GenSigTimeoutTime" BU_SG_REL_ ATS SG_ 2466563329 C_SHVU_DTC_Mode 0;
BA_ "Version" SG_ 2466563329 C_SHVU_DTC_Mode "18.09.04";
BA_ "GenSigSendType" SG_ 2466563329 HU_SusSet 4;
BA_ "GenSigStartValue" SG_ 2466563329 HU_SusSet 3;
BA_ "UserSigValidity" SG_ 2466563329 HU_SusSet 3;
BA_ "NetworkRequest" SG_ 2466563329 HU_SusSet 0;
BA_ "Version" SG_ 2466563329 HU_SusSet "18.09.04";
BA_ "GenSigSendType" SG_ 2466563329 HU_SteeringSet 4;
BA_ "GenSigStartValue" SG_ 2466563329 HU_SteeringSet 3;
BA_ "UserSigValidity" SG_ 2466563329 HU_SteeringSet 3;
BA_ "NetworkRequest" SG_ 2466563329 HU_SteeringSet 0;
BA_ "Version" SG_ 2466563329 HU_SteeringSet "18.09.04";
BA_ "GenSigSendType" SG_ 2466563329 HU_TgSoc_ScChg_Set 4;
BA_ "GenSigStartValue" SG_ 2466563329 HU_TgSoc_ScChg_Set 255;
BA_ "UserSigValidity" SG_ 2466563329 HU_TgSoc_ScChg_Set 7;
BA_ "Version" SG_ 2466563329 HU_TgSoc_ScChg_Set "18.09.04";
BA_ "GenSigSendType" SG_ 2466563329 HU_TgSoc_QcChg_Set 4;
BA_ "GenSigStartValue" SG_ 2466563329 HU_TgSoc_QcChg_Set 255;
BA_ "UserSigValidity" SG_ 2466563329 HU_TgSoc_QcChg_Set 7;
BA_ "Version" SG_ 2466563329 HU_TgSoc_QcChg_Set "18.09.04";
BA_ "GenSigSendType" SG_ 2466563329 HU_TgSoc_GPSChg_Set 4;
BA_ "GenSigStartValue" SG_ 2466563329 HU_TgSoc_GPSChg_Set 255;
BA_ "UserSigValidity" SG_ 2466563329 HU_TgSoc_GPSChg_Set 7;
BA_ "Version" SG_ 2466563329 HU_TgSoc_GPSChg_Set "18.09.04";
BA_ "Description" SG_ 2466563329 HU_UserApproval "Signal to send user decision on OTA approval.";
BA_ "GenSigSendType" SG_ 2466563329 HU_UserApproval 4;
BA_ "UserSigValidity" SG_ 2466563329 HU_UserApproval 0;
BA_ "Version" SG_ 2466563329 HU_UserApproval "21.03.01";
BA_ "Description" SG_ 2466563329 HU_OtaInfomationReq "제어기 OTA 관련 필요 정보를 요청하는 신호 (SW 버전, What's New, Download 진행율, Update 진행율)";
BA_ "GenSigSendType" SG_ 2466563329 HU_OtaInfomationReq 4;
BA_ "UserSigValidity" SG_ 2466563329 HU_OtaInfomationReq 0;
BA_ "Version" SG_ 2466563329 HU_OtaInfomationReq "19.12.01";
BA_ "GenMsgSendType" BO_ 1048 0;
BA_ "Description" SG_ 1048 ICU_Crc8Val "The data area for CRC calculation is based on the data length (DLC) of the message DB.

The CRC shall be calculated over the entire data block (excluding the CRC bytes) including the user data, alive counter and Data ID 

 

- CRC Polynomial (0x1D) , Initial Value : 0x00, XOR value : 0xFF, Data ID Mode : Both, Data ID : Message ID + 0xF800 

- The initial value is for CRC calculation and the message should be sent with the calculated result value. 

The mathematical expression to 8 bit CRC polynomial is given here. G(x) = x8 + x4 + x3 + x2 + 1";
BA_ "GenSigSendType" SG_ 1048 ICU_Crc8Val 4;
BA_ "GenSigStartValue" SG_ 1048 ICU_Crc8Val 255;
BA_ "UserSigValidity" SG_ 1048 ICU_Crc8Val 0;
BA_REL_ "GenSigTimeoutTime" BU_SG_REL_ vHS_M SG_ 1048 ICU_Crc8Val 1500;
BA_ "Version" SG_ 1048 ICU_Crc8Val "18.11.08";
BA_ "Description" SG_ 1048 HeatedSteerWheel_StrWhlHtrSwSta "This signal is used to sent information of current state of 

Steering Wheel Heated SW.

0x0:Off/0x1:On/0x2:Reserved/0x3:Invalid";
BA_ "GenSigSendType" SG_ 1048 HeatedSteerWheel_StrWhlHtrSwSta 4;
BA_ "GenSigStartValue" SG_ 1048 HeatedSteerWheel_StrWhlHtrSwSta 3;
BA_ "UserSigValidity" SG_ 1048 HeatedSteerWheel_StrWhlHtrSwSta 0;
BA_ "Version" SG_ 1048 HeatedSteerWheel_StrWhlHtrSwSta "17.12.00";
BA_ "Description" SG_ 1048 ICU_AlvCnt8Val "For the first transmission request for a data element the counter shall be initialized with 0 and shall be incremented by 1

for every subsequent send request. When the counter reaches the maximum value(0xE), then it shall restart with 0 for the next send request";
BA_ "GenSigSendType" SG_ 1048 ICU_AlvCnt8Val 4;
BA_ "UserSigValidity" SG_ 1048 ICU_AlvCnt8Val 0;
BA_ "Version" SG_ 1048 ICU_AlvCnt8Val "18.11.08";
BA_ "Description" SG_ 1048 DriveTypeOption "Drive Type Option

This signal is used to determine driver's seat position('Drive Type') about this vehicle.";
BA_ "GenSigSendType" SG_ 1048 DriveTypeOption 4;
BA_ "UserSigValidity" SG_ 1048 DriveTypeOption 0;
BA_REL_ "GenSigTimeoutTime" BU_SG_REL_ PSM SG_ 1048 DriveTypeOption 1500;
BA_REL_ "GenSigTimeoutTime" BU_SG_REL_ RLPSM SG_ 1048 DriveTypeOption 1500;
BA_REL_ "GenSigTimeoutTime" BU_SG_REL_ RRPSM SG_ 1048 DriveTypeOption 1500;
BA_REL_ "GenSigTimeoutTime" BU_SG_REL_ SHVU_RR SG_ 1048 DriveTypeOption 1500;
BA_REL_ "GenSigTimeoutTime" BU_SG_REL_ ATS SG_ 1048 DriveTypeOption 1500;
BA_ "NetworkRequest" SG_ 1048 DriveTypeOption 0;
BA_ "NetworkRequestHoldingTime" SG_ 1048 DriveTypeOption 5000;
BA_ "Version" SG_ 1048 DriveTypeOption "17.12.00";
BA_ "Description" SG_ 1048 Warn_RrLftSBRMATSwSta "Rear Left Seated State";
BA_ "GenSigSendType" SG_ 1048 Warn_RrLftSBRMATSwSta 4;
BA_ "UserSigValidity" SG_ 1048 Warn_RrLftSBRMATSwSta 0;
BA_ "NetworkRequest" SG_ 1048 Warn_RrLftSBRMATSwSta 0;
BA_ "NetworkRequestHoldingTime" SG_ 1048 Warn_RrLftSBRMATSwSta 5000;
BA_ "Version" SG_ 1048 Warn_RrLftSBRMATSwSta "17.12.00";
BA_ "Description" SG_ 1048 Warn_RrRhtSBRMATSwSta "Rear Right Seated State";
BA_ "GenSigSendType" SG_ 1048 Warn_RrRhtSBRMATSwSta 4;
BA_ "UserSigValidity" SG_ 1048 Warn_RrRhtSBRMATSwSta 0;
BA_ "NetworkRequest" SG_ 1048 Warn_RrRhtSBRMATSwSta 0;
BA_ "NetworkRequestHoldingTime" SG_ 1048 Warn_RrRhtSBRMATSwSta 5000;
BA_ "Version" SG_ 1048 Warn_RrRhtSBRMATSwSta "17.12.00";
BA_ "Description" SG_ 1048 StrWheelHeatIndSta "Indicator of StrgWheel heater";
BA_ "GenSigSendType" SG_ 1048 StrWheelHeatIndSta 4;
BA_ "UserSigValidity" SG_ 1048 StrWheelHeatIndSta 3;
BA_ "Version" SG_ 1048 StrWheelHeatIndSta "17.12.00";
BA_ "Description" SG_ 1048 Lamp_FootLampOnReq "Foot Lamp Command";
BA_ "GenSigSendType" SG_ 1048 Lamp_FootLampOnReq 4;
BA_ "UserSigValidity" SG_ 1048 Lamp_FootLampOnReq 0;
BA_ "NetworkRequest" SG_ 1048 Lamp_FootLampOnReq 0;
BA_ "NetworkRequestHoldingTime" SG_ 1048 Lamp_FootLampOnReq 5000;
BA_ "Version" SG_ 1048 Lamp_FootLampOnReq "17.12.00";
BA_ "Description" SG_ 1048 Lamp_MoodLampOnReq "Mood lamp command";
BA_ "GenSigSendType" SG_ 1048 Lamp_MoodLampOnReq 4;
BA_ "UserSigValidity" SG_ 1048 Lamp_MoodLampOnReq 0;
BA_ "NetworkRequest" SG_ 1048 Lamp_MoodLampOnReq 0;
BA_ "NetworkRequestHoldingTime" SG_ 1048 Lamp_MoodLampOnReq 5000;
BA_ "Version" SG_ 1048 Lamp_MoodLampOnReq "17.12.00";
BA_ "Description" SG_ 1048 ICU_PowerAutoCutModSta "ICU Delivery Mode State";
BA_ "GenSigSendType" SG_ 1048 ICU_PowerAutoCutModSta 4;
BA_ "UserSigValidity" SG_ 1048 ICU_PowerAutoCutModSta 3;
BA_ "Version" SG_ 1048 ICU_PowerAutoCutModSta "17.12.00";
BA_ "Description" SG_ 1048 ICU_SoCBattStaMsgReq "Determine if soc level is warning or alert.";
BA_ "GenSigSendType" SG_ 1048 ICU_SoCBattStaMsgReq 4;
BA_ "GenSigStartValue" SG_ 1048 ICU_SoCBattStaMsgReq 3;
BA_ "UserSigValidity" SG_ 1048 ICU_SoCBattStaMsgReq 0;
BA_ "Version" SG_ 1048 ICU_SoCBattStaMsgReq "17.12.00";
BA_ "Description" SG_ 1048 C_ICUPowerAutoCutType "ICU Power Management Autocut Spec Information";
BA_ "GenSigSendType" SG_ 1048 C_ICUPowerAutoCutType 4;
BA_ "UserSigValidity" SG_ 1048 C_ICUPowerAutoCutType 0;
BA_ "NetworkRequest" SG_ 1048 C_ICUPowerAutoCutType 0;
BA_ "Version" SG_ 1048 C_ICUPowerAutoCutType "18.08.00";
BA_ "Description" SG_ 1048 Brake_SwSta_ICU "Brake Switch Status";
BA_ "GenSigSendType" SG_ 1048 Brake_SwSta_ICU 4;
BA_ "UserSigValidity" SG_ 1048 Brake_SwSta_ICU 0;
BA_ "NetworkRequest" SG_ 1048 Brake_SwSta_ICU 0;
BA_ "NetworkRequestHoldingTime" SG_ 1048 Brake_SwSta_ICU 5000;
BA_ "Version" SG_ 1048 Brake_SwSta_ICU "17.12.00";
BA_ "GenMsgSendType" BO_ 1049 0;
BA_ "Description" SG_ 1049 ICU_Crc9Val "The data area for CRC calculation is based on the data length (DLC) of the message DB.

The CRC shall be calculated over the entire data block (excluding the CRC bytes) including the user data, alive counter and Data ID 

 

- CRC Polynomial (0x1D) , Initial Value : 0x00, XOR value : 0xFF, Data ID Mode : Both, Data ID : Message ID + 0xF800 

- The initial value is for CRC calculation and the message should be sent with the calculated result value. 

The mathematical expression to 8 bit CRC polynomial is given here. G(x) = x8 + x4 + x3 + x2 + 1";
BA_ "GenSigSendType" SG_ 1049 ICU_Crc9Val 4;
BA_ "GenSigStartValue" SG_ 1049 ICU_Crc9Val 255;
BA_ "UserSigValidity" SG_ 1049 ICU_Crc9Val 0;
BA_REL_ "GenSigTimeoutTime" BU_SG_REL_ vHS_M SG_ 1049 ICU_Crc9Val 1500;
BA_ "Version" SG_ 1049 ICU_Crc9Val "18.11.08";
BA_ "Description" SG_ 1049 ICU_AlvCnt9Val "For the first transmission request for a data element the counter shall be initialized with 0 and shall be incremented by 1

for every subsequent send request. When the counter reaches the maximum value(0xE), then it shall restart with 0 for the next send request";
BA_ "GenSigSendType" SG_ 1049 ICU_AlvCnt9Val 4;
BA_ "UserSigValidity" SG_ 1049 ICU_AlvCnt9Val 0;
BA_ "Version" SG_ 1049 ICU_AlvCnt9Val "18.11.08";
BA_ "Description" SG_ 1049 ICU_BS1IBAT_Conversion "This is Battery current as measured by battery sensor.

The resolution is 10mA



- 0x3FFFF : 262,143 (Error) , 0x00000 ~ 0x3A980 : 0 ~ 240,000

- Physical value min. : (0 * 10mA) + (-1,200,000) = -1,200 A

- Physical value max. : (240,000 * 10mA) + (-1,200,000) = 1,200 A";
BA_ "GenSigSendType" SG_ 1049 ICU_BS1IBAT_Conversion 4;
BA_ "UserSigValidity" SG_ 1049 ICU_BS1IBAT_Conversion 3;
BA_ "Version" SG_ 1049 ICU_BS1IBAT_Conversion "18.10.09";
BA_ "Description" SG_ 1049 ICU_BS1BatVol "This is the actual battery voltage as measured on the battery pole by battery sensor.



The resolution is 1mV.";
BA_ "GenSigSendType" SG_ 1049 ICU_BS1BatVol 4;
BA_ "GenSigStartValue" SG_ 1049 ICU_BS1BatVol 16383;
BA_ "UserSigValidity" SG_ 1049 ICU_BS1BatVol 3;
BA_ "Version" SG_ 1049 ICU_BS1BatVol "18.08.03";
BA_ "Description" SG_ 1049 ICU_BS1BatTemp "This is actual battery electrolyte temperature value by battery sensor.



The value is calculated by a Battery Temperature Model, depending on measured temperature of the battery pole.





The resolution is 0.5℃.";
BA_ "GenSigSendType" SG_ 1049 ICU_BS1BatTemp 4;
BA_ "GenSigStartValue" SG_ 1049 ICU_BS1BatTemp 511;
BA_ "UserSigValidity" SG_ 1049 ICU_BS1BatTemp 3;
BA_ "Version" SG_ 1049 ICU_BS1BatTemp "18.08.03";
BA_ "Description" SG_ 1049 ICU_BS1ValFlagSta "setting condition is depending on battery sensor self diagnosis information";
BA_ "GenSigSendType" SG_ 1049 ICU_BS1ValFlagSta 4;
BA_ "GenSigStartValue" SG_ 1049 ICU_BS1ValFlagSta 1;
BA_ "UserSigValidity" SG_ 1049 ICU_BS1ValFlagSta 3;
BA_ "Version" SG_ 1049 ICU_BS1ValFlagSta "17.12.00";
BA_ "GenSigSendType" SG_ 1049 ICU_BS1ErrRes 4;
BA_ "GenSigStartValue" SG_ 1049 ICU_BS1ErrRes 1;
BA_ "UserSigValidity" SG_ 1049 ICU_BS1ErrRes 3;
BA_ "Version" SG_ 1049 ICU_BS1ErrRes "17.12.00";
BA_ "GenMsgSendType" BO_ 1029 0;
BA_ "Description" SG_ 1029 ICU_Crc12Val "The data area for CRC calculation is based on the data length (DLC) of the message DB.

The CRC shall be calculated over the entire data block (excluding the CRC bytes) including the user data, alive counter and Data ID 

 

- CRC Polynomial (0x1D) , Initial Value : 0x00, XOR value : 0xFF, Data ID Mode : Both, Data ID : Message ID + 0xF800 

- The initial value is for CRC calculation and the message should be sent with the calculated result value. 

The mathematical expression to 8 bit CRC polynomial is given here. G(x) = x8 + x4 + x3 + x2 + 1";
BA_ "GenSigSendType" SG_ 1029 ICU_Crc12Val 4;
BA_ "GenSigStartValue" SG_ 1029 ICU_Crc12Val 255;
BA_ "UserSigValidity" SG_ 1029 ICU_Crc12Val 0;
BA_REL_ "GenSigTimeoutTime" BU_SG_REL_ vHS_M SG_ 1029 ICU_Crc12Val 1500;
BA_ "Version" SG_ 1029 ICU_Crc12Val "18.11.08";
BA_ "Description" SG_ 1029 ICU_AlvCnt12Val "For the first transmission request for a data element the counter shall be initialized with 0 and shall be incremented by 1

for every subsequent send request. When the counter reaches the maximum value(0xE), then it shall restart with 0 for the next send request";
BA_ "GenSigSendType" SG_ 1029 ICU_AlvCnt12Val 4;
BA_ "UserSigValidity" SG_ 1029 ICU_AlvCnt12Val 0;
BA_ "Version" SG_ 1029 ICU_AlvCnt12Val "18.11.08";
BA_ "Description" SG_ 1029 ICU_BattMngAlert "This signal is for battery discharge warning.

1bit : Hazard

2bit : Tail

3bit~8bit : Reserved";
BA_ "GenSigSendType" SG_ 1029 ICU_BattMngAlert 4;
BA_ "UserSigValidity" SG_ 1029 ICU_BattMngAlert 0;
BA_ "Version" SG_ 1029 ICU_BattMngAlert "20.07.10";
VAL_ 2273435649 HDA_OptUsmSta 0 "Not Applied" 1 "Function Off" 2 "Function On" 3 "Reserved" 4 "Reserved" 5 "Reserved" 6 "Reserved" 7 "Invalid (Fail)" ;
VAL_ 2273435649 HDA_CntrlModSta 0 "System OFF (Default)" 1 "System STANDBY" 2 "System ACTIVE" 3 "Reserved" ;
VAL_ 2273435649 HDA_InfoPUDis 0 "No pop-up" 1 "system start pop-up" 2 "system auto disengaged pop-up by highway off" 3 "System Fail pop up (LFA)" 4 "System Fail pop up (HDA)" 5 "Hands-off pop up" 6 "Hands-off pop up w/ sound" 7 "Reserved" ;
VAL_ 2273435649 HDP_AutoCallReqSta 0 "No request" 1 "HDP MRM Auto Call Request" 2 "Reserved" 3 "Reserved" 4 "Reserved" 5 "Reserved" 6 "Cancel the HDP Auto Call" 7 "Invalid" ;
VAL_ 2273435649 HDP_DispBarSta 0 "Not Display" 1 "Reserved" 2 "Reserved" 3 "Amber Display" 4 "Red Display" 5 "Reserved" 6 "Reserved" 7 "Reserved" 8 "Reserved" 9 "Reserved" 10 "Reserved" 11 "Reserved" 12 "Reserved" 13 "Reserved" 14 "Reserved" 15 "Reserved" ;
VAL_ 2273435649 HDP_OptInfoSta 0 "HDP option not applied" 1 "HDP option applied" 2 "Reserved" 3 "Reserved" ;
VAL_ 2273435649 HDA_LFA_SymSta 0 "Off" 1 "Gray" 2 "Green" 3 "White blink" ;
VAL_ 2273435649 HDA_LFA_WrnSnd 0 "Off" 1 "Additional Warning Sound" 2 "Reserved" 3 "Error indicator" ;
VAL_ 2273435649 HDA_InfoPUDis1 0 "No Pop-up" 1 "System Automatic off (LFA)" 2 "System Automatic off (HDA)" 3 "Reserved" 4 "Reserved" 5 "Reserved" 6 "Not Used" 7 "Error Indicator" ;
VAL_ 2273435649 HDP_ActvSta 0 "Not Active" 1 "Active" 2 "Reserved" 3 "Reserved" ;
VAL_ 2273435649 HDP_SysSta 0 "OFF" 1 "Standby" 2 "DDT" 3 "TD" 4 "MRM" 5 "EM" 6 "Reserved" 15 "Reserved" ;
VAL_ 2273435649 HDP_FailureMode 0 "Normal" 1 "Blockage" 2 "Failure" ;
VAL_ 2273435650 HDP_ObstacleDstVal 0 "0x0x0~0x5DC:Distance" 1500 "0x0x0~0x5DC:Distance" 1501 "0x5DD~0x7FD:Reserved" 2045 "0x5DD~0x7FD:Reserved" 2046 "Default" 2047 "Error" ;
VAL_ 2273435650 HDP_ObstacleLatPosVal 0 "0x0x0~0x1FD:Position Value" 509 "0x0x0~0x1FD:Position Value" 510 "Default" 511 "Error" ;
VAL_ 2273435650 HDP_InfoPUDis 0 "None" 1 "HDP Active" 2 "HDP TD Lv1" 3 "HDP TD Lv2" 4 "HDP MRM" 5 "HDP EM" 6 "HDP Automatic system off (자동 해제)" 7 "HDP Driver availability warning (운전자 상태 경고)" 8 "HDP Unable to start warning (활성화 불가)" 9 "HDP guides user to change lane (경로 변경 유도 안내)" 10 "Reserved" 11 "Reserved" 12 "Reserved" 13 "Reserved" 14 "Reserved" 15 "Reserved" ;
VAL_ 2273435650 HDP_WrngTypPUDis 0 "None" 1 "Stop the accelerator pedal input" 2 "Stop the brake pedal input" 3 "Inability to set ADAS function" 4 "Reserved" 5 "Reserved" 6 "Reserved" 7 "Reserved" 8 "Reserved" 9 "Reserved" 10 "Reserved" 11 "Reserved" 12 "Reserved" 13 "Reserved" 14 "Reserved" 15 "Reserved" 16 "Inform the set speed changed" 17 "Reserved" 18 "Reserved" 19 "Reserved" 20 "Reserved" 21 "Reserved" 22 "Reserved" 23 "Reserved" 24 "Reserved" 25 "Reserved" 26 "Reserved" 27 "Reserved" 28 "Reserved" 29 "Reserved" 30 "Reserved" 31 "Reserved" 32 "Inducing HDP longkey input" 33 "Reserved" 34 "Reserved" 35 "Reserved" 36 "Reserved" 37 "Reserved" 38 "Reserved" 39 "Reserved" 40 "Inform HDP can be activated" 41 "Reserved" 42 "Reserved" 43 "Reserved" 44 "Reserved" 45 "Reserved" 46 "Reserved" 47 "Reserved" 48 "Reserved" 49 "Reserved" 50 "Reserved" 51 "Reserved" 52 "Reserved" 53 "Reserved" 54 "Reserved" 55 "Reserved" 56 "Reserved" 57 "Reserved" 58 "Reserved" 59 "Reserved" 60 "Reserved" 61 "Reserved" 62 "Reserved" 63 "Reserved" 64 "Induce vehicle restart" 65 "Induce active connected service" 66 "Induce software update" 67 "Not in supported road type" 68 "Inform not in main lanes" 69 "Reserved" 70 "Reserved" 71 "Reserved" 72 "Reserved" 73 "Reserved" 74 "Reserved" 75 "Reserved" 76 "Reserved" 77 "Reserved" 78 "Reserved" 79 "Sensors in self-check" 80 "Not gear D" 81 "Induce off to AUTO STOP" 82 "Increase the distance" 83 "Decrease vehicle speed" 84 "Center the vehicle in lane" 85 "RSPA in operation" 86 "Induce ESC on" 87 "Reserved" 88 "Reserved" 89 "Reserved" 90 "Reserved" 91 "Reserved" 92 "Reserved" 93 "Reserved" 94 "Reserved" 95 "Reserved" 96 "Reserved" 97 "Reserved" 98 "Reserved" 99 "Reserved" 100 "Reserved" 101 "Reserved" 102 "Reserved" 103 "Reserved" 104 "Aggressive driving detected" 105 "Reserved" 106 "Reserved" 107 "Reserved" 108 "Reserved" 109 "Reserved" 110 "Reserved" 111 "Reserved" 112 "Inform deactivation in override" 113 "Reserved" 114 "Reserved" 115 "Reserved" 116 "Reserved" 117 "Reserved" 118 "Reserved" 119 "Reserved" 120 "Impact detected" 121 "Reserved" 122 "Reserved" 123 "Reserved" 124 "Reserved" 125 "Reserved" 126 "Reserved" 127 "Reserved" 128 "Accel input with hands-off" 129 "Gear shifter input detected" 130 "Brake input with hands-off" 131 "Vehicle start input detected" 132 "Stationary vehicle stop" 133 "Reserved" 134 "Reserved" 135 "Reserved" 136 "Reserved" 137 "Reserved" 138 "Reserved" 139 "Reserved" 140 "Reserved" 141 "Reserved" 142 "Reserved" 143 "Reserved" 144 "Supported road type ending" 145 "Detection of lane departure" 146 "Maximum speed exeeded" 147 "Reserved" 148 "Reserved" 149 "Reserved" 150 "Reserved" 151 "Reserved" 152 "Reserved" 153 "Reserved" 154 "Reserved" 155 "Reserved" 156 "Reserved" 157 "Reserved" 158 "Reserved" 159 "Reserved" 160 "HDP failure" 161 "Safety function activated" 162 "Reserved" 163 "Reserved" 164 "Reserved" 165 "Reserved" 166 "Reserved" 167 "Reserved" 168 "Reserved" 169 "Reserved" 170 "Reserved" 171 "Reserved" 172 "Reserved" 173 "Reserved" 174 "Reserved" 175 "Reserved" 176 "Camera obscured" 177 "Radar blocked" 178 "Lidar blocked" 179 "Reserved" 180 "Reserved" 181 "Reserved" 182 "Reserved" 183 "Reserved" 184 "Reserved" 185 "Reserved" 186 "Reserved" 187 "Reserved" 188 "Reserved" 189 "Reserved" 190 "Reserved" 191 "Reserved" 192 "Driver not in position" 193 "Oncoming vehicle detected" 194 "Emergency vehicle detected" 195 "Non-vehicle detected" 196 "Rain or snow detected" 197 "Slippery road" 198 "Reserved" 199 "Reserved" 200 "Reserved" 201 "Reserved" 202 "Reserved" 203 "Reserved" 204 "Reserved" 205 "Reserved" 206 "Reserved" 207 "Reserved" 208 "Road information is invalid" 209 "Lane not detected" 210 "Driver not detected" 211 "Pay attention to the driving" 212 "Reserved" 213 "Reserved" 214 "Reserved" 215 "Reserved" 216 "Reserved" 217 "Reserved" 218 "Reserved" 219 "Reserved" 220 "Reserved" 221 "Reserved" 222 "Reserved" 223 "Reserved" 240 "Low fuel" 241 "Low tire pressure" 242 "Door open" 243 "Trunk open" 244 "Hood open" 245 "Fasten seat belt" 246 "Parking brake activated" 247 "Reserved" 248 "Reserved" 249 "Reserved" 250 "Reserved" 251 "Reserved" 252 "Reserved" 253 "Reserved" 254 "Reserved" 255 "Reserved" ;
VAL_ 2273435650 HDP_HapticWarnReq 0 "No Warn" 1 "Request Haptic Warn - Level1" 2 "Request Haptic Warn - Level2" 3 "Reserved" ;
VAL_ 2273435650 HDP_ActvStaDis 0 "Not Active" 1 "Active" 2 "Reserved" 3 "Reserved" 4 "Reserved" 5 "Reserved" 6 "Reserved" 7 "Invalid" ;
VAL_ 2273435650 HDP_OpStaDisp 0 "None" 1 "Standby" 2 "Ready" 3 "Active(DDT)" 4 "Active(TD)" 5 "Active(MRM)" 6 "Active(EM)" 7 "Reserved" 8 "Reserved" 9 "Reserved" 10 "Reserved" 11 "Reserved" 12 "Reserved" 13 "Reserved" 14 "Reserved" 15 "Invalid" ;
VAL_ 2273435650 HDP_ObstSta 0 "No in-path obstacle detected" 1 "In-path obstacle detected (uncontrollable)" 2 "In-path obstacle detected (controllable:longitudinal)" 3 "Reserved" 4 "Reserved" 5 "Reserved" 6 "Reserved" 7 "Reserved" ;
VAL_ 2273435650 HDP_SysFlrDisp 0 "No HDP failure pop-up" 1 "HDP failure pop-up" 2 "HDP Camera blockage" 3 "HDP Radar blockage" 4 "HDP Lidar blockage" 5 "HDP ICC blockage" 6 "Reserved" 7 "Reserved" ;
VAL_ 2273435650 HDP_InhbtOffDispSta 0 "None" 1 "Inhibit change while HDP (H/Unit)" 2 "Reserved" 3 "Reserved" 4 "Reserved" 5 "Reserved" 6 "Reserved" 7 "Reserved" ;
VAL_ 2273435650 HDP_CtRoadSrfcDistVal 0 "0x0x0~0x5DC:value (*0.1m)" 1500 "0x0x0~0x5DC:value (*0.1m)" 1501 "0x5DD~0x7FD:Reserved" 2045 "0x5DD~0x7FD:Reserved" 2046 "Default (Not Display)" 2047 "Invalid" ;
VAL_ 2244046849 PCA_RrEquipSta 0 "Default" 1 "Off" 2 "Warning" 3 "Assist" 4 "Reserved" 5 "Reserved" 6 "Reserved" 7 "Invalid" ;
VAL_ 2244046849 PCA_SysFlrSta 0 "Normal" 1 "Unavailable by ESC" 2 "Unavailable by Camera" 3 "Unavailable by Ultrasonic" 4 "Unavailable by PCA-R" 5 "Unavailable by PCA-R/F/S" 6 "Reserved" 7 "Invalid" ;
VAL_ 2244046849 PCA_RrWrngLvlSta 0 "Normal" 1 "Ready" 2 "Warning" 3 "Assist" 4 "Assist Ended" 5 "Brake Hold" 6 "Reserved" 7 "Invalid" ;
VAL_ 2244046849 PCA_ModDis 0 "No Warning" 1 "PCA-R Off" 2 "PCA-R On" 3 "PCA-R Off, PCA-F/S Off" 4 "PCA-R On, PCA-F/S Off" 5 "PCA-R On, PCA-F/S On" 6 "Reserved" 7 "Invalid" ;
VAL_ 2244046849 PCA_WrngSndCtSta 0 "Normal" 1 "Warning" 2 "Reserved" 3 "Invalid" ;
VAL_ 2244046849 PCA_WrngSndLtSta 0 "Normal" 1 "Warning" 2 "Reserved" 3 "Invalid" ;
VAL_ 2244046849 PCA_WrngSndRtSta 0 "Normal" 1 "Warning" 2 "Reserved" 3 "Invalid" ;
VAL_ 2244046849 PCA_HptReq 0 "Haptic Off" 1 "Haptic On" 2 "Reserved" 3 "Invalid" ;
VAL_ 2244046849 PCA_BrkReq 0 "PCA Brake off" 1 "PCA Brake on" 2 "PCA Brake on (hold)" 3 "Error indicator" ;
VAL_ 2244046849 PCA_EpbReq 0 "Apply EPB" 1 "Stand by" 2 "Reserved" 3 "Invalid" ;
VAL_ 2244046849 PCA_DgrSta 0 "Default" 1 "Late" 2 "Normal" 3 "Reserved" 4 "Reserved" 5 "Reserved" 6 "Reserved" 7 "Invalid" ;
VAL_ 2244046849 ADAS_PRK_PDW_SysFlrSta 0 "No Display" 1 "Unable by Ultrasonic" 2 "PDW Failure" 3 "Error Indicator" ;
VAL_ 2244046850 ADAS_PRK_PDW_SwIndOnReq 0 "Indicator Off" 1 "Indicator On" 2 "Not Used" 3 "Error Indicator" ;
VAL_ 2244046850 PCA_RrEquipChkSta 0 "Default" 1 "Off" 2 "On" 3 "Invalid" ;
VAL_ 2244046850 PCA_FrWrngLvlSta 0 "Normal" 1 "Ready" 2 "Warning" 3 "Assist" 4 "Assist Ended" 5 "Reserved" 6 "Reserved" 7 "Invalid" ;
VAL_ 2244046850 PCA_LtWrngLvlSta 0 "Normal" 1 "Ready" 2 "Warning" 3 "Assist" 4 "Assist Ended" 5 "Reserved" 6 "Reserved" 7 "Invalid" ;
VAL_ 2244046850 ADAS_PRK_PDW_OptTyp 0 "None" 1 "PDW-R" 2 "PDW-FR" 3 "PDW-FSR" 4 "PDW-R (w/ 1st Corner Warning)" 5 "PDW-FR (w/ 1st Corner Warning)" 6 "Not Used" 7 "Error Indicator" ;
VAL_ 2244046850 PCA_RtWrngLvlSta 0 "Normal" 1 "Ready" 2 "Warning" 3 "Assist" 4 "Assist Ended" 5 "Reserved" 6 "Reserved" 7 "Invalid" ;
VAL_ 2244046850 PCA_LtWrngDis 0 "Off (No warning)" 1 "1st warning" 2 "2nd warning" 3 "3rd warning" ;
VAL_ 2244046850 PCA_RtWrngDis 0 "Off (No warning)" 1 "1st warning" 2 "2nd warning" 3 "3rd warning" ;
VAL_ 2244046850 PCA_LtRrWrngDis 0 "Off (No warning)" 1 "1st warning" 2 "2nd warning" 3 "3rd warning" ;
VAL_ 2244046850 PCA_RtRrWrngDis 0 "Off (No warning)" 1 "1st warning" 2 "2nd warning" 3 "3rd warning" ;
VAL_ 2244046850 PCA_RrFlrDis 0 "Normal" 1 "Unvailable by PCA-R" 2 "Reserved" 3 "Invalid" ;
VAL_ 2244046850 PCA_FrFlrDis 0 "Normal" 1 "Unvailable by PCA-F" 2 "Reserved" 3 "Invalid" ;
VAL_ 2244046850 PCA_LtFlrDis 0 "Normal" 1 "Unvailable by PCA-S" 2 "Reserved" 3 "Invalid" ;
VAL_ 2244046850 PCA_RtFlrDis 0 "Normal" 1 "Unvailable by PCA-S" 2 "Reserved" 3 "Invalid" ;
VAL_ 2244046850 ADAS_PRK_PDW_AutoOn_USM 0 "Default" 1 "Function Off" 2 "Function On" 3 "Invalid" ;
VAL_ 2244046850 PCA_FrSdEquipChkSta 0 "Default" 1 "Off" 2 "On" 3 "Invalid" ;
VAL_ 1030 APSM_SWVerMajor1 0 "0x0x0~0x7F:ASCII Code Value (HEX)" 127 "0x0x0~0x7F:ASCII Code Value (HEX)" ;
VAL_ 1030 APSM_SWVerMinor1 0 "0x0x0~0x7F:ASCII Code Value (HEX)" 127 "0x0x0~0x7F:ASCII Code Value (HEX)" ;
VAL_ 1030 APSM_SWVerMinor2 0 "0x0x0~0x7F:ASCII Code Value (HEX)" 127 "0x0x0~0x7F:ASCII Code Value (HEX)" ;
VAL_ 1031 APSM_FootrestPosition 0 "0x0x00~0xFE:POSITION" 254 "0x0x00~0xFE:POSITION" 255 "invalid" ;
VAL_ 1031 APSM_LegRestandAstPosition 0 "Default" 1 "Leg OPEN & not FORWARD" 2 "Else" 3 "Ivalid" ;
VAL_ 1031 APSM_FootRestandAstPosition 0 "Default" 1 "" 2 "Else" 3 "Ivalid" ;
VAL_ 1031 APSM_FootRestandLegRestPosition 0 "Default" 1 "OPEN&OPEN" 2 "Else" 3 "Ivalid" ;
VAL_ 1031 APSM_RearModeEnable 0 "Disable" 1 "Enable" 2 "Not Used" 3 "Error" ;
VAL_ 1031 APSM_AstStEsyAcsUSMSta 0 "Default Value" 1 "Off (Disable)" 2 "50mmOn (Enable)" 3 "75mmOn (Enable)" 4 "Reserved" 5 "Reserved" 6 "Reserved" 7 "Invalid" ;
VAL_ 1031 APSM_ReturnModeState 0 "Off" 1 "Stop" 2 "Moving" 3 "Finish" 4 "Only Rear" 5 "Reserved" 6 "Reserved" 7 "Invalid" ;
VAL_ 1031 APSM_RelaxModeState 0 "Off" 1 "Stop" 2 "Moving" 3 "Finish" 4 "Only Rear" 5 "Reserved" 6 "Reserved" 7 "Invalid" ;
VAL_ 1031 APSM_WalkInEnable 0 "Disable" 1 "Enable" 2 "Not Used" 3 "Error" ;
VAL_ 1031 APSM_LimSetSta 0 "Default" 1 "Initialized" 2 "Not Initialized" 3 "Reserved" ;
VAL_ 1031 APSM_MonitorModeState 0 "Off" 1 "Stop" 2 "Moving" 3 "Finish" 4 "RESERVED" 5 "RESERVED" 6 "RESERVED" 7 "Invalid" ;
VAL_ 1031 APSM_FootRest_Opt 0 "Default" 1 "Off" 2 "On(FootRest OPT)" 3 "Ivalid" ;
VAL_ 1031 APSM_RSE_Opt 0 "Default" 1 "Off" 2 "On(RSE OPT)" 3 "Ivalid" ;
VAL_ 1031 APSM_AstSlidePosition 0 "0x0x00~0xFE:POSITION" 254 "0x0x00~0xFE:POSITION" 255 "invalid" ;
VAL_ 1031 APSM_AstReclinePosition 0 "0x0x00~0xFE:POSITION" 254 "0x0x00~0xFE:POSITION" 255 "invalid" ;
VAL_ 543 ATS_AstStSldFwdBtn 0 "Default" 1 "Off" 2 "On" 3 "Reserved" ;
VAL_ 543 ATS_AstStSldBwdBtn 0 "Default" 1 "Off" 2 "On" 3 "Reserved" ;
VAL_ 543 ATS_AstStRclFwdBtn 0 "Default" 1 "Off" 2 "On" 3 "Reserved" ;
VAL_ 543 ATS_AstStRclBwdBtn 0 "Default" 1 "Off" 2 "On" 3 "Reserved" ;
VAL_ 543 ATS_AstStHgtUpBtn 0 "Default" 1 "Off" 2 "On" 3 "Reserved" ;
VAL_ 543 ATS_AstStHgtDnBtn 0 "Default" 1 "Off" 2 "On" 3 "Reserved" ;
VAL_ 543 ATS_AstStHRestUpBtn 0 "Default" 1 "Off" 2 "On" 3 "Reserved" ;
VAL_ 543 ATS_AstStHRestDnBtn 0 "Default" 1 "Off" 2 "On" 3 "Reserved" ;
VAL_ 543 ATS_AstStHRestFwdBtn 0 "Default" 1 "Off" 2 "On" 3 "Reserved" ;
VAL_ 543 ATS_AstStHRestBwdBtn 0 "Default" 1 "Off" 2 "On" 3 "Reserved" ;
VAL_ 543 ATS_AstStHRestFldBtn 0 "Default" 1 "Off" 2 "On" 3 "Reserved" ;
VAL_ 543 ATS_AstStHRestUnFldBtn 0 "Default" 1 "Off" 2 "On" 3 "Reserved" ;
VAL_ 543 ATS_AstStRseFwdBtn 0 "Default" 1 "Off" 2 "On" 3 "Reserved" ;
VAL_ 543 ATS_AstStRseBwdBtn 0 "Default" 1 "Off" 2 "On" 3 "Reserved" ;
VAL_ 543 ATS_AstStFRestFldBtn 0 "Default" 1 "Off" 2 "On" 3 "Reserved" ;
VAL_ 543 ATS_AstStFRestUnFldBtn 0 "Default" 1 "Off" 2 "On" 3 "Reserved" ;
VAL_ 543 ATS_AstTltUpBtn 0 "Default" 1 "Off" 2 "On" 3 "Reserved" ;
VAL_ 543 ATS_AstTltDnBtn 0 "Default" 1 "Off" 2 "On" 3 "Reserved" ;
VAL_ 623 ATS_ARSOpenCloseStatus 0 "Default" 1 "Open" 2 "Close" 3 "Invalid" ;
VAL_ 623 ATS_RLLumbarDefBtn 0 "Default" 1 "Off" 2 "On" 3 "Reserved" ;
VAL_ 623 ATS_RLLumbarLowBtn 0 "Default" 1 "Off" 2 "On" 3 "Reserved" ;
VAL_ 623 ATS_RLLumbarMidBtn 0 "Default" 1 "Off" 2 "On" 3 "Reserved" ;
VAL_ 623 ATS_RLLumbarUpBtn 0 "Default" 1 "Off" 2 "On" 3 "Reserved" ;
VAL_ 623 ATS_RLBolsterDefBtn 0 "Default" 1 "Off" 2 "On" 3 "Reserved" ;
VAL_ 623 ATS_RLBolsterInfSw 0 "Default" 1 "Off" 2 "On" 3 "Reserved" ;
VAL_ 623 ATS_RRLumbarDefBtn 0 "Default" 1 "Off" 2 "On" 3 "Reserved" ;
VAL_ 623 ATS_RRLumbarLowBtn 0 "Default" 1 "Off" 2 "On" 3 "Reserved" ;
VAL_ 623 ATS_RRLumbarMidBtn 0 "Default" 1 "Off" 2 "On" 3 "Reserved" ;
VAL_ 623 ATS_RRLumbarUpBtn 0 "Default" 1 "Off" 2 "On" 3 "Reserved" ;
VAL_ 623 ATS_RRBolsterDefBtn 0 "Default" 1 "Off" 2 "On" 3 "Reserved" ;
VAL_ 623 ATS_RRBolsterInfSw 0 "Default" 1 "Off" 2 "On" 3 "Reserved" ;
VAL_ 1141 Ast_SHVU_SeatOptSta 0 "Init" 1 "Heater only 2step" 2 "Heater only 3step" 3 "Vent only 2step" 4 "Vent only 3step" 5 "Heater and Vent 2step" 6 "Heater and Vent 3step" 7 "Invalid" ;
VAL_ 1141 Ast_SHVU_HtSwHiIndSta 0 "Off(Initial Value)" 1 "On" 2 "Not Used" 3 "Error Indicator" ;
VAL_ 1141 Ast_SHVU_HtSwMidIndSta 0 "Off(Initial Value)" 1 "On" 2 "Not Used" 3 "Error Indicator" ;
VAL_ 1141 Ast_SHVU_HtSwLowIndSta 0 "Off(Initial Value)" 1 "On" 2 "Not Used" 3 "Error Indicator" ;
VAL_ 1141 Ast_SHVU_VntSwHiIndSta 0 "Off(Initial Value)" 1 "On" 2 "Not Used" 3 "Error Indicator" ;
VAL_ 1141 Ast_SHVU_VntSwMidIndSta 0 "Off(Initial Value)" 1 "On" 2 "Not Used" 3 "Error Indicator" ;
VAL_ 1141 Ast_SHVU_VntSwLowIndSta 0 "Off(Initial Value)" 1 "On" 2 "Not Used" 3 "Error Indicator" ;
VAL_ 1141 Ast_SHVU_HtBlcUSMSta 0 "Default" 1 "Normal" 2 "Back 1" 3 "Back 2" 4 "Back 3" 5 "Cush 1" 6 "Cush 2" 7 "Cush 3" 8 "Reserved" 9 "Reserved" 10 "Reserved" 11 "Reserved" 12 "Reserved" 13 "Reserved" 14 "Reserved" 15 "Invalid" ;
VAL_ 1141 Ast_SHVU_SeatHtOperSta 0 "Init" 1 "Unused" 2 "Heater & Vent OFF" 3 "Vent Low" 4 "Vent Mid" 5 "Vent High" 6 "Heater Low" 7 "Heater Mid" 8 "Heater High" 9 "Unused" 10 "Unused" 11 "Unused" 12 "Unused" 13 "Unused" 14 "Unused" 15 "Invalid" ;
VAL_ 1141 Ast_SHVU_SeatOptSta_RHD 0 "Init" 1 "Heater only 2step" 2 "Heater only 3step" 3 "Vent only 2step" 4 "Vent only 3step" 5 "Heater and Vent 2step" 6 "Heater and Vent 3step" 7 "Invalid" ;
VAL_ 1141 Ast_SHVU_SeatHtOperSta_RHD 0 "Init" 1 "Unused" 2 "Heater & Vent OFF" 3 "Vent Low" 4 "Vent Mid" 5 "Vent High" 6 "Heater Low" 7 "Heater Mid" 8 "Heater High" 9 "Unused" 10 "Unused" 11 "Unused" 12 "Unused" 13 "Unused" 14 "Unused" 15 "Invalid" ;
VAL_ 1141 Ast_SHVU_HtSwHiIndSta_RHD 0 "Off(Initial Value)" 1 "On" 2 "Not Used" 3 "Error Indicator" ;
VAL_ 1141 Ast_SHVU_HtSwMidIndSta_RHD 0 "Off(Initial Value)" 1 "On" 2 "Not Used" 3 "Error Indicator" ;
VAL_ 1141 Ast_SHVU_HtSwLowIndSta_RHD 0 "Off(Initial Value)" 1 "On" 2 "Not Used" 3 "Error Indicator" ;
VAL_ 1141 Ast_SHVU_VntSwHiIndSta_RHD 0 "Off(Initial Value)" 1 "On" 2 "Not Used" 3 "Error Indicator" ;
VAL_ 1141 Ast_SHVU_VntSwMidIndSta_RHD 0 "Off(Initial Value)" 1 "On" 2 "Not Used" 3 "Error Indicator" ;
VAL_ 1141 Ast_SHVU_VntSwLowIndSta_RHD 0 "Off(Initial Value)" 1 "On" 2 "Not Used" 3 "Error Indicator" ;
VAL_ 1026 IMS_DrvrImsSwSetSta 0 "Off" 1 "On" 2 "Not Used" 3 "Error Indicator" ;
VAL_ 1026 IMS_DrvrImsSw1Sta 0 "Off" 1 "On" 2 "Not Used" 3 "Error Indicator" ;
VAL_ 1026 IMS_DrvrImsSw2Sta 0 "Off" 1 "On" 2 "Not Used" 3 "Error Indicator" ;
VAL_ 1026 IMS_DrvrImsSwSmrtSta 0 "Off" 1 "On" 2 "Not Used" 3 "Error Indicator" ;
VAL_ 1026 IMS_LHOSMirPlyBckSta 0 "Stop" 1 "Play 1" 2 "Play 2" 3 "Smart IMS" 4 "Profile1" 5 "Profile2" 6 "Guest" 7 "Invalid" ;
VAL_ 1026 IMS_GearPosRConfirmSta 0 "Off" 1 "On" 2 "Reserved" 3 "Invalid" ;
VAL_ 1027 Window_AsstPwrWdwAutoSwSta 0 "Off" 1 "On" 2 "Not Used" 3 "Error Indicator" ;
VAL_ 1027 Window_AsstPwrWdwUpSwSta 0 "Off" 1 "On" 2 "Not Used" 3 "Error Indicator" ;
VAL_ 1027 Window_AsstPwrWdwDnSwSta 0 "Off" 1 "On" 2 "Not Used" 3 "Error Indicator" ;
VAL_ 1027 Window_RrCrtSwSta 0 "Off" 1 "On" 2 "Not Used" 3 "Error Indicator" ;
VAL_ 1027 Window_RrLftPwrWdwAutoSwSta 0 "Off" 1 "On" 2 "Not Used" 3 "Error Indicator" ;
VAL_ 1027 Window_RrLftPwrWdwUpSwSta 0 "Off" 1 "On" 2 "Not Used" 3 "Error Indicator" ;
VAL_ 1027 Window_RrLftPwrWdwDnSwSta 0 "Off" 1 "On" 2 "Not Used" 3 "Error Indicator" ;
VAL_ 1027 Window_RrRtPwrWdwAutoSwSta 0 "Off" 1 "On" 2 "Not Used" 3 "Error Indicator" ;
VAL_ 1027 Window_RrRtPwrWdwUpSwSta 0 "Off" 1 "On" 2 "Not Used" 3 "Error Indicator" ;
VAL_ 1027 Window_RrRtPwrWdwDnSwSta 0 "Off" 1 "On" 2 "Not Used" 3 "Error Indicator" ;
VAL_ 1027 Window_PwrWdwMaintainSta 0 "Diasble" 1 "Enable" 2 "Not Used" 3 "Error Indicator" ;
VAL_ 1027 Window_PwrWdwMvInhbtSta 0 "Off" 1 "On" 2 "Not Used" 3 "Error Indicator" ;
VAL_ 1027 Window_WdwSafetyOpt 0 "Off" 1 "Drv Safety" 2 "Frt Safety" 3 "All Safety" 4 "Not Used" 5 "Not Used" 6 "Not Used" 7 "Error Indicator" ;
VAL_ 1027 Window_DrvPwrWdwAutoSwSta 0 "Off" 1 "On" 2 "Not Used" 3 "Error Indicator" ;
VAL_ 1027 Window_DrvPwrWdwUpSwSta 0 "Off" 1 "On" 2 "Not Used" 3 "Error Indicator" ;
VAL_ 1027 Window_DrvPwrWdwDnSwSta 0 "Off" 1 "On" 2 "Not Used" 3 "Error Indicator" ;
VAL_ 2214658049 EMS_Crc2Val 65535 "Signal Invalid (Message with unused CRC. CRC signal is transmitted fixed value)" ;
VAL_ 2214658049 EMS_AlvCnt2Val 255 "Signal Invalid (Message with unused Alive counter. Alive counter signal is transmitted fixed value)" ;
VAL_ 2214658049 ENG_BrkSwSta 0 "Brake switch is not pressed (OFF)" 1 "Brake switch is pressed (ON)" 2 "EMS does not support this function." 3 "Brake switch failure" ;
VAL_ 2214658049 ENG_EngClntTempVal 255 "Error indicator" ;
VAL_ 2214658049 ENG_MafCrctVal 128 "Error indicator" ;
VAL_ 2214658049 ENG_BattDscnctSta 0 "no battery disconnection detected" 1 "battery disconnection detected and failure memory erased" 2 "Not used" 3 "Error indicator" ;
VAL_ 2214658049 OBD_MilConfgVal 0 "no MIL, Failure Memory Management OBD-I" 1 "MIL Treatment OBD-I, Failure Memory Management OBD-I" 2 "MIL Treatment OBD-II, Exception" 3 "MIL Treatment OBD-II, Failure Memory Management OBD-II" 4 "MIL Treatment E-OBD, Failure Memory Management E-OBD" 5 "MIL Treatment K-OBD, Failure Memory Management K-OBD" ;
VAL_ 2214658049 ENG_EngSta 0 "Engine Stop" 1 "Cranking" 2 "Stalled" 3 "Running" 4 "Reserved" 5 "Reserved" 6 "Reserved" 7 "Fault" ;
VAL_ 2214658050 ENG_Ack4EngStpSta 0 "No acknowledgement" 1 "Acknowledgement engine stopped" 2 "Not used" 3 "Error indicator" ;
VAL_ 2214658050 ENG_AccDrvAlertDisp 0 "Default" 1 "Auto cruise Disengaged" 2 "No Auto cruise Engaged" 3 "Error indicator" ;
VAL_ 2214658050 ENG_ThrPosVal 32 "Idle (port value is learnt)" 245 "Throttle perpendicular" 255 "Throttle defective" ;
VAL_ 2214658050 ENG_OverDrvOffReq 0 "Normal operation" 1 "Over drive off request to TCU by the cruise control function" 2 "Not used" 3 "Error indicator" ;
VAL_ 2214658050 ENG_AccelPdlVal 0 "Accelerator Pedal not activated" 1022 "Accelerator Pedal fully activated" 1023 "Accelerator Pedal is defective (fail state) or Non-ETC system (APS is not installed), Error indicator" ;
VAL_ 2214658050 ENG_AccActSta 0 "Auto cruise control is not active" 1 "Auto cruise control is active" 2 "Not used" 3 "Error indicator" ;
VAL_ 2214658050 ACC_CrsMainSwLmpSta 0 "Cruise MAIN switch indication lamp turn OFF" 1 "Cruise MAIN switch indication lamp turn ON" 2 "Not used" 3 "Error indicator" ;
VAL_ 2214658050 ACC_CrsSetSwLmpSta 0 "Cruise SET switch indication lamp turn OFF" 1 "Cruise SET switch indication lamp turn ON" 2 "Not used" 3 "Error indicator" ;
VAL_ 2214658050 ENG_SoakTimeErrSta 0 "No Failure detected" 1 "Failure detected" 2 "Not used" 3 "Error indicator" ;
VAL_ 2214658050 ENG_CltchOpSta 0 "Clutch is not operating" 1 "Clutch is operating" 2 "Not used" 3 "Error indicator" ;
VAL_ 2214658050 EMS_BrkReq_Slope 0 "No Request" 1 "Brake Request" ;
VAL_ 2214658051 ENG_AppAccelPdlSta 0 "Accelerator pedal not pressed" 1 "Accelerator pedal pressed" 2 "Reserved" 3 "Accelerator pedal position sensor failure" ;
VAL_ 2214658051 ENG_BrkCtrlReq 0 "Brake control request is not active" 1 "Brake control request is active" 2 "Not used" 3 "Error indicator" ;
VAL_ 2214658051 ACC_DnShftCtrlReq 0 "Downshift control request is not active" 1 "Downshift request to 1st gear" 2 "Downshift request to 2nd gear" 3 "Downshift request to 3rd gear" 4 "Downshift request to 4th gear" 5 "Downshift request to 5th gear" 6 "Downshift request to 6th gear" 7 "Downshift request to 7th gear" 8 "Downshift request to 8th gear" 9 "Reserved" 10 "Reserved" 11 "Reserved" 12 "Reserved" 13 "Reserved" 14 "Reserved" 15 "Error indicator" ;
VAL_ 2214658051 ENG_ReprgmModRdySta 0 "Normal state" 1 "Reprogramming condition OK" 2 "Reprogramming condition NG" 3 "Reserved" ;
VAL_ 2214658051 ENG_AafOpnReq 0 "None" 1 "AAF open request" 2 "Not used" 3 "Error indicator" ;
VAL_ 2214658052 ENG_DclBrkCntrlReq 4095 "Error indicator" ;
VAL_ 2214658052 ENG_BstPrsrVal 4095 "Error indicator" ;
VAL_ 2214658052 ENG_EngOilTempVal 255 "Error indicator" ;
VAL_ 2214658052 ENG_DpfWrngSta 0 "DPF Normal State" 1 "DPF Warning State Level 1" 2 "DPF Warning State Level 2" 3 "Reserved" ;
VAL_ 2214658052 ENG_BattWrngLmpSta 0 "Battery Warning Lamp OFF" 1 "Battery Warning Lamp ON" 2 "Not used" 3 "Error indicator" ;
VAL_ 2214658052 ENG_OilPrsrWrngLmpSta 0 "Oil Pressure Warning Lamp OFF" 1 "Oil Pressure Warning Lamp ON" 2 "Not used" 3 "Error indicator" ;
VAL_ 2214658052 ENG_IsgInhbtLmpSta 0 "ISG Inhibit Lamp OFF" 1 "ISG Inhibit Lamp ON" 2 "Not used" 3 "Error indicator" ;
VAL_ 2307022852 ENG_EngTyp4 0 "Non-ETC" 1 "ETC" 2 "Not used" 3 "Error indicator" ;
VAL_ 2307022852 ENG_S_F 0 "AMS" 1 "ISG" 2 "Reserved" 3 "Reserved" ;
VAL_ 2307022852 ENG_S_F_GEN 0 "No AMS" 1 "1G Generation AMS" 2 "1.5G Generation AMS" 3 "2G Generation AMS" 4 "Reserved" 5 "Reserved" 6 "Reserved" 7 "Reserved" ;
VAL_ 2307022852 ENG_IsgDispDetail 0 "Off" 1 "Auto Stop conditions not met ; Engine system in control" 2 "Auto Stop conditions not met ; Battery charging" 3 "Auto Stop conditions not met ; Steep roadway" 4 "Auto Stop conditions not met ; Unavailable temperature" 5 "Auto Stop conditions not met ; Unavilable drive mode" 6 "Auto Stop conditions not met ; Hood is open" 7 "Auto Stop conditions not met ; Door is open" 8 "Auto Stop conditions not met ; Seatbelt is unfastened" 9 "Auto Stop conditions not met ; Steering wheel is not aligned" 10 "Auto Stop conditions not met ; Not reached to minimum speed" 11 "Auto Stop conditions not met ; Gear is not in D nor N (AT/DCT/AMT/CVT)" 12 "Auto Stop conditions not met ; Gear is not in neutral (MT)" 13 "Auto Stop conditions not met ; Press brake pedal more" 14 "Reserved" 15 "Reserved" 16 "Reserved" 17 "Auto Start ; Leading vehicle is driving away" 18 "Auto Stop conditions not met ; STOP sign recognized" 19 "Auto Stop conditions not met ; YIELD sign recognized" 20 "Auto Stop conditions not met ; Roundabout sign recognized" 21 "Reserved" 22 "Reserved" 23 "Reserved" 24 "Reserved" 25 "Reserved" 26 "Reserved" 27 "Reserved" 28 "Reserved" 29 "Reserved" 30 "Reserved" 31 "Error" ;
VAL_ 2307022852 ENG_EngTyp3 0 "FF" 1 "FR" 2 "Not used" 3 "Error indicator" ;
VAL_ 2307022852 ENG_KNK_Warning 0 "OFF" 1 "ON" ;
VAL_ 2307022852 ENG_OilLifeRatio 1 "Engine oil life ratio with % unit" 2 "Engine oil life ratio with % unit" 3 "Engine oil life ratio with % unit" 4 "Engine oil life ratio with % unit" 5 "Engine oil life ratio with % unit" 6 "Engine oil life ratio with % unit" 7 "Engine oil life ratio with % unit" 8 "Engine oil life ratio with % unit" 9 "Engine oil life ratio with % unit" 10 "Engine oil life ratio with % unit" 11 "Engine oil life ratio with % unit" 12 "Engine oil life ratio with % unit" 13 "Engine oil life ratio with % unit" 14 "Engine oil life ratio with % unit" 15 "Engine oil life ratio with % unit" 16 "Engine oil life ratio with % unit" 17 "Engine oil life ratio with % unit" 18 "Engine oil life ratio with % unit" 19 "Engine oil life ratio with % unit" 20 "Engine oil life ratio with % unit" 21 "Engine oil life ratio with % unit" 22 "Engine oil life ratio with % unit" 23 "Engine oil life ratio with % unit" 24 "Engine oil life ratio with % unit" 25 "Engine oil life ratio with % unit" 26 "Engine oil life ratio with % unit" 27 "Engine oil life ratio with % unit" 28 "Engine oil life ratio with % unit" 29 "Engine oil life ratio with % unit" 30 "Engine oil life ratio with % unit" 31 "Engine oil life ratio with % unit" 32 "Engine oil life ratio with % unit" 33 "Engine oil life ratio with % unit" 34 "Engine oil life ratio with % unit" 35 "Engine oil life ratio with % unit" 36 "Engine oil life ratio with % unit" 37 "Engine oil life ratio with % unit" 38 "Engine oil life ratio with % unit" 39 "Engine oil life ratio with % unit" 40 "Engine oil life ratio with % unit" 41 "Engine oil life ratio with % unit" 42 "Engine oil life ratio with % unit" 43 "Engine oil life ratio with % unit" 44 "Engine oil life ratio with % unit" 45 "Engine oil life ratio with % unit" 46 "Engine oil life ratio with % unit" 47 "Engine oil life ratio with % unit" 48 "Engine oil life ratio with % unit" 49 "Engine oil life ratio with % unit" 50 "Engine oil life ratio with % unit" 51 "Engine oil life ratio with % unit" 52 "Engine oil life ratio with % unit" 53 "Engine oil life ratio with % unit" 54 "Engine oil life ratio with % unit" 55 "Engine oil life ratio with % unit" 56 "Engine oil life ratio with % unit" 57 "Engine oil life ratio with % unit" 58 "Engine oil life ratio with % unit" 59 "Engine oil life ratio with % unit" 60 "Engine oil life ratio with % unit" 61 "Engine oil life ratio with % unit" 62 "Engine oil life ratio with % unit" 63 "Engine oil life ratio with % unit" 64 "Engine oil life ratio with % unit" 65 "Engine oil life ratio with % unit" 66 "Engine oil life ratio with % unit" 67 "Engine oil life ratio with % unit" 68 "Engine oil life ratio with % unit" 69 "Engine oil life ratio with % unit" 70 "Engine oil life ratio with % unit" 71 "Engine oil life ratio with % unit" 72 "Engine oil life ratio with % unit" 73 "Engine oil life ratio with % unit" 74 "Engine oil life ratio with % unit" 75 "Engine oil life ratio with % unit" 76 "Engine oil life ratio with % unit" 77 "Engine oil life ratio with % unit" 78 "Engine oil life ratio with % unit" 79 "Engine oil life ratio with % unit" 80 "Engine oil life ratio with % unit" 81 "Engine oil life ratio with % unit" 82 "Engine oil life ratio with % unit" 83 "Engine oil life ratio with % unit" 84 "Engine oil life ratio with % unit" 85 "Engine oil life ratio with % unit" 86 "Engine oil life ratio with % unit" 87 "Engine oil life ratio with % unit" 88 "Engine oil life ratio with % unit" 89 "Engine oil life ratio with % unit" 90 "Engine oil life ratio with % unit" 91 "Engine oil life ratio with % unit" 92 "Engine oil life ratio with % unit" 93 "Engine oil life ratio with % unit" 94 "Engine oil life ratio with % unit" 95 "Engine oil life ratio with % unit" 96 "Engine oil life ratio with % unit" 97 "Engine oil life ratio with % unit" 98 "Engine oil life ratio with % unit" 99 "Engine oil life ratio with % unit" 100 "Engine oil life ratio with % unit" 101 "Not used" 102 "Not used" 103 "Not used" 104 "Not used" 105 "Not used" 106 "Not used" 107 "Not used" 108 "Not used" 109 "Not used" 110 "Not used" 111 "Not used" 112 "Not used" 113 "Not used" 114 "Not used" 115 "Not used" 116 "Not used" 117 "Not used" 118 "Not used" 119 "Not used" 120 "Not used" 121 "Not used" 122 "Not used" 123 "Not used" 124 "Not used" 125 "Not used" 126 "Not used" 127 "Error" ;
VAL_ 2307022852 ENG_EngTyp2 0 "LPI" 1 "MPI" 2 "GDI" 3 "TGDI" 4 "CVVL" 5 "CVVD" 6 "PDI" 7 "FFV" 8 "TCI" 9 "VGT" 10 "Turbo" 11 "E-SC" 14 "Not used" 15 "Error indicator" ;
VAL_ 2307022852 ENG_OilLifeEna 0 "Oil life monitoring Not applied" 1 "Oil life monitoring Applied" 2 "Reserved" 3 "Error" ;
VAL_ 2307022852 ENG_OilLifeWarn 0 "No display" 1 "'Change engine oil' warning, 1st step (Low urgency)" 2 "'Change engine oil' warning, 2nd step (High urgency)" 3 "Error" ;
VAL_ 2307022852 ENG_PETyp 0 "Engine only" 1 "Engine+MHSG(48V)" 2 "Not used" 3 "Not used" ;
VAL_ 2307022852 ENG_EngTyp1 0 "epsilon(ε)" 1 "gamma(γ)" 2 "kappa(κ)" 3 "theta(θ)" 4 "nu(ν)" 5 "lambda(λ)" 6 "tau(τ)" 10 "S" 11 "A" 12 "R" 13 "U" 14 "D" 15 "Error indicator" ;
VAL_ 2315421185 AVN_ReadyToSendData 0 "None" 1 "Ready to Send data" 2 "Reserved" 3 "Invalid" ;
VAL_ 2315421185 AVN_ISKLearnState 0 "Default" 1 "Virgin" 2 "Learning" 3 "Learnt" 4 "Neutralizing" 5 "Neutralized" 6 "Reserved" 7 "Invalid" ;
VAL_ 2466563329 HU_ChgInCurrModSet 0 "Default" 1 "Maximum" 2 "Decreasing" 3 "Minimum" 4 "Reserved" 5 "Reserved" 6 "Reserved" 7 "Invalid" ;
VAL_ 2466563329 PushFeel_SET 0 "Off" 1 "On" 2 "Reserved" 3 "Invalid" ;
VAL_ 2466563329 HU_EnginePTSet 0 "Normal" 1 "Sport" 2 "ECO" 3 "Invalid" ;
VAL_ 2466563329 HU_DrivingModeSet 0 "Normal" 1 "Sport" 2 "ECO" 3 "Snow" 4 "Individual" 5 "SMART" 6 "Reserved" 7 "Invalid" ;
VAL_ 2466563329 SWRC_Sensitivity_SET 0 "Medium(default)" 1 "Low" 2 "High" 3 "Invalid" ;
VAL_ 2466563329 HU_EV_WinterMode 0 "Winter mode Off" 1 "Winter mode On" 2 "Reserved" 3 "Invalid" ;
VAL_ 2466563329 HU_4WDSet 0 "Normal" 1 "Sport" 2 "ECO" 3 "Invalid" ;
VAL_ 2466563329 C_SHVU_DTC_Mode 0 "Default" 1 "DTC Mode" 2 "Normal Mode" 3 "Invalid" ;
VAL_ 2466563329 HU_SusSet 0 "Normal" 1 "Sport" 2 "Comfort+" 3 "Invalid" ;
VAL_ 2466563329 HU_SteeringSet 0 "Normal" 1 "Sport" 2 "Reserved" 3 "Invalid" ;
VAL_ 2466563329 HU_TgSoc_ScChg_Set 0 "0x0x0~0xC8:PHY = HEX * 0.5" 200 "0x0x0~0xC8:PHY = HEX * 0.5" 201 "Reserved" 202 "Reserved" 203 "Reserved" 204 "Reserved" 205 "Reserved" 206 "Reserved" 207 "Reserved" 208 "Reserved" 209 "Reserved" 210 "Reserved" 211 "Reserved" 212 "Reserved" 213 "Reserved" 214 "Reserved" 215 "Reserved" 216 "Reserved" 217 "Reserved" 218 "Reserved" 219 "Reserved" 220 "Reserved" 221 "Reserved" 222 "Reserved" 223 "Reserved" 224 "Reserved" 225 "Reserved" 226 "Reserved" 227 "Reserved" 228 "Reserved" 229 "Reserved" 230 "Reserved" 231 "Reserved" 232 "Reserved" 233 "Reserved" 234 "Reserved" 235 "Reserved" 236 "Reserved" 237 "Reserved" 238 "Reserved" 239 "Reserved" 240 "Reserved" 241 "Reserved" 242 "Reserved" 243 "Reserved" 244 "Reserved" 245 "Reserved" 246 "Reserved" 247 "Reserved" 248 "Reserved" 249 "Reserved" 250 "Reserved" 251 "Reserved" 252 "Reserved" 253 "Reserved" 254 "Reserved" 255 "Invalid" ;
VAL_ 2466563329 HU_TgSoc_QcChg_Set 0 "0x0x0~0xC8:PHY = HEX * 0.5" 200 "0x0x0~0xC8:PHY = HEX * 0.5" 201 "Reserved" 202 "Reserved" 203 "Reserved" 204 "Reserved" 205 "Reserved" 206 "Reserved" 207 "Reserved" 208 "Reserved" 209 "Reserved" 210 "Reserved" 211 "Reserved" 212 "Reserved" 213 "Reserved" 214 "Reserved" 215 "Reserved" 216 "Reserved" 217 "Reserved" 218 "Reserved" 219 "Reserved" 220 "Reserved" 221 "Reserved" 222 "Reserved" 223 "Reserved" 224 "Reserved" 225 "Reserved" 226 "Reserved" 227 "Reserved" 228 "Reserved" 229 "Reserved" 230 "Reserved" 231 "Reserved" 232 "Reserved" 233 "Reserved" 234 "Reserved" 235 "Reserved" 236 "Reserved" 237 "Reserved" 238 "Reserved" 239 "Reserved" 240 "Reserved" 241 "Reserved" 242 "Reserved" 243 "Reserved" 244 "Reserved" 245 "Reserved" 246 "Reserved" 247 "Reserved" 248 "Reserved" 249 "Reserved" 250 "Reserved" 251 "Reserved" 252 "Reserved" 253 "Reserved" 254 "Reserved" 255 "Invalid" ;
VAL_ 2466563329 HU_TgSoc_GPSChg_Set 0 "0x0x0~0xC8:PHY = HEX * 0.5" 200 "0x0x0~0xC8:PHY = HEX * 0.5" 201 "Reserved" 202 "Reserved" 203 "Reserved" 204 "Reserved" 205 "Reserved" 206 "Reserved" 207 "Reserved" 208 "Reserved" 209 "Reserved" 210 "Reserved" 211 "Reserved" 212 "Reserved" 213 "Reserved" 214 "Reserved" 215 "Reserved" 216 "Reserved" 217 "Reserved" 218 "Reserved" 219 "Reserved" 220 "Reserved" 221 "Reserved" 222 "Reserved" 223 "Reserved" 224 "Reserved" 225 "Reserved" 226 "Reserved" 227 "Reserved" 228 "Reserved" 229 "Reserved" 230 "Reserved" 231 "Reserved" 232 "Reserved" 233 "Reserved" 234 "Reserved" 235 "Reserved" 236 "Reserved" 237 "Reserved" 238 "Reserved" 239 "Reserved" 240 "Reserved" 241 "Reserved" 242 "Reserved" 243 "Reserved" 244 "Reserved" 245 "Reserved" 246 "Reserved" 247 "Reserved" 248 "Reserved" 249 "Reserved" 250 "Reserved" 251 "Reserved" 252 "Reserved" 253 "Reserved" 254 "Reserved" 255 "Invalid" ;
VAL_ 2466563329 HU_UserApproval 0 "Initial Value" 1 "Approve" 2 "Reject" 3 "Start Trigger" 4 "Unrecognized Reject" 5 "Reserved" 6 "Reserved" 7 "Reserved" 8 "Reserved" 9 "Reserved" 10 "Reserved" 11 "Reserved" 12 "Reserved" 13 "Reserved" 14 "Reserved" 15 "Invalid" ;
VAL_ 2466563329 HU_OtaInfomationReq 0 "Initial" 1 "Vehicle S/W Version" 2 "What's New (Text Only)" 3 "Download progress" 4 "Update progress" 5 "Reserved" 6 "Reserved" 7 "Reserved" 8 "Reserved" 9 "Reserved" 10 "Reserved" 11 "Reserved" 12 "Reserved" 13 "Reserved" 14 "Reserved" 15 "Invalid" ;
VAL_ 1048 HeatedSteerWheel_StrWhlHtrSwSta 0 "Off" 1 "On" 2 "Reserved" 3 "Invalid" ;
VAL_ 1048 DriveTypeOption 0 "Left Handle Drive Type" 1 "Right Handle Drive Type" 3 "Error Indicator" ;
VAL_ 1048 Warn_RrLftSBRMATSwSta 0 "Off (UnSeated)" 1 "On (Seated)" 3 "Error Indicator" ;
VAL_ 1048 Warn_RrRhtSBRMATSwSta 0 "Off (UnSeated)" 1 "On (Seated)" 3 "Error Indicator" ;
VAL_ 1048 StrWheelHeatIndSta 0 "OFF" 1 "ON(Step1)" 2 "ON(Step2)" 3 "Error Indicator" ;
VAL_ 1048 Lamp_FootLampOnReq 0 "Off" 1 "On" 2 "Dim Out" 3 "Error Indicator" ;
VAL_ 1048 Lamp_MoodLampOnReq 0 "0%" 1 "FadeIn" 2 "MoodBrightPercent" 3 "FadeOut" 4 "100%" ;
VAL_ 1048 ICU_PowerAutoCutModSta 0 "Factory Mode (default)" 1 "Dealer Mode" 2 "Customer Mode" 3 "Error Indicator" ;
VAL_ 1048 ICU_SoCBattStaMsgReq 0 "Default" 1 "Alert" 2 "Warning" 3 "Invalid" ;
VAL_ 1048 C_ICUPowerAutoCutType 0 "Default" 1 "1st" 2 "2nd" 3 "3rd" ;
VAL_ 1048 Brake_SwSta_ICU 0 "Off" 1 "On" ;
VAL_ 1049 ICU_BS1ValFlagSta 0 "Valid condition" 1 "Invalid condition" ;
VAL_ 1049 ICU_BS1ErrRes 0 "opeartion correctly" 1 "response error" 3 "Error Indicator" ;
VAL_ 1029 ICU_BattMngAlert 0 "No Warning(Default)" 1 "Hazard On" 2 "Tail On" 3 "Hazard/Tail On" 4 "0x4~0xFE:Reserved" 254 "0x4~0xFE:Reserved" 255 "Invalid" ;
